VERSION "created by canmatrix"

NS_ :

BS_:

BU_: MD1_ECM ETC NODE_5 BSM_EBS RM_IRCS IC_Multic SGW BCM_NBM VCM NODE_31 ETS NODE_45 FCCU DICO NODE_72 FMReceiver SGW2 VCU ADCU MRGEN DTCO MBMS TPMS AI_CAID ELC ELC_R NODE_F7 BMS3 TUROLLA PCM SRR_Front_Left SRR_Rear_Right SRR_Front_Right SRR_Front SRR_Rear_Left ELFA3_S THERMOKING_M TMU_HP_Rr NODE_B1 NODE_B2 NODE_B3 NODE_B4 NODE_B5 NODE_B6 NODE_B7 NODE_B8 BMS2 NODE_B9 NODE_BA NODE_FC NODE_BB NODE_BC NODE_BE NODE_BD NODE_BF ACU NODE_C0 BMS1 NODE_C1 FCU NODE_C3 NODE_C4 NODE_EC NODE_C5 NODE_C6 NODE_C7 NODE_C8 VCU2 NODE_CA NODE_CB NODE_CD NODE_CE NODE_CF NODE_ED ST_ScanTool MASTER68_STD1 NODE_D1 NODE_F2 NODE_FD NODE_D2 MCSL NODE_EB NODE_D3 NODE_D4 NODE_D5 NODE_D6 VCCU NODE_D8 NODE_D9 NODE_F9 DiagTool NODE_DA NODE_DB NODE_DC NODE_DD NODE_DE NODE_DF NODE_E0 NODE_E1 NODE_E2 NODE_E9 NODE_E3 SAS NODE_FB NODE_F8 NODE_E6 ELFA3 NODE_F THERMOKING_D FMS MULTIC_S MULTIC_2 BMS4 BMS5 BMS6 BMS7 BMS8 BMS9 BMS10 BMS11 NODE_71

BO_ 2566870597 Telemat_3: 8 NODE_45
 SG_ DCDC_12V_ConvFault : 58|1@1+ (1,0) [0|1] ""  PCM
 SG_ OverheatingComprElec : 57|1@1+ (1,0) [0|1] ""  PCM
 SG_ AirDryerSts : 56|1@1+ (1,0) [0|1] ""  PCM
 SG_ LastDoor4CmdCode : 48|8@1+ (1,0) [0|250] ""  PCM
 SG_ LastDoor3CmdCode : 40|8@1+ (1,0) [0|250] ""  PCM
 SG_ LastDoor2CmdCode : 32|8@1+ (1,0) [0|250] ""  PCM
 SG_ LastDoor1CmdCode : 24|8@1+ (1,0) [0|250] ""  PCM
 SG_ Door4ActvInEmerMode : 23|1@1+ (1,0) [0|1] ""  PCM
 SG_ Door3ActvInEmerMode : 22|1@1+ (1,0) [0|1] ""  PCM
 SG_ Door2ActvInEmerMode : 21|1@1+ (1,0) [0|1] ""  PCM
 SG_ Door1ActvInEmerMode : 20|1@1+ (1,0) [0|1] ""  PCM
 SG_ Door4EmerInh : 19|1@1+ (1,0) [0|1] ""  PCM
 SG_ Door3EmerInh : 18|1@1+ (1,0) [0|1] ""  PCM
 SG_ Door2EmerInh : 17|1@1+ (1,0) [0|1] ""  PCM
 SG_ Door1EmerInh : 16|1@1+ (1,0) [0|1] ""  PCM
 SG_ EmerBtnSts : 13|1@1+ (1,0) [0|1] ""  PCM
 SG_ FipoSts : 11|2@1+ (1,0) [0|3] ""  PCM
 SG_ FaeSts : 9|2@1+ (1,0) [0|3] ""  PCM
 SG_ ParkBrkSwFullyApplied : 8|1@1+ (1,0) [0|1] ""  PCM
 SG_ HeatSysHighTempFault : 7|1@1+ (1,0) [0|1] ""  PCM
 SG_ HeatFuelLowLev : 6|1@1+ (1,0) [0|1] ""  PCM
 SG_ HeatLiquidLowLev : 5|1@1+ (1,0) [0|1] ""  PCM
 SG_ VehMode : 0|3@1+ (1,0) [0|7] ""  PCM

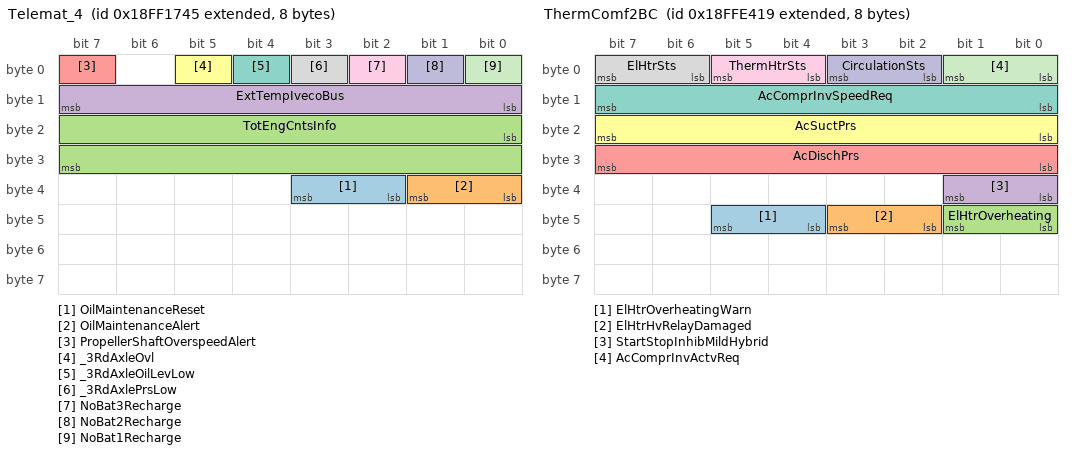
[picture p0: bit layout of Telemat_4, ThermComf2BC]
BO_ 2566854469 Telemat_4: 8 NODE_45
 SG_ OilMaintenanceReset : 34|2@1+ (1,0) [0|3] ""  PCM
 SG_ OilMaintenanceAlert : 32|2@1+ (1,0) [0|3] ""  PCM
 SG_ TotEngCntsInfo : 16|16@1+ (100,0) [0|6553500] "Cycles"  PCM
 SG_ ExtTempIvecoBus : 8|8@1+ (1,-40) [-40|210] "°C"  PCM
 SG_ PropellerShaftOverspeedAlert : 7|1@1+ (1,0) [0|1] ""  PCM
 SG_ _3RdAxleOvl : 5|1@1+ (1,0) [0|1] ""  PCM
 SG_ _3RdAxleOilLevLow : 4|1@1+ (1,0) [0|1] ""  PCM
 SG_ _3RdAxlePrsLow : 3|1@1+ (1,0) [0|1] ""  PCM
 SG_ NoBat3Recharge : 2|1@1+ (1,0) [0|1] ""  PCM
 SG_ NoBat2Recharge : 1|1@1+ (1,0) [0|1] ""  PCM
 SG_ NoBat1Recharge : 0|1@1+ (1,0) [0|1] ""  PCM

BO_ 2566906905 ThermComf2BC: 8 THERMOKING_M
 SG_ ElHtrOverheatingWarn : 44|2@1+ (1,0) [0|3] ""  PCM
 SG_ ElHtrHvRelayDamaged : 42|2@1+ (1,0) [0|3] ""  PCM
 SG_ ElHtrOverheating : 40|2@1+ (1,0) [0|3] ""  PCM
 SG_ StartStopInhibMildHybrid : 32|2@1+ (1,0) [0|3] ""  PCM
 SG_ AcDischPrs : 24|8@1+ (16,0) [0|4000] "kPa"  PCM
 SG_ AcSuctPrs : 16|8@1+ (16,0) [0|4000] "kPa"  PCM
 SG_ AcComprInvSpeedReq : 8|8@1+ (1,0) [0|250] "Hz"  PCM
 SG_ ElHtrSts : 6|2@1+ (1,0) [0|3] ""  PCM
 SG_ ThermHtrSts : 4|2@1+ (1,0) [0|3] ""  PCM
 SG_ CirculationSts : 2|2@1+ (1,0) [0|3] ""  PCM
 SG_ AcComprInvActvReq : 0|2@1+ (1,0) [0|3] ""  PCM

BO_ 2566846467 TRF1: 8 ETC
 SG_ TransmOilTemp1 : 32|16@1+ (0.03125,-273) [-273|1734.96875] "°C"  PCM

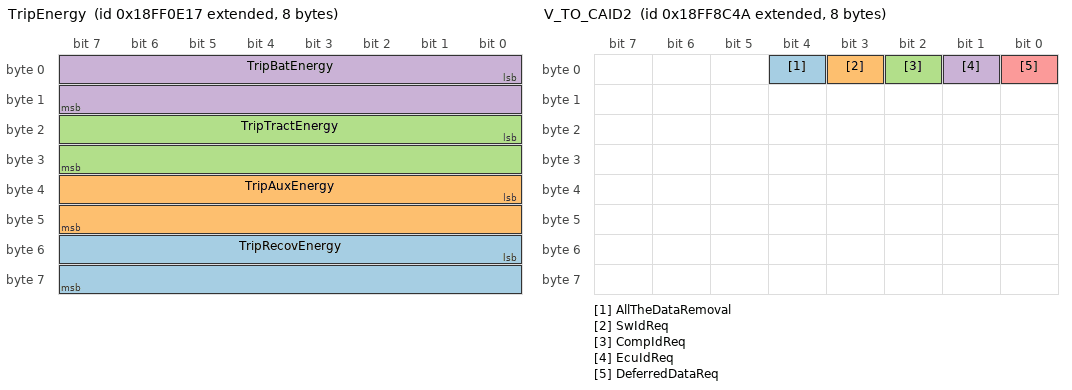
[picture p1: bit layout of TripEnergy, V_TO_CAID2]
BO_ 2566852119 TripEnergy: 8 IC_Multic
 SG_ TripRecovEnergy : 48|16@1+ (1,0) [0|65535] "kWh"  PCM
 SG_ TripAuxEnergy : 32|16@1+ (1,0) [0|65535] "kWh"  PCM
 SG_ TripTractEnergy : 16|16@1+ (1,0) [0|65535] "kWh"  PCM
 SG_ TripBatEnergy : 0|16@1+ (1,0) [0|65535] "kWh"  PCM

BO_ 2566856261 TripEnergy2: 8 NODE_45
 SG_ TripNet24VEnergy : 16|16@1+ (1,0) [0|64255] "kWh"  PCM
 SG_ TripAcEnergy : 0|16@1+ (1,0) [0|64255] "kWh"  PCM

BO_ 2566749463 TTS: 8 IC_Multic
 SG_ LdwSwdOff m3 : 60|3@1+ (1,0) [0|7] ""  PCM
 SG_ EngCompTemp m2 : 60|3@1+ (1,0) [0|7] ""  PCM
 SG_ SteerFluidLev m1 : 60|3@1+ (1,0) [0|7] ""  PCM
 SG_ FrontFogLight m0 : 60|3@1+ (1,0) [0|7] ""  PCM
 SG_ EscSwdOff m3 : 56|3@1+ (1,0) [0|7] ""  PCM
 SG_ Kneel m2 : 56|3@1+ (1,0) [0|7] ""  PCM
 SG_ EngCoolLev m1 : 56|3@1+ (1,0) [0|7] ""  PCM
 SG_ PosLightSideLight m0 : 56|3@1+ (1,0) [0|7] ""  PCM
 SG_ TcoInd m3 : 52|3@1+ (1,0) [0|7] ""  PCM
 SG_ Low m2 : 52|3@1+ (1,0) [0|7] ""  PCM
 SG_ EngOilLev_FD7D17 m1 : 52|3@1+ (1,0) [0|7] ""  PCM
 SG_ EngOil m0 : 52|3@1+ (1,0) [0|7] ""  PCM
 SG_ EbsTrail12 m3 : 48|3@1+ (1,0) [0|7] ""  PCM
 SG_ Raising m2 : 48|3@1+ (1,0) [0|7] ""  PCM
 SG_ EngOilTemp m1 : 48|3@1+ (1,0) [0|7] ""  PCM
 SG_ BatChgCond m0 : 48|3@1+ (1,0) [0|7] ""  PCM
 SG_ Airbag m3 : 44|3@1+ (1,0) [0|7] ""  PCM
 SG_ AdblueLev m2 : 44|3@1+ (1,0) [0|7] ""  PCM
 SG_ Malf_GenFail m1 : 44|3@1+ (1,0) [0|7] ""  PCM
 SG_ EngCoolTemp_FD7D17 m0 : 44|3@1+ (1,0) [0|7] ""  PCM
 SG_ AbsTrail12 m3 : 40|3@1+ (1,0) [0|7] ""  PCM
 SG_ BusStopBrk m2 : 40|3@1+ (1,0) [0|7] ""  PCM
 SG_ TireFail_Malf m1 : 40|3@1+ (1,0) [0|7] ""  PCM
 SG_ FuelLev m0 : 40|3@1+ (1,0) [0|7] ""  PCM
 SG_ BatPakCool m4 : 36|3@1+ (1,0) [0|7] ""  PCM
 SG_ TrailConn m3 : 36|3@1+ (1,0) [0|7] ""  PCM
 SG_ PramReq m2 : 36|3@1+ (1,0) [0|7] ""  PCM
 SG_ Windsh_WindshWasherFluid m1 : 36|3@1+ (1,0) [0|7] ""  PCM
 SG_ HatchOpen m0 : 36|3@1+ (1,0) [0|7] ""  PCM
 SG_ LimPerfElMot m4 : 32|3@1+ (1,0) [0|7] ""  PCM
 SG_ Acc m3 : 32|3@1+ (1,0) [0|7] ""  PCM
 SG_ StopReq m2 : 32|3@1+ (1,0) [0|7] ""  PCM
 SG_ WornBrkLin m1 : 32|3@1+ (1,0) [0|7] ""  PCM
 SG_ BrkFail_BrkSysMalf m0 : 32|3@1+ (1,0) [0|7] ""  PCM
 SG_ BatPakTemp m4 : 28|3@1+ (1,0) [0|7] ""  PCM
 SG_ Aebs m3 : 28|3@1+ (1,0) [0|7] ""  PCM
 SG_ Artic m2 : 28|3@1+ (1,0) [0|7] ""  PCM
 SG_ AntiLckBrkSysFail m1 : 28|3@1+ (1,0) [0|7] ""  PCM
 SG_ ParkBrk m0 : 28|3@1+ (1,0) [0|7] ""  PCM
 SG_ highVsysCaution m4 : 24|3@1+ (1,0) [0|7] ""  PCM
 SG_ LaneDepInd m3 : 24|3@1+ (1,0) [0|7] ""  PCM
 SG_ BrkLight m2 : 24|3@1+ (1,0) [0|7] ""  PCM
 SG_ TransmFail_Malf m1 : 24|3@1+ (1,0) [0|7] ""  PCM
 SG_ ProvDisOrHandiPers m0 : 24|3@1+ (1,0) [0|7] ""  PCM
 SG_ BatPak m4 : 20|3@1+ (1,0) [0|7] ""  PCM
 SG_ Ebs m3 : 20|3@1+ (1,0) [0|7] ""  PCM
 SG_ EscInd m2 : 20|3@1+ (1,0) [0|7] ""  PCM
 SG_ TransmFluidTemp m1 : 20|3@1+ (1,0) [0|7] ""  PCM
 SG_ HazardWarn m0 : 20|3@1+ (1,0) [0|7] ""  PCM
 SG_ MuxSys m4 : 16|3@1+ (1,0) [0|7] ""  PCM
 SG_ SeatBelt m3 : 16|3@1+ (1,0) [0|7] ""  PCM
 SG_ EngEmisSysFailMil m2 : 16|3@1+ (1,0) [0|7] ""  PCM
 SG_ ServCallForMaint m1 : 16|3@1+ (1,0) [0|7] ""  PCM
 SG_ TurnSigs m0 : 16|3@1+ (1,0) [0|7] ""  PCM
 SG_ AdblueTamp m4 : 12|3@1+ (1,0) [0|7] ""  PCM
 SG_ FuelFiltDiffPrs m3 : 12|3@1+ (1,0) [0|7] ""  PCM
 SG_ Ret m2 : 12|3@1+ (1,0) [0|7] ""  PCM
 SG_ Eng_Mil m1 : 12|3@1+ (1,0) [0|7] ""  PCM
 SG_ LowBeamDipBeam m0 : 12|3@1+ (1,0) [0|7] ""  PCM
 SG_ ElMotFails m4 : 8|3@1+ (1,0) [0|7] ""  PCM
 SG_ AirFiltClog m3 : 8|3@1+ (1,0) [0|7] ""  PCM
 SG_ HtCtrl m2 : 8|3@1+ (1,0) [0|7] ""  PCM
 SG_ ParkHeat m1 : 8|3@1+ (1,0) [0|7] ""  PCM
 SG_ HighBeamMainBeam m0 : 8|3@1+ (1,0) [0|7] ""  PCM
 SG_ EngEmisFilt m4 : 4|3@1+ (1,0) [0|7] ""  PCM
 SG_ AuxAirPrs m3 : 4|3@1+ (1,0) [0|7] ""  PCM
 SG_ SteerFail m2 : 4|3@1+ (1,0) [0|7] ""  PCM
 SG_ RearFogLight m1 : 4|3@1+ (1,0) [0|7] ""  PCM
 SG_ CoolAc m0 : 4|3@1+ (1,0) [0|7] ""  PCM
 SG_ TtBlkId M : 0|4@1+ (1,0) [0|15] ""  PCM

BO_ 2566884426 V_TO_CAID2: 8 PCM
 SG_ AllTheDataRemoval : 4|1@1+ (1,0) [0|1] "" Vector__XXX
 SG_ SwIdReq : 3|1@1+ (1,0) [0|1] "" Vector__XXX
 SG_ CompIdReq : 2|1@1+ (1,0) [0|1] "" Vector__XXX
 SG_ EcuIdReq : 1|1@1+ (1,0) [0|1] "" Vector__XXX
 SG_ DeferredDataReq : 0|1@1+ (1,0) [0|1] "" Vector__XXX

BO_ 2566877568 VCU2MUX_FC: 8 VCU
 SG_ FCU2_8_FC_Consump : 48|16@1+ (0.01,0) [0|655.35] "mg"  PCM
 SG_ FillAuthorizDueToSafetyReas : 47|1@1+ (1,0) [0|1] ""  PCM
 SG_ NrTanksOpenH2_RdyToProvide2FC : 44|3@1+ (1,0) [0|7] ""  PCM
 SG_ FC_Mode_ReqBySupervisor : 40|4@1+ (1,0) [0|15] ""  PCM
 SG_ HV_DC_Link_Sts : 39|1@1+ (1,0) [0|1] ""  PCM
 SG_ LimpHomeMode : 36|1@1+ (1,0) [0|1] ""  PCM
 SG_ H2_Circuit_Sts : 32|4@1+ (1,0) [0|15] ""  PCM
 SG_ FC_Sts_SupervisorSide : 28|4@1+ (1,0) [0|15] ""  PCM
 SG_ H2_Sensor4LeakageSts : 27|1@1+ (1,0) [0|1] ""  PCM
 SG_ H2_Sensor3LeakageSts : 26|1@1+ (1,0) [0|1] ""  PCM
 SG_ H2_Sensor2LeakageSts : 25|1@1+ (1,0) [0|1] ""  PCM
 SG_ H2_Sensor1LeakageSts : 24|1@1+ (1,0) [0|1] ""  PCM
 SG_ H2ConctValExc4Pc_RslR134 : 23|1@1+ (1,0) [0|1] ""  PCM
 SG_ H2ConctValExc3Pc_AwlR134 : 22|1@1+ (1,0) [0|1] ""  PCM
 SG_ FC_Act_DeacStsDashbDisplay : 20|2@1+ (1,0) [0|3] ""  PCM
 SG_ VCU_TkClosEmrgShtDwnRq_FC1 : 19|1@1+ (1,0) [0|1] ""  PCM
 SG_ VCU_HV_FtEmrgShtDwnRq_FC1 : 18|1@1+ (1,0) [0|1] ""  PCM
 SG_ FCU2_7_FC_StopState : 16|2@1+ (1,0) [0|3] ""  PCM
 SG_ FCU2_7_FC_StopImposs : 14|2@1+ (1,0) [0|3] ""  PCM
 SG_ FCU2_5_FC_Fault : 13|1@1+ (1,0) [0|1] ""  PCM
 SG_ FCU2_5_FC_Shutdown : 11|2@1+ (1,0) [0|3] ""  PCM
 SG_ FCU2_5_FC_LoadPermmit : 10|1@1+ (1,0) [0|1] ""  PCM
 SG_ FCU2_5_FC_Startup : 8|2@1+ (1,0) [0|3] ""  PCM
 SG_ VCU_FC_CoolantLevLow : 7|1@1+ (1,0) [0|1] ""  PCM
 SG_ FuelCellSwON_OFF : 6|1@1+ (1,0) [0|1] ""  PCM
 SG_ FCU2_H2TankValveEmrgClos : 5|1@1+ (1,0) [0|1] ""  PCM
 SG_ FCU2_HV_InterlockReactRq : 4|1@1+ (1,0) [0|1] ""  PCM
 SG_ FCU2_5_H2FaultLamp : 3|1@1+ (1,0) [0|1] ""  PCM
 SG_ FCU2_8_H2LeakLamp : 1|2@1+ (1,0) [0|3] ""  PCM

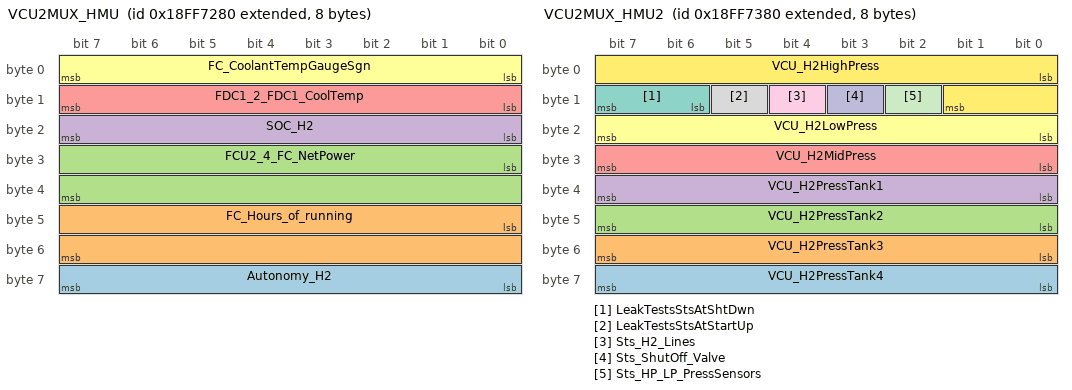
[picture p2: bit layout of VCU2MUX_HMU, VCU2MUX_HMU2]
BO_ 2566877824 VCU2MUX_HMU: 8 VCU
 SG_ Autonomy_H2 : 56|8@1+ (2,0) [0|510] "km"  PCM
 SG_ FC_Hours_of_running : 40|16@1+ (1,0) [0|65536] "h"  PCM
 SG_ FCU2_4_FC_NetPower : 24|16@1+ (0.1,0) [0|255] "kW"  PCM
 SG_ SOC_H2 : 16|8@1+ (0.4,0) [0|100] "%"  PCM
 SG_ FDC1_2_FDC1_CoolTemp : 8|8@1+ (1,-40) [-40|200] "°C"  PCM
 SG_ FC_CoolantTempGaugeSgn : 0|8@1+ (0.5,-30) [-30|97.5] "°C"  PCM

BO_ 2566878080 VCU2MUX_HMU2: 8 VCU
 SG_ VCU_H2PressTank4 : 56|8@1+ (1.5,0) [0|379.5] "bar"  PCM
 SG_ VCU_H2PressTank3 : 48|8@1+ (1.5,0) [0|379.5] "bar"  PCM
 SG_ VCU_H2PressTank2 : 40|8@1+ (1.5,0) [0|379.5] "bar"  PCM
 SG_ VCU_H2PressTank1 : 32|8@1+ (1.5,0) [0|379.5] "bar"  PCM
 SG_ VCU_H2MidPress : 24|8@1+ (0.2,0) [0|51] "bar"  PCM
 SG_ VCU_H2LowPress : 16|8@1+ (0.2,0) [0|51] "bar"  PCM
 SG_ LeakTestsStsAtShtDwn : 14|2@1+ (1,0) [0|3] ""  PCM
 SG_ LeakTestsStsAtStartUp : 13|1@1+ (1,0) [0|1] ""  PCM
 SG_ Sts_H2_Lines : 12|1@1+ (1,0) [0|1] ""  PCM
 SG_ Sts_ShutOff_Valve : 11|1@1+ (1,0) [0|1] ""  PCM
 SG_ Sts_HP_LP_PressSensors : 10|1@1+ (1,0) [0|1] ""  PCM
 SG_ VCU_H2HighPress : 0|10@1+ (0.5,0) [0|511.5] "bar"  PCM

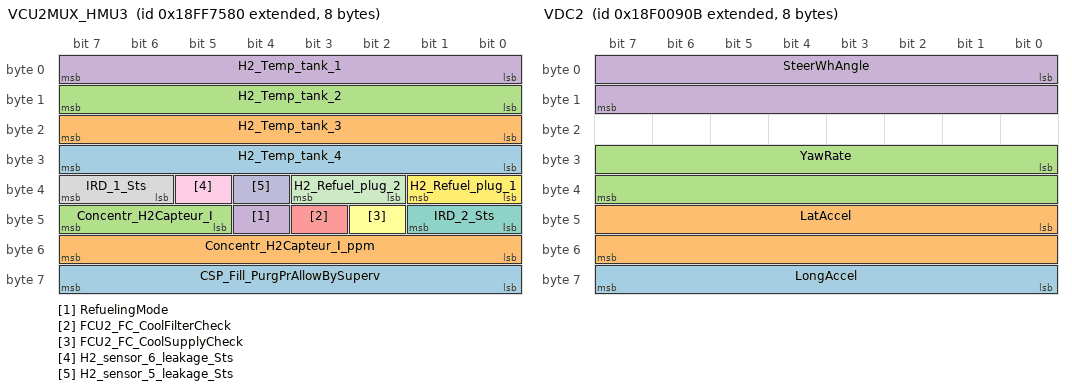
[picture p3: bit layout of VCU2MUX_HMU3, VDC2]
BO_ 2566878592 VCU2MUX_HMU3: 8 VCU
 SG_ CSP_Fill_PurgPrAllowBySuperv : 56|8@1+ (1,0) [0|250] ""  PCM
 SG_ Concentr_H2Capteur_I_ppm : 48|8@1+ (1,0) [0|250] ""  PCM
 SG_ Concentr_H2Capteur_I : 45|3@1+ (1,0) [0|7] ""  PCM
 SG_ RefuelingMode : 44|1@1+ (1,0) [0|1] ""  PCM
 SG_ FCU2_FC_CoolFilterCheck : 43|1@1+ (1,0) [0|1] ""  PCM
 SG_ FCU2_FC_CoolSupplyCheck : 42|1@1+ (1,0) [0|1] ""  PCM
 SG_ IRD_2_Sts : 40|2@1+ (1,0) [0|3] ""  PCM
 SG_ IRD_1_Sts : 38|2@1+ (1,0) [0|3] ""  PCM
 SG_ H2_sensor_6_leakage_Sts : 37|1@1+ (1,0) [0|1] ""  PCM
 SG_ H2_sensor_5_leakage_Sts : 36|1@1+ (1,0) [0|1] ""  PCM
 SG_ H2_Refuel_plug_2 : 34|2@1+ (1,0) [0|3] ""  PCM
 SG_ H2_Refuel_plug_1 : 32|2@1+ (1,0) [0|3] ""  PCM
 SG_ H2_Temp_tank_4 : 24|8@1+ (1,-40) [-40|200] "°C"  PCM
 SG_ H2_Temp_tank_3 : 16|8@1+ (1,-40) [-40|200] "°C"  PCM
 SG_ H2_Temp_tank_2 : 8|8@1+ (1,-40) [-40|200] "°C"  PCM
 SG_ H2_Temp_tank_1 : 0|8@1+ (1,-40) [-40|200] "°C"  PCM

BO_ 2566803211 VDC1: 8 BSM_EBS
 SG_ VdcFullyOp : 2|2@1+ (1,0) [0|3] ""  PCM
 SG_ VdcInfoSig : 0|2@1+ (1,0) [0|3] ""  PCM

BO_ 2565867787 VDC2: 8 BSM_EBS
 SG_ LongAccel : 56|8@1+ (0.1,-12.5) [-12.5|12.5] "m/s²"  PCM
 SG_ LatAccel : 40|16@1+ (0.00048828125,-15.687) [-15.687|15.687] "m/s²"  PCM
 SG_ YawRate : 24|16@1+ (0.0001220703125,-3.92) [-3.92|3.92] "rad/s"  PCM
 SG_ SteerWhAngle : 0|16@1+ (0.0009765625,-31.374) [-31.374|31.374] "rad"  PCM

BO_ 2566832622 VDHR: 8 DTCO
 SG_ TripDistHr : 32|32@1+ (5,0) [0|21055406075] "m"  PCM
 SG_ TotVehDistHr : 0|32@1+ (5,0) [0|21055406075] "m"  PCM

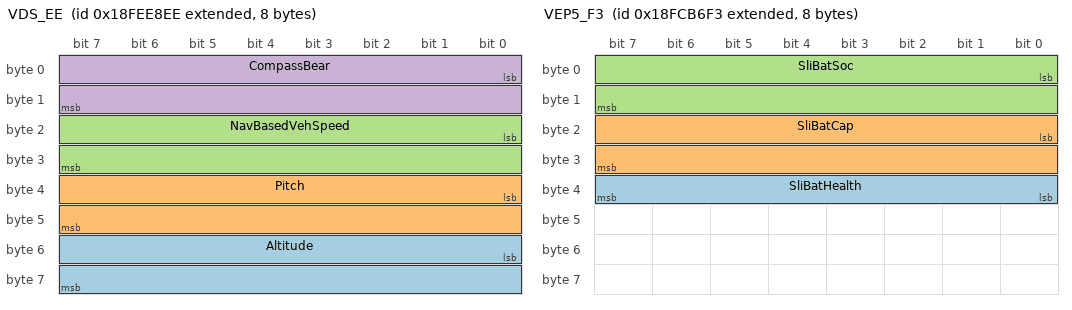
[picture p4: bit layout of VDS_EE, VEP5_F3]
BO_ 2566842606 VDS_EE: 8 DTCO
 SG_ Altitude : 48|16@1+ (0.125,-2500) [-2500|5531.875] "m"  PCM
 SG_ Pitch : 32|16@1+ (0.0078125,-200) [-200|301.99] "deg"  PCM
 SG_ NavBasedVehSpeed : 16|16@1+ (0.00390625,0) [0|250.996] "km/h"  PCM
 SG_ CompassBear : 0|16@1+ (0.0078125,0) [0|501.99] "deg"  PCM

BO_ 2566846208 VEP1_00: 8 MD1_ECM
 SG_ BatPot_PwrIn1 : 32|16@1+ (0.05,0) [0|3212.75] "V"  PCM

BO_ 2566846451 VEP1_F3: 8 MBMS
 SG_ BatPot_PwrIn1_FEF7F3 : 32|16@1+ (0.05,0) [0|3212.75] "V"  PCM

BO_ 2566804211 VEP3_F3: 8 MBMS
 SG_ SliBat1NetCurHr : 16|16@1+ (0.05,-1600) [-1600|1612.75] "A"  PCM

BO_ 2566698739 VEP5_F3: 8 MBMS
 SG_ SliBatHealth : 32|8@1+ (0.5,0) [0|125] "%"  PCM
 SG_ SliBatCap : 16|16@1+ (1,0) [0|64255] "Ah"  PCM
 SG_ SliBatSoc : 0|16@1+ (0.0025,0) [0|160.6375] "%"  PCM

BO_ 2566843630 VI_EE: 18 DTCO
 SG_ Vin : 0|8@1+ (1,0) [0|255] "ASCII"  PCM

BO_ 2566845212 VP1_1C: 8 PCM
 SG_ Long : 32|32@1+ (1E-007,-210) [-210|211.1081215] "deg" Vector__XXX
 SG_ Lat : 0|32@1+ (1E-007,-210) [-210|211.1081215] "deg" Vector__XXX

BO_ 2566845422 VP1_EE: 8 DTCO
 SG_ Long_FEF3EE : 32|32@1+ (1E-007,-210) [-210|211.1081215] "deg"  PCM
 SG_ Lat_FEF3EE : 0|32@1+ (1E-007,-210) [-210|211.1081215] "deg"  PCM

BO_ 2566842927 VW_2F_Test: 8 ELC
 SG_ Axle_Weight_5 m4 : 8|16@1+ (0.5,0) [0|32127.5] "kg"  PCM
 SG_ Axle_Weight_4 m3 : 8|16@1+ (0.5,0) [0|32127.5] "kg"  PCM
 SG_ Axle_Weight_3 m2 : 8|16@1+ (0.5,0) [0|32127.5] "kg"  PCM
 SG_ Axle_Weight_2 m1 : 8|16@1+ (0.5,0) [0|32127.5] "kg"  PCM
 SG_ Axle_Weight_1 m0 : 8|16@1+ (0.5,0) [0|32127.5] "kg"  PCM
 SG_ Axle_Location M : 4|4@1+ (1,0) [0|15] ""  PCM

BO_ 2566842944 VW_40_Test: 8 ELC_R
 SG_ Axle_Weight_5_FEEA40 m4 : 8|16@1+ (0.5,0) [0|32127.5] "kg"  PCM
 SG_ Axle_Weight_4_FEEA40 m3 : 8|16@1+ (0.5,0) [0|32127.5] "kg"  PCM
 SG_ Axle_Weight_3_FEEA40 m2 : 8|16@1+ (0.5,0) [0|32127.5] "kg"  PCM
 SG_ Axle_Weight_2_FEEA40 m1 : 8|16@1+ (0.5,0) [0|32127.5] "kg"  PCM
 SG_ Axle_Weight_1_FEEA40 m0 : 8|16@1+ (0.5,0) [0|32127.5] "kg"  PCM
 SG_ Axle_Location_FEEA40 M : 4|4@1+ (1,0) [0|15] ""  PCM

BO_ 2566848256 WFI: 8 MD1_ECM
 SG_ WaterInFuelInd1 : 0|2@1+ (1,0) [0|3] ""  PCM

BO_ 2349075360 XBR_A0_0B: 8 MRGEN
 SG_ XbrMsgCnt : 56|4@1+ (1,0) [0|15] "count"  PCM,BSM_EBS

BO_ 2566845436 VP_FC: 8 NODE_FC
 SG_ Long_FEF3FC : 32|32@1+ (1E-007,-210) [-210|211.1081215] "deg"  PCM
 SG_ Lat_FEF3FC : 0|32@1+ (1E-007,-210) [-210|211.1081215] "deg"  PCM

BO_ 2565472330 RQST_4A_00: 3 PCM
 SG_ PgnRqst_4A_00 : 0|24@1+ (1,0) [0|16777215] ""  MD1_ECM

BO_ 2565482314 RQST_4A_27: 3 PCM
 SG_ PgnRqst_4A_27 : 0|24@1+ (1,0) [0|16777215] ""  VCM

BO_ 2565478218 RQST_4A_17: 3 PCM
 SG_ PgnRqst_4A_17 : 0|24@1+ (1,0) [0|16777215] ""  IC_Multic

BO_ 2565473098 RQST_4A_03: 3 PCM
 SG_ PgnRqst_4A_03 : 0|24@1+ (1,0) [0|16777215] ""  ETC

BO_ 2565475146 RQST_4A_0B: 3 PCM
 SG_ PgnRqst_4A_0B : 0|24@1+ (1,0) [0|16777215] ""  BSM_EBS

BO_ 2565479754 RQST_4A_1D: 3 PCM
 SG_ PgnRqst_4A_1D : 0|24@1+ (1,0) [0|16777215] ""  SGW

BO_ 2565486666 RQST_4A_38: 3 PCM
 SG_ PgnRqst_4A_38 : 0|24@1+ (1,0) [0|16777215] ""  ETS

BO_ 2565504586 RQST_4A_7E: 3 PCM
 SG_ PgnRqst_4A_7E : 0|24@1+ (1,0) [0|16777215] ""  SGW2

BO_ 2565512778 RQST_4A_9E: 3 PCM
 SG_ PgnRqst_4A_9E : 0|24@1+ (1,0) [0|16777215] ""  ADCU

BO_ 2565513290 RQST_4A_A0: 3 PCM
 SG_ PgnRqst_4A_A0 : 0|24@1+ (1,0) [0|16777215] ""  MRGEN

BO_ 2565480778 RQST_4A_21: 3 PCM
 SG_ PgnRqst_4A_21 : 0|24@1+ (1,0) [0|16777215] ""  BCM_NBM

BO_ 2565496394 RQST_4A_5E: 3 PCM
 SG_ PgnRqst_4A_5E : 0|24@1+ (1,0) [0|16777215] ""  AI_CAID

BO_ 2565495370 RQST_4A_5A: 3 PCM
 SG_ PgnRqst_4A_5A : 0|24@1+ (1,0) [0|16777215] ""  DICO

BO_ 2565484362 RQST_4A_2F: 3 PCM
 SG_ PgnRqst_4A_2F : 0|24@1+ (1,0) [0|16777215] ""  ELC

BO_ 2565488714 RQST_4A_40: 3 PCM
 SG_ PgnRqst_4A_40 : 0|24@1+ (1,0) [0|16777215] ""  ELC_R

BO_ 2565535562 RQST_4A_F7: 3 PCM
 SG_ PgnRqst_4A_F7 : 0|24@1+ (1,0) [0|16777215] ""  NODE_F7

BO_ 2565535306 RQST_4A_F6: 3 PCM
 SG_ PgnRqst_4A_F6 : 0|24@1+ (1,0) [0|16777215] ""  BMS3

BO_ 2565534538 RQST_4A_F3: 3 PCM
 SG_ PgnRqst_4A_F3 : 0|24@1+ (1,0) [0|16777215] ""  MBMS

BO_ 2565491018 RQST_4A_49: 3 PCM
 SG_ PgnRqst_4A_49 : 0|24@1+ (1,0) [0|16777215] ""  FCCU

BO_ 2565476426 RQST_4A_10: 3 PCM
 SG_ PgnRqst_4A_10 : 0|24@1+ (1,0) [0|16777215] ""  RM_IRCS

BO_ 2565484106 RQST_4A_2E: 3 PCM
 SG_ PgnRqst_4A_2E : 0|24@1+ (1,0) [0|16777215] ""  TUROLLA

BO_ 2565509194 RQST_4A_90: 3 PCM
 SG_ PgnRqst_4A_90 : 0|24@1+ (1,0) [0|16777215] ""  SRR_Front_Left

BO_ 2565509450 RQST_4A_91: 3 PCM
 SG_ PgnRqst_4A_91 : 0|24@1+ (1,0) [0|16777215] ""  SRR_Rear_Right

BO_ 2565509706 RQST_4A_92: 3 PCM
 SG_ PgnRqst_4A_92 : 0|24@1+ (1,0) [0|16777215] ""  SRR_Front_Right

BO_ 2565512266 RQST_4A_9C: 3 PCM
 SG_ PgnRqst_4A_9C : 0|24@1+ (1,0) [0|16777215] ""  SRR_Front

BO_ 2565531722 RQST_4A_E8: 3 PCM
 SG_ PgnRqst_4A_E8 : 0|24@1+ (1,0) [0|16777215] ""  SRR_Rear_Left

BO_ 2565533770 RQST_4A_F0: 3 PCM
 SG_ PgnRqst_4A_F0 : 0|24@1+ (1,0) [0|16777215] ""  ELFA3_S

BO_ 2565478730 RQST_4A_19: 3 PCM
 SG_ PgnRqst_4A_19 : 0|24@1+ (1,0) [0|16777215] ""  THERMOKING_M

BO_ 2565487178 RQST_4A_3A: 3 PCM
 SG_ PgnRqst_4A_3A : 0|24@1+ (1,0) [0|16777215] ""  TMU_HP_Rr

BO_ 2565505098 RQST_4A_80: 3 PCM
 SG_ PgnRqst_4A_80 : 0|24@1+ (1,0) [0|16777215] ""  VCU

BO_ 2565489994 RQST_4A_45: 3 PCM
 SG_ PgnRqst_4A_45 : 0|24@1+ (1,0) [0|16777215] ""  NODE_45

BO_ 2565501514 RQST_4A_72: 3 PCM
 SG_ PgnRqst_4A_72 : 0|24@1+ (1,0) [0|16777215] ""  NODE_72

BO_ 2565476170 RQST_4A_0F: 3 PCM
 SG_ PgnRqst_4A_0F : 0|24@1+ (1,0) [0|16777215] ""  NODE_F

BO_ 2565533514 RQST_4A_EF: 3 PCM
 SG_ PgnRqst_4A_EF : 0|24@1+ (1,0) [0|16777215] ""  ELFA3

BO_ 2565531466 RQST_4A_E7: 3 PCM
 SG_ PgnRqst_4A_E7 : 0|24@1+ (1,0) [0|16777215] ""  ACU

BO_ 2565501258 RQST_4A_71: 3 PCM
 SG_ PgnRqst_4A_71 : 0|24@1+ (1,0) [0|16777215] ""  NODE_71

BO_ 2565537610 RQST_4A_FF: 3 PCM
 SG_ PgnRqst_4A_FF : 0|24@1+ (1,0) [0|16777215] "" Vector__XXX

BO_ 2566913797 PH_05: 3 NODE_5
 SG_ PlaceHolder_05 : 0|8@1+ (1,0) [0|250] ""  PCM

BO_ 2566913841 PH_31: 3 NODE_31
 SG_ PlaceHolder_31 : 0|8@1+ (1,0) [0|250] ""  PCM

BO_ 2566913909 PH_75: 3 FMReceiver
 SG_ PlaceHolder_75 : 0|8@1+ (1,0) [0|250] ""  PCM

BO_ 2566913818 PH_1A: 3 THERMOKING_D
 SG_ PlaceHolder_1A : 0|8@1+ (1,0) [0|250] ""  PCM

BO_ 2566913829 PH_25: 3 FMS
 SG_ PlaceHolder_25 : 0|8@1+ (1,0) [0|250] ""  PCM

BO_ 2566913888 PH_60: 3 MULTIC_S
 SG_ PlaceHolder_60 : 0|8@1+ (1,0) [0|250] ""  PCM

BO_ 2566913890 PH_62: 3 MULTIC_2
 SG_ PlaceHolder_62 : 0|8@1+ (1,0) [0|250] ""  PCM

BO_ 2566913926 PH_86: 3 BMS4
 SG_ PlaceHolder_86 : 0|8@1+ (1,0) [0|250] ""  PCM

BO_ 2566913927 PH_87: 3 BMS5
 SG_ PlaceHolder_87 : 0|8@1+ (1,0) [0|250] ""  PCM

BO_ 2566913928 PH_88: 3 BMS6
 SG_ PlaceHolder_88 : 0|8@1+ (1,0) [0|250] ""  PCM

BO_ 2566913929 PH_89: 3 BMS7
 SG_ PlaceHolder_89 : 0|8@1+ (1,0) [0|250] ""  PCM

BO_ 2566913930 PH_8A: 3 BMS8
 SG_ PlaceHolder_8A : 0|8@1+ (1,0) [0|250] ""  PCM

BO_ 2566913931 PH_8B: 3 BMS9
 SG_ PlaceHolder_8B : 0|8@1+ (1,0) [0|250] ""  PCM

BO_ 2566913932 PH_8C: 3 BMS10
 SG_ PlaceHolder_8C : 0|8@1+ (1,0) [0|250] ""  PCM

BO_ 2566913933 PH_8D: 3 BMS11
 SG_ PlaceHolder_8D : 0|8@1+ (1,0) [0|250] ""  PCM

CM_ BO_ 2566906905 "- *Not yet confirmed Heat Pump for CW FE. Today is used ECU Clima (like in Thermal engines).
-  [Msg Predisposal]";
CM_ SG_ 2566906905 ThermHtrSts "- Not yet used by the MUX, just for information.";
CM_ BO_ 2566852119 "- Full Elec only. Message FMS14, same ID, moved here.";
CM_ SG_ 2566852119 TripRecovEnergy "- SPN/ID requested by responsible system ECU";
CM_ SG_ 2566852119 TripAuxEnergy "- SPN/ID requested by responsible system ECU";
CM_ SG_ 2566852119 TripTractEnergy "- SPN/ID requested by responsible system ECU";
CM_ SG_ 2566852119 TripBatEnergy "- SPN/ID requested by responsible system ECU";
CM_ BO_ 2566856261 "- Full Elec only / Predisposal";
CM_ BO_ 2566884426 "- The telematics ECU will send 5 requests each 1 second if the CAID doesn’t send the data. After that the telematics ECU will generate an error if the CAID didn’t send the data. At least 2 events must be present in the deferred data in order to consider that it is valid.";
CM_ SG_ 2566877824 FDC1_2_FDC1_CoolTemp "- FDC1_2_FDC1 Coolant Temperature -> FCU 2-11 in GEN 2.5";
CM_ SG_ 2566877824 FC_CoolantTempGaugeSgn "- Not used for GEN2.5 (was used in GEN2.0)";
CM_ SG_ 2566878592 FCU2_FC_CoolFilterCheck "- Not in GEN2.0. FCU2_FuelcellCoolantFilterCheck (FC stack coolant & Ion filter exchange notification)";
CM_ SG_ 2566878592 FCU2_FC_CoolSupplyCheck "- Not in GEN2.0. FCU2_FuelcellCoolantSupplyCheck (FC stack coolant lower level check warning)";
CM_ BO_ 2566803211 "- Optionnal, only if ESP installed.";
CM_ SG_ 2566803211 VdcInfoSig "- VDC lamp status";
CM_ BO_ 2565867787 "- Optionnal, only if ESP installed Transmitted only if EoL enable_ebc2==1";
CM_ BO_ 2566832622 "- If without Tacho then Multic S is Tx. else MulticS is Rx.
- VS2.B.SGW2..23..VDB: Used in freeze frames parameters";
CM_ SG_ 2566832622 TotVehDistHr "- SAE J1939/73 Freeze Frame parameter";
CM_ SG_ 2566842606 Pitch "- DTCO: Not available ‘FFFF’";
CM_ SG_ 2566842606 CompassBear "- DTCO: Not available ‘FFFF’";
CM_ BO_ 2566846208 "- Note: on MF4 (CNG) applications this message is not present";
CM_ SG_ 2566846208 BatPot_PwrIn1 "- Diesel vehicle only!!!??
-  Min value between both DC DC inverters delivered voltages.";
CM_ SG_ 2566846451 BatPot_PwrIn1_FEF7F3 "- Available with NBM";
CM_ BO_ 2566843630 "-  2 Message Variant(s): Transm.Rates 10000, OnRequest
-  Cyclic Transmission Rate as result of PGN requests
-  Multipacket message handled by SAE Transport Protocol (J1939/21, par 5.10, Multipacket Broadcast with TP.CM/BAM, TP.DT)
-  Variable Message Length, maximum value used for dbc generation
-  Multipacket message handled by SAE Transport Protocol (J1939/21, par 5.10, Multipacket Broadcast with TP.CM/BAM, TP.DT)
-  Variable Message Length, maximum value used for dbc generation.
- ADC.ZF.ADCU..2";
CM_ SG_ 2566843630 Vin "- 17 bytes followed by an * delimiter
-  Variable signal length, 8 bits used for dbc generation only";
CM_ BO_ 2566845422 "- BPM.M.MBMS....VDB: Requested after LOG P62";
CM_ BO_ 2566842927 "- Only testing";
CM_ BO_ 2566842944 "- Only testing";
CM_ BO_ 2566848256 "- Diesel vehicle only";
CM_ SG_ 2566848256 WaterInFuelInd1 "- 00 No / 01 Yes / 10 Error / 11 Not available";
CM_ BO_ 2349075360 "- Faster Transmission Rate when active and at least once thereafter.
- CUC.C.PCM..3..TELEM: Optional";
CM_ BO_ 2566845436 "- TCO.C.DTCO..12..V: SA=Any
- TCO.C.DTCO..12..V: Used for Vehicle Speed validation";
BA_DEF_ BO_  "CI_MsgDefinition" STRING ;
BA_DEF_ BO_  "CI_MsgId" INT 0 2147483647;
BA_DEF_ BO_  "CI_MsgName" STRING ;
BA_DEF_ BO_  "GenMsgCycleTime" INT 0 3600000;
BA_DEF_ BO_  "GenMsgCycleTimeFast" INT 0 3600000;
BA_DEF_ BO_  "GenMsgDelayTime" INT 0 3600000;
BA_DEF_ BO_  "GenMsgILSupport" ENUM  "No","Yes";
BA_DEF_ BO_  "GenMsgNrOfRepetition" INT 0 1000000;
BA_DEF_ BO_  "GenMsgRequestable" INT 0 1;
BA_DEF_ BO_  "GenMsgSendType" ENUM  "cyclic","NotUsed","NotUsed","NotUsed","NotUsed","NotUsed","NotUsed","IfActive","noMsgSendType";
BA_DEF_ BO_  "GenMsgStartDelayTime" INT 0 100000;
BA_DEF_ BO_  "TpJ1939VarDlc" ENUM  "No","Yes";
BA_DEF_ BO_  "VFrameFormat" ENUM  "StandardCAN","ExtendedCAN","reserved","J1939PG";
BA_DEF_ SG_  "CI_ParId" STRING ;
BA_DEF_ SG_  "CI_SigId" INT 0 2147483647;
BA_DEF_ SG_  "CI_SigName" STRING ;
BA_DEF_ SG_  "GenSigEVName" STRING ;
BA_DEF_ SG_  "GenSigILSupport" ENUM  "No","Yes";
BA_DEF_ SG_  "GenSigInactiveValue" INT 0 2147483647;
BA_DEF_ SG_  "GenSigSendType" ENUM  "Cyclic","OnWrite","OnWriteWithRepetition","OnChange","OnChangeWithRepetition","IfActive","IfActiveWithRepetition","NoSigSendType";
BA_DEF_ SG_  "GenSigStartValue" INT 0 2147483647;
BA_DEF_ SG_  "GenSigTimeoutTime_ACM_CANAIR" INT 0 3600000;
BA_DEF_ SG_  "GenSigTimeoutTime_ACU" INT 0 3600000;
BA_DEF_ SG_  "GenSigTimeoutTime_ADCU" INT 0 3600000;
BA_DEF_ SG_  "GenSigTimeoutTime_AI_CAID" INT 0 3600000;
BA_DEF_ SG_  "GenSigTimeoutTime_ASM_ELC5_Fr" INT 0 3600000;
BA_DEF_ SG_  "GenSigTimeoutTime_AVAS" INT 0 3600000;
BA_DEF_ SG_  "GenSigTimeoutTime_Av2HP" INT 0 3600000;
BA_DEF_ SG_  "GenSigTimeoutTime_BCM_NBM" INT 0 3600000;
BA_DEF_ SG_  "GenSigTimeoutTime_BSM_EBS" INT 0 3600000;
BA_DEF_ SG_  "GenSigTimeoutTime_DICO" INT 0 3600000;
BA_DEF_ SG_  "GenSigTimeoutTime_DMS" INT 0 3600000;
BA_DEF_ SG_  "GenSigTimeoutTime_EBS_EBR" INT 0 3600000;
BA_DEF_ SG_  "GenSigTimeoutTime_ECM_MD1_D" INT 0 3600000;
BA_DEF_ SG_  "GenSigTimeoutTime_ECM_MD1_G" INT 0 3600000;
BA_DEF_ SG_  "GenSigTimeoutTime_ETC_DiwaNXT" INT 0 3600000;
BA_DEF_ SG_  "GenSigTimeoutTime_ETC_DiwaNXT_MH" INT 0 3600000;
BA_DEF_ SG_  "GenSigTimeoutTime_ETC_Ecolife2" INT 0 3600000;
BA_DEF_ SG_  "GenSigTimeoutTime_FCCU" INT 0 3600000;
BA_DEF_ SG_  "GenSigTimeoutTime_FMS_FMS4" INT 0 3600000;
BA_DEF_ SG_  "GenSigTimeoutTime_FMS_FMS5" INT 0 3600000;
BA_DEF_ SG_  "GenSigTimeoutTime_HVPDU_HV_BOX" INT 0 3600000;
BA_DEF_ SG_  "GenSigTimeoutTime_IC_MulticII" INT 0 3600000;
BA_DEF_ SG_  "GenSigTimeoutTime_IC_MulticS" INT 0 3600000;
BA_DEF_ SG_  "GenSigTimeoutTime_INVEM1_ELFA3" INT 0 3600000;
BA_DEF_ SG_  "GenSigTimeoutTime_MBMS" INT 0 3600000;
BA_DEF_ SG_  "GenSigTimeoutTime_MCSL" INT 0 3600000;
BA_DEF_ SG_  "GenSigTimeoutTime_MPPxPTFE2" INT 0 3600000;
BA_DEF_ SG_  "GenSigTimeoutTime_PCM" INT 0 3600000;
BA_DEF_ SG_  "GenSigTimeoutTime_RDAB_SmtRadio" INT 0 3600000;
BA_DEF_ SG_  "GenSigTimeoutTime_RM_INTD" INT 0 3600000;
BA_DEF_ SG_  "GenSigTimeoutTime_RM_IRCS" INT 0 3600000;
BA_DEF_ SG_  "GenSigTimeoutTime_SAS" INT 0 3600000;
BA_DEF_ SG_  "GenSigTimeoutTime_SGW" INT 0 3600000;
BA_DEF_ SG_  "GenSigTimeoutTime_SGW2" INT 0 3600000;
BA_DEF_ SG_  "GenSigTimeoutTime_TASM_ETS" INT 0 3600000;
BA_DEF_ SG_  "GenSigTimeoutTime_TMU_HP_Fr" INT 0 3600000;
BA_DEF_ SG_  "GenSigTimeoutTime_TMU_HP_Rr" INT 0 3600000;
BA_DEF_ SG_  "GenSigTimeoutTime_TPMS" INT 0 3600000;
BA_DEF_ SG_  "GenSigTimeoutTime_Tacho_DTCO" INT 0 3600000;
BA_DEF_ SG_  "GenSigTimeoutTime_Tacho_MTCO" INT 0 3600000;
BA_DEF_ SG_  "GenSigTimeoutTime_Tacho_TSU" INT 0 3600000;
BA_DEF_ SG_  "GenSigTimeoutTime_VCM" INT 0 3600000;
BA_DEF_ SG_  "GenSigTimeoutTime_VCU" INT 0 3600000;
BA_DEF_ SG_  "GenSigTimeoutTime_VMU" INT 0 3600000;
BA_DEF_ SG_  "SPN" INT 0 524287;
BA_DEF_ SG_  "SigType" ENUM  "Default","Range","RangeSigned","ASCII","Discrete","Control","ReferencePGN","DTC","StringDelimiter","StringLength","StringLengthControl";
BA_DEF_DEF_  "CI_MsgDefinition" "";
BA_DEF_DEF_  "CI_MsgId" 0;
BA_DEF_DEF_  "CI_MsgName" "";
BA_DEF_DEF_  "GenMsgCycleTime" 0;
BA_DEF_DEF_  "GenMsgCycleTimeFast" 0;
BA_DEF_DEF_  "GenMsgDelayTime" 1;
BA_DEF_DEF_  "GenMsgILSupport" "Yes";
BA_DEF_DEF_  "GenMsgNrOfRepetition" 0;
BA_DEF_DEF_  "GenMsgRequestable" 0;
BA_DEF_DEF_  "GenMsgSendType" "noMsgSendType";
BA_DEF_DEF_  "GenMsgStartDelayTime" 0;
BA_DEF_DEF_  "TpJ1939VarDlc" "No";
BA_DEF_DEF_  "VFrameFormat" "J1939PG";
BA_DEF_DEF_  "CI_ParId" "";
BA_DEF_DEF_  "CI_SigId" 0;
BA_DEF_DEF_  "CI_SigName" "";
BA_DEF_DEF_  "GenSigEVName" "Env@Nodename_@Signame";
BA_DEF_DEF_  "GenSigILSupport" "Yes";
BA_DEF_DEF_  "GenSigInactiveValue" 0;
BA_DEF_DEF_  "GenSigSendType" "NoSigSendType";
BA_DEF_DEF_  "GenSigStartValue" 0;
BA_DEF_DEF_  "GenSigTimeoutTime_ACM_CANAIR" 0;
BA_DEF_DEF_  "GenSigTimeoutTime_ACU" 0;
BA_DEF_DEF_  "GenSigTimeoutTime_ADCU" 0;
BA_DEF_DEF_  "GenSigTimeoutTime_AI_CAID" 0;
BA_DEF_DEF_  "GenSigTimeoutTime_ASM_ELC5_Fr" 0;
BA_DEF_DEF_  "GenSigTimeoutTime_AVAS" 0;
BA_DEF_DEF_  "GenSigTimeoutTime_Av2HP" 0;
BA_DEF_DEF_  "GenSigTimeoutTime_BCM_NBM" 0;
BA_DEF_DEF_  "GenSigTimeoutTime_BSM_EBS" 0;
BA_DEF_DEF_  "GenSigTimeoutTime_DICO" 0;
BA_DEF_DEF_  "GenSigTimeoutTime_DMS" 0;
BA_DEF_DEF_  "GenSigTimeoutTime_EBS_EBR" 0;
BA_DEF_DEF_  "GenSigTimeoutTime_ECM_MD1_D" 0;
BA_DEF_DEF_  "GenSigTimeoutTime_ECM_MD1_G" 0;
BA_DEF_DEF_  "GenSigTimeoutTime_ETC_DiwaNXT" 0;
BA_DEF_DEF_  "GenSigTimeoutTime_ETC_DiwaNXT_MH" 0;
BA_DEF_DEF_  "GenSigTimeoutTime_ETC_Ecolife2" 0;
BA_DEF_DEF_  "GenSigTimeoutTime_FCCU" 0;
BA_DEF_DEF_  "GenSigTimeoutTime_FMS_FMS4" 0;
BA_DEF_DEF_  "GenSigTimeoutTime_FMS_FMS5" 0;
BA_DEF_DEF_  "GenSigTimeoutTime_HVPDU_HV_BOX" 0;
BA_DEF_DEF_  "GenSigTimeoutTime_IC_MulticII" 0;
BA_DEF_DEF_  "GenSigTimeoutTime_IC_MulticS" 0;
BA_DEF_DEF_  "GenSigTimeoutTime_INVEM1_ELFA3" 0;
BA_DEF_DEF_  "GenSigTimeoutTime_MBMS" 0;
BA_DEF_DEF_  "GenSigTimeoutTime_MCSL" 0;
BA_DEF_DEF_  "GenSigTimeoutTime_MPPxPTFE2" 0;
BA_DEF_DEF_  "GenSigTimeoutTime_PCM" 0;
BA_DEF_DEF_  "GenSigTimeoutTime_RDAB_SmtRadio" 0;
BA_DEF_DEF_  "GenSigTimeoutTime_RM_INTD" 0;
BA_DEF_DEF_  "GenSigTimeoutTime_RM_IRCS" 0;
BA_DEF_DEF_  "GenSigTimeoutTime_SAS" 0;
BA_DEF_DEF_  "GenSigTimeoutTime_SGW" 0;
BA_DEF_DEF_  "GenSigTimeoutTime_SGW2" 0;
BA_DEF_DEF_  "GenSigTimeoutTime_TASM_ETS" 0;
BA_DEF_DEF_  "GenSigTimeoutTime_TMU_HP_Fr" 0;
BA_DEF_DEF_  "GenSigTimeoutTime_TMU_HP_Rr" 0;
BA_DEF_DEF_  "GenSigTimeoutTime_TPMS" 0;
BA_DEF_DEF_  "GenSigTimeoutTime_Tacho_DTCO" 0;
BA_DEF_DEF_  "GenSigTimeoutTime_Tacho_MTCO" 0;
BA_DEF_DEF_  "GenSigTimeoutTime_Tacho_TSU" 0;
BA_DEF_DEF_  "GenSigTimeoutTime_VCM" 0;
BA_DEF_DEF_  "GenSigTimeoutTime_VCU" 0;
BA_DEF_DEF_  "GenSigTimeoutTime_VMU" 0;
BA_DEF_DEF_  "SPN" 0;
BA_DEF_DEF_  "SigType" "Default";
BA_ "GenMsgStartDelayTime" BO_ 2566870597 176;
BA_ "GenMsgSendType" BO_ 2566870597 0;
BA_ "GenMsgDelayTime" BO_ 2566870597 500;
BA_ "GenMsgCycleTimeFast" BO_ 2566870597 1000;
BA_ "GenMsgCycleTime" BO_ 2566870597 1000;
BA_ "CI_MsgName" BO_ 2566870597 "Telemat_3 - Telemat message 3";
BA_ "CI_MsgId" BO_ 2566870597 1860;
BA_ "CI_MsgDefinition" BO_ 2566870597 "Iveco Bus Proprietary";
BA_ "GenMsgStartDelayTime" BO_ 2566854469 154;
BA_ "GenMsgSendType" BO_ 2566854469 0;
BA_ "GenMsgDelayTime" BO_ 2566854469 500;
BA_ "GenMsgCycleTimeFast" BO_ 2566854469 1000;
BA_ "GenMsgCycleTime" BO_ 2566854469 1000;
BA_ "CI_MsgName" BO_ 2566854469 "Telemat_4 - Telemat message 4";
BA_ "CI_MsgId" BO_ 2566854469 1885;
BA_ "CI_MsgDefinition" BO_ 2566854469 "Iveco Bus Proprietary";
BA_ "GenMsgSendType" BO_ 2566906905 0;
BA_ "GenMsgDelayTime" BO_ 2566906905 500;
BA_ "GenMsgCycleTimeFast" BO_ 2566906905 1000;
BA_ "GenMsgCycleTime" BO_ 2566906905 1000;
BA_ "CI_MsgName" BO_ 2566906905 "ThermComf2BC - Thermal Comfort To Body Controller";
BA_ "CI_MsgId" BO_ 2566906905 10923;
BA_ "CI_MsgDefinition" BO_ 2566906905 "Iveco Proprietary";
BA_ "GenMsgStartDelayTime" BO_ 2566846467 34;
BA_ "GenMsgSendType" BO_ 2566846467 0;
BA_ "GenMsgDelayTime" BO_ 2566846467 500;
BA_ "GenMsgCycleTimeFast" BO_ 2566846467 1000;
BA_ "GenMsgCycleTime" BO_ 2566846467 1000;
BA_ "CI_MsgName" BO_ 2566846467 "TRF1 - Transmission Fluids 1";
BA_ "CI_MsgId" BO_ 2566846467 630;
BA_ "CI_MsgDefinition" BO_ 2566846467 "J1939DA";
BA_ "GenMsgStartDelayTime" BO_ 2566852119 101;
BA_ "GenMsgSendType" BO_ 2566852119 0;
BA_ "GenMsgDelayTime" BO_ 2566852119 500;
BA_ "GenMsgCycleTimeFast" BO_ 2566852119 1000;
BA_ "GenMsgCycleTime" BO_ 2566852119 1000;
BA_ "CI_MsgName" BO_ 2566852119 "TripEnergy - Trip Energy";
BA_ "CI_MsgId" BO_ 2566852119 1901;
BA_ "CI_MsgDefinition" BO_ 2566852119 "Iveco Proprietary";
BA_ "GenMsgStartDelayTime" BO_ 2566856261 107;
BA_ "GenMsgSendType" BO_ 2566856261 0;
BA_ "GenMsgDelayTime" BO_ 2566856261 500;
BA_ "GenMsgCycleTimeFast" BO_ 2566856261 1000;
BA_ "GenMsgCycleTime" BO_ 2566856261 1000;
BA_ "CI_MsgName" BO_ 2566856261 "TripEnergy2 - Trip Energy2 (Old Telematic_10)";
BA_ "CI_MsgId" BO_ 2566856261 1923;
BA_ "CI_MsgDefinition" BO_ 2566856261 "Iveco Bus Proprietary";
BA_ "GenMsgStartDelayTime" BO_ 2566749463 66;
BA_ "GenMsgSendType" BO_ 2566749463 0;
BA_ "GenMsgDelayTime" BO_ 2566749463 100;
BA_ "GenMsgCycleTimeFast" BO_ 2566749463 1000;
BA_ "GenMsgCycleTime" BO_ 2566749463 1000;
BA_ "CI_MsgName" BO_ 2566749463 "TTS - Telltale Status FMS1";
BA_ "CI_MsgId" BO_ 2566749463 3201;
BA_ "CI_MsgDefinition" BO_ 2566749463 "FMS";
BA_ "GenMsgStartDelayTime" BO_ 2566884426 162;
BA_ "GenMsgSendType" BO_ 2566884426 0;
BA_ "GenMsgDelayTime" BO_ 2566884426 500;
BA_ "GenMsgCycleTimeFast" BO_ 2566884426 1000;
BA_ "GenMsgCycleTime" BO_ 2566884426 1000;
BA_ "CI_MsgName" BO_ 2566884426 "V_TO_CAID2 - Proprietary B - Vehicle to CAID2 message ";
BA_ "CI_MsgId" BO_ 2566884426 1328;
BA_ "CI_MsgDefinition" BO_ 2566884426 "Iveco Proprietary";
BA_ "GenMsgStartDelayTime" BO_ 2566877568 22;
BA_ "GenMsgSendType" BO_ 2566877568 0;
BA_ "GenMsgDelayTime" BO_ 2566877568 50;
BA_ "GenMsgCycleTimeFast" BO_ 2566877568 100;
BA_ "GenMsgCycleTime" BO_ 2566877568 100;
BA_ "CI_MsgName" BO_ 2566877568 "VCU2MUX_FC - VCU2MUX_FuelCell";
BA_ "CI_MsgId" BO_ 2566877568 18903;
BA_ "CI_MsgDefinition" BO_ 2566877568 "Iveco Bus Proprietary";
BA_ "GenMsgStartDelayTime" BO_ 2566877824 48;
BA_ "GenMsgSendType" BO_ 2566877824 0;
BA_ "GenMsgDelayTime" BO_ 2566877824 500;
BA_ "GenMsgCycleTimeFast" BO_ 2566877824 1000;
BA_ "GenMsgCycleTime" BO_ 2566877824 1000;
BA_ "CI_MsgName" BO_ 2566877824 "VCU2MUX_HMU - VCU2MUX_HMU";
BA_ "CI_MsgId" BO_ 2566877824 18936;
BA_ "CI_MsgDefinition" BO_ 2566877824 "Iveco Bus Proprietary";
BA_ "GenMsgStartDelayTime" BO_ 2566878080 49;
BA_ "GenMsgSendType" BO_ 2566878080 0;
BA_ "GenMsgDelayTime" BO_ 2566878080 500;
BA_ "GenMsgCycleTimeFast" BO_ 2566878080 1000;
BA_ "GenMsgCycleTime" BO_ 2566878080 1000;
BA_ "CI_MsgName" BO_ 2566878080 "VCU2MUX_HMU#2 - VCU2MUX_HMU#2";
BA_ "CI_MsgId" BO_ 2566878080 18943;
BA_ "CI_MsgDefinition" BO_ 2566878080 "Iveco Bus Proprietary";
BA_ "GenMsgStartDelayTime" BO_ 2566878592 51;
BA_ "GenMsgSendType" BO_ 2566878592 0;
BA_ "GenMsgDelayTime" BO_ 2566878592 500;
BA_ "GenMsgCycleTimeFast" BO_ 2566878592 1000;
BA_ "GenMsgCycleTime" BO_ 2566878592 1000;
BA_ "CI_MsgName" BO_ 2566878592 "VCU2MUX_HMU#3 - VCU2MUX_HMU#3";
BA_ "CI_MsgId" BO_ 2566878592 18963;
BA_ "CI_MsgDefinition" BO_ 2566878592 "Iveco Bus Proprietary";
BA_ "GenMsgStartDelayTime" BO_ 2566803211 37;
BA_ "GenMsgSendType" BO_ 2566803211 0;
BA_ "GenMsgDelayTime" BO_ 2566803211 50;
BA_ "GenMsgCycleTimeFast" BO_ 2566803211 100;
BA_ "GenMsgCycleTime" BO_ 2566803211 100;
BA_ "CI_MsgName" BO_ 2566803211 "VDC1 - Vehicle Dynamic Stability Control 1";
BA_ "CI_MsgId" BO_ 2566803211 345;
BA_ "CI_MsgDefinition" BO_ 2566803211 "J1939DA";
BA_ "GenMsgStartDelayTime" BO_ 2565867787 10;
BA_ "GenMsgSendType" BO_ 2565867787 0;
BA_ "GenMsgDelayTime" BO_ 2565867787 10;
BA_ "GenMsgCycleTimeFast" BO_ 2565867787 20;
BA_ "GenMsgCycleTime" BO_ 2565867787 20;
BA_ "CI_MsgName" BO_ 2565867787 "VDC2 - Vehicle Dynamic Stability Control 2";
BA_ "CI_MsgId" BO_ 2565867787 354;
BA_ "CI_MsgDefinition" BO_ 2565867787 "J1939DA";
BA_ "GenMsgStartDelayTime" BO_ 2566832622 14;
BA_ "GenMsgSendType" BO_ 2566832622 0;
BA_ "GenMsgDelayTime" BO_ 2566832622 500;
BA_ "GenMsgCycleTimeFast" BO_ 2566832622 1000;
BA_ "GenMsgCycleTime" BO_ 2566832622 1000;
BA_ "CI_MsgName" BO_ 2566832622 "VDHR - High Resolution Vehicle Distance";
BA_ "CI_MsgId" BO_ 2566832622 673;
BA_ "CI_MsgDefinition" BO_ 2566832622 "J1939DA";
BA_ "GenMsgStartDelayTime" BO_ 2566842606 34;
BA_ "GenMsgSendType" BO_ 2566842606 0;
BA_ "GenMsgDelayTime" BO_ 2566842606 500;
BA_ "GenMsgCycleTimeFast" BO_ 2566842606 1000;
BA_ "GenMsgCycleTime" BO_ 2566842606 1000;
BA_ "CI_MsgName" BO_ 2566842606 "VDS_EE - Vehicle Direction/Speed";
BA_ "CI_MsgId" BO_ 2566842606 3455;
BA_ "CI_MsgDefinition" BO_ 2566842606 "J1939DA";
BA_ "GenMsgStartDelayTime" BO_ 2566846208 46;
BA_ "GenMsgSendType" BO_ 2566846208 0;
BA_ "GenMsgDelayTime" BO_ 2566846208 500;
BA_ "GenMsgCycleTimeFast" BO_ 2566846208 1000;
BA_ "GenMsgCycleTime" BO_ 2566846208 1000;
BA_ "CI_MsgName" BO_ 2566846208 "VEP1_00 - Vehicle Electrical Power 1";
BA_ "CI_MsgId" BO_ 2566846208 2205;
BA_ "CI_MsgDefinition" BO_ 2566846208 "J1939DA";
BA_ "GenMsgStartDelayTime" BO_ 2566846451 70;
BA_ "GenMsgSendType" BO_ 2566846451 0;
BA_ "GenMsgDelayTime" BO_ 2566846451 100;
BA_ "GenMsgCycleTimeFast" BO_ 2566846451 100;
BA_ "GenMsgCycleTime" BO_ 2566846451 100;
BA_ "CI_MsgName" BO_ 2566846451 "VEP1_F3 - Vehicle Electrical Power 1";
BA_ "CI_MsgId" BO_ 2566846451 2211;
BA_ "CI_MsgDefinition" BO_ 2566846451 "J1939DA";
BA_ "GenMsgStartDelayTime" BO_ 2566804211 52;
BA_ "GenMsgSendType" BO_ 2566804211 0;
BA_ "GenMsgDelayTime" BO_ 2566804211 100;
BA_ "GenMsgCycleTimeFast" BO_ 2566804211 100;
BA_ "GenMsgCycleTime" BO_ 2566804211 100;
BA_ "CI_MsgName" BO_ 2566804211 "VEP3_F3 - Vehicle Electrical Power 3";
BA_ "CI_MsgId" BO_ 2566804211 2217;
BA_ "CI_MsgDefinition" BO_ 2566804211 "J1939DA";
BA_ "GenMsgStartDelayTime" BO_ 2566698739 96;
BA_ "GenMsgSendType" BO_ 2566698739 0;
BA_ "GenMsgDelayTime" BO_ 2566698739 500;
BA_ "GenMsgCycleTimeFast" BO_ 2566698739 1000;
BA_ "GenMsgCycleTime" BO_ 2566698739 1000;
BA_ "CI_MsgName" BO_ 2566698739 "VEP5_F3 - Vehicle Electrical Power 5";
BA_ "CI_MsgId" BO_ 2566698739 2586;
BA_ "CI_MsgDefinition" BO_ 2566698739 "J1939DA";
BA_ "GenMsgStartDelayTime" BO_ 2566843630 46;
BA_ "GenMsgSendType" BO_ 2566843630 0;
BA_ "GenMsgDelayTime" BO_ 2566843630 5000;
BA_ "GenMsgCycleTimeFast" BO_ 2566843630 10000;
BA_ "GenMsgCycleTime" BO_ 2566843630 10000;
BA_ "CI_MsgName" BO_ 2566843630 "VI_EE - Vehicle Identification";
BA_ "CI_MsgId" BO_ 2566843630 743;
BA_ "CI_MsgDefinition" BO_ 2566843630 "J1939DA";
BA_ "GenMsgStartDelayTime" BO_ 2566845212 158;
BA_ "GenMsgSendType" BO_ 2566845212 0;
BA_ "GenMsgDelayTime" BO_ 2566845212 500;
BA_ "GenMsgCycleTimeFast" BO_ 2566845212 1000;
BA_ "GenMsgCycleTime" BO_ 2566845212 1000;
BA_ "CI_MsgName" BO_ 2566845212 "VP1_1C - Vehicle Position 1";
BA_ "CI_MsgId" BO_ 2566845212 3460;
BA_ "CI_MsgDefinition" BO_ 2566845212 "J1939DA";
BA_ "GenMsgStartDelayTime" BO_ 2566845422 38;
BA_ "GenMsgSendType" BO_ 2566845422 0;
BA_ "GenMsgDelayTime" BO_ 2566845422 500;
BA_ "GenMsgCycleTimeFast" BO_ 2566845422 1000;
BA_ "GenMsgCycleTime" BO_ 2566845422 1000;
BA_ "CI_MsgName" BO_ 2566845422 "VP1_EE - Vehicle Position 1";
BA_ "CI_MsgId" BO_ 2566845422 3463;
BA_ "CI_MsgDefinition" BO_ 2566845422 "J1939DA";
BA_ "GenMsgStartDelayTime" BO_ 2566842927 6;
BA_ "GenMsgSendType" BO_ 2566842927 0;
BA_ "GenMsgDelayTime" BO_ 2566842927 50;
BA_ "GenMsgCycleTimeFast" BO_ 2566842927 100;
BA_ "GenMsgCycleTime" BO_ 2566842927 100;
BA_ "CI_MsgName" BO_ 2566842927 "VW_2F - Vehicle Weight";
BA_ "CI_MsgId" BO_ 2566842927 17507;
BA_ "CI_MsgDefinition" BO_ 2566842927 "J1939DA";
BA_ "GenMsgStartDelayTime" BO_ 2566842944 6;
BA_ "GenMsgSendType" BO_ 2566842944 0;
BA_ "GenMsgDelayTime" BO_ 2566842944 50;
BA_ "GenMsgCycleTimeFast" BO_ 2566842944 100;
BA_ "GenMsgCycleTime" BO_ 2566842944 100;
BA_ "CI_MsgName" BO_ 2566842944 "VW_40 - Vehicle Weight";
BA_ "CI_MsgId" BO_ 2566842944 17514;
BA_ "CI_MsgDefinition" BO_ 2566842944 "J1939DA";
BA_ "GenMsgStartDelayTime" BO_ 2566848256 67;
BA_ "GenMsgSendType" BO_ 2566848256 0;
BA_ "GenMsgDelayTime" BO_ 2566848256 100;
BA_ "GenMsgCycleTimeFast" BO_ 2566848256 1000;
BA_ "GenMsgCycleTime" BO_ 2566848256 1000;
BA_ "CI_MsgName" BO_ 2566848256 "WFI - Water in Fuel Indicator";
BA_ "CI_MsgId" BO_ 2566848256 1616;
BA_ "CI_MsgDefinition" BO_ 2566848256 "J1939DA";
BA_ "GenMsgSendType" BO_ 2349075360 0;
BA_ "GenMsgNrOfRepetition" BO_ 2349075360 4;
BA_ "GenMsgDelayTime" BO_ 2349075360 10;
BA_ "GenMsgCycleTimeFast" BO_ 2349075360 20;
BA_ "GenMsgCycleTime" BO_ 2349075360 200;
BA_ "CI_MsgName" BO_ 2349075360 "XBR_A0_0B - External Brake Request";
BA_ "CI_MsgId" BO_ 2349075360 336;
BA_ "CI_MsgDefinition" BO_ 2349075360 "J1939 p2p";
BA_ "GenMsgSendType" BO_ 2566845436 0;
BA_ "GenMsgDelayTime" BO_ 2566845436 2500;
BA_ "GenMsgCycleTimeFast" BO_ 2566845436 5000;
BA_ "GenMsgCycleTime" BO_ 2566845436 5000;
BA_ "CI_MsgId" BO_ 2566845436 50001;
BA_ "CI_MsgName" BO_ 2565472330 "RQST_4A_00 - Request";
BA_ "CI_MsgId" BO_ 2565472330 100000;
BA_ "CI_MsgDefinition" BO_ 2565472330 "J1939-21";
BA_ "CI_MsgName" BO_ 2565482314 "RQST_4A_27 - Request";
BA_ "CI_MsgId" BO_ 2565482314 100002;
BA_ "CI_MsgDefinition" BO_ 2565482314 "J1939-21";
BA_ "CI_MsgName" BO_ 2565478218 "RQST_4A_17 - Request";
BA_ "CI_MsgId" BO_ 2565478218 100004;
BA_ "CI_MsgDefinition" BO_ 2565478218 "J1939-21";
BA_ "CI_MsgName" BO_ 2565473098 "RQST_4A_03 - Request";
BA_ "CI_MsgId" BO_ 2565473098 100006;
BA_ "CI_MsgDefinition" BO_ 2565473098 "J1939-21";
BA_ "CI_MsgName" BO_ 2565475146 "RQST_4A_0B - Request";
BA_ "CI_MsgId" BO_ 2565475146 100008;
BA_ "CI_MsgDefinition" BO_ 2565475146 "J1939-21";
BA_ "CI_MsgName" BO_ 2565479754 "RQST_4A_1D - Request";
BA_ "CI_MsgId" BO_ 2565479754 100010;
BA_ "CI_MsgDefinition" BO_ 2565479754 "J1939-21";
BA_ "CI_MsgName" BO_ 2565486666 "RQST_4A_38 - Request";
BA_ "CI_MsgId" BO_ 2565486666 100012;
BA_ "CI_MsgDefinition" BO_ 2565486666 "J1939-21";
BA_ "CI_MsgName" BO_ 2565504586 "RQST_4A_7E - Request";
BA_ "CI_MsgId" BO_ 2565504586 100014;
BA_ "CI_MsgDefinition" BO_ 2565504586 "J1939-21";
BA_ "CI_MsgName" BO_ 2565512778 "RQST_4A_9E - Request";
BA_ "CI_MsgId" BO_ 2565512778 100016;
BA_ "CI_MsgDefinition" BO_ 2565512778 "J1939-21";
BA_ "CI_MsgName" BO_ 2565513290 "RQST_4A_A0 - Request";
BA_ "CI_MsgId" BO_ 2565513290 100018;
BA_ "CI_MsgDefinition" BO_ 2565513290 "J1939-21";
BA_ "CI_MsgName" BO_ 2565480778 "RQST_4A_21 - Request";
BA_ "CI_MsgId" BO_ 2565480778 100020;
BA_ "CI_MsgDefinition" BO_ 2565480778 "J1939-21";
BA_ "CI_MsgName" BO_ 2565496394 "RQST_4A_5E - Request";
BA_ "CI_MsgId" BO_ 2565496394 100022;
BA_ "CI_MsgDefinition" BO_ 2565496394 "J1939-21";
BA_ "CI_MsgName" BO_ 2565495370 "RQST_4A_5A - Request";
BA_ "CI_MsgId" BO_ 2565495370 100024;
BA_ "CI_MsgDefinition" BO_ 2565495370 "J1939-21";
BA_ "CI_MsgName" BO_ 2565484362 "RQST_4A_2F - Request";
BA_ "CI_MsgId" BO_ 2565484362 100026;
BA_ "CI_MsgDefinition" BO_ 2565484362 "J1939-21";
BA_ "CI_MsgName" BO_ 2565488714 "RQST_4A_40 - Request";
BA_ "CI_MsgId" BO_ 2565488714 100028;
BA_ "CI_MsgDefinition" BO_ 2565488714 "J1939-21";
BA_ "CI_MsgName" BO_ 2565535562 "RQST_4A_F7 - Request";
BA_ "CI_MsgId" BO_ 2565535562 100030;
BA_ "CI_MsgDefinition" BO_ 2565535562 "J1939-21";
BA_ "CI_MsgName" BO_ 2565535306 "RQST_4A_F6 - Request";
BA_ "CI_MsgId" BO_ 2565535306 100032;
BA_ "CI_MsgDefinition" BO_ 2565535306 "J1939-21";
BA_ "CI_MsgName" BO_ 2565534538 "RQST_4A_F3 - Request";
BA_ "CI_MsgId" BO_ 2565534538 100034;
BA_ "CI_MsgDefinition" BO_ 2565534538 "J1939-21";
BA_ "CI_MsgName" BO_ 2565491018 "RQST_4A_49 - Request";
BA_ "CI_MsgId" BO_ 2565491018 100036;
BA_ "CI_MsgDefinition" BO_ 2565491018 "J1939-21";
BA_ "CI_MsgName" BO_ 2565476426 "RQST_4A_10 - Request";
BA_ "CI_MsgId" BO_ 2565476426 100038;
BA_ "CI_MsgDefinition" BO_ 2565476426 "J1939-21";
BA_ "CI_MsgName" BO_ 2565484106 "RQST_4A_2E - Request";
BA_ "CI_MsgId" BO_ 2565484106 100040;
BA_ "CI_MsgDefinition" BO_ 2565484106 "J1939-21";
BA_ "CI_MsgName" BO_ 2565509194 "RQST_4A_90 - Request";
BA_ "CI_MsgId" BO_ 2565509194 100042;
BA_ "CI_MsgDefinition" BO_ 2565509194 "J1939-21";
BA_ "CI_MsgName" BO_ 2565509450 "RQST_4A_91 - Request";
BA_ "CI_MsgId" BO_ 2565509450 100044;
BA_ "CI_MsgDefinition" BO_ 2565509450 "J1939-21";
BA_ "CI_MsgName" BO_ 2565509706 "RQST_4A_92 - Request";
BA_ "CI_MsgId" BO_ 2565509706 100046;
BA_ "CI_MsgDefinition" BO_ 2565509706 "J1939-21";
BA_ "CI_MsgName" BO_ 2565512266 "RQST_4A_9C - Request";
BA_ "CI_MsgId" BO_ 2565512266 100048;
BA_ "CI_MsgDefinition" BO_ 2565512266 "J1939-21";
BA_ "CI_MsgName" BO_ 2565531722 "RQST_4A_E8 - Request";
BA_ "CI_MsgId" BO_ 2565531722 100050;
BA_ "CI_MsgDefinition" BO_ 2565531722 "J1939-21";
BA_ "CI_MsgName" BO_ 2565533770 "RQST_4A_F0 - Request";
BA_ "CI_MsgId" BO_ 2565533770 100052;
BA_ "CI_MsgDefinition" BO_ 2565533770 "J1939-21";
BA_ "CI_MsgName" BO_ 2565478730 "RQST_4A_19 - Request";
BA_ "CI_MsgId" BO_ 2565478730 100054;
BA_ "CI_MsgDefinition" BO_ 2565478730 "J1939-21";
BA_ "CI_MsgName" BO_ 2565487178 "RQST_4A_3A - Request";
BA_ "CI_MsgId" BO_ 2565487178 100056;
BA_ "CI_MsgDefinition" BO_ 2565487178 "J1939-21";
BA_ "CI_MsgName" BO_ 2565505098 "RQST_4A_80 - Request";
BA_ "CI_MsgId" BO_ 2565505098 100058;
BA_ "CI_MsgDefinition" BO_ 2565505098 "J1939-21";
BA_ "CI_MsgName" BO_ 2565489994 "RQST_4A_45 - Request";
BA_ "CI_MsgId" BO_ 2565489994 100060;
BA_ "CI_MsgDefinition" BO_ 2565489994 "J1939-21";
BA_ "CI_MsgName" BO_ 2565501514 "RQST_4A_72 - Request";
BA_ "CI_MsgId" BO_ 2565501514 100062;
BA_ "CI_MsgDefinition" BO_ 2565501514 "J1939-21";
BA_ "CI_MsgName" BO_ 2565476170 "RQST_4A_0F - Request";
BA_ "CI_MsgId" BO_ 2565476170 100064;
BA_ "CI_MsgDefinition" BO_ 2565476170 "J1939-21";
BA_ "CI_MsgName" BO_ 2565533514 "RQST_4A_EF - Request";
BA_ "CI_MsgId" BO_ 2565533514 100066;
BA_ "CI_MsgDefinition" BO_ 2565533514 "J1939-21";
BA_ "CI_MsgName" BO_ 2565531466 "RQST_4A_E7 - Request";
BA_ "CI_MsgId" BO_ 2565531466 100068;
BA_ "CI_MsgDefinition" BO_ 2565531466 "J1939-21";
BA_ "CI_MsgName" BO_ 2565501258 "RQST_4A_71 - Request";
BA_ "CI_MsgId" BO_ 2565501258 100070;
BA_ "CI_MsgDefinition" BO_ 2565501258 "J1939-21";
BA_ "CI_MsgName" BO_ 2565537610 "RQST_4A_FF - Request";
BA_ "CI_MsgId" BO_ 2565537610 100072;
BA_ "CI_MsgDefinition" BO_ 2565537610 "J1939-21";
BA_ "CI_MsgName" BO_ 2566913797 "PH_05_FF";
BA_ "CI_MsgId" BO_ 2566913797 100074;
BA_ "CI_MsgDefinition" BO_ 2566913797 "J1939-21";
BA_ "CI_MsgName" BO_ 2566913841 "PH_31_FF";
BA_ "CI_MsgId" BO_ 2566913841 100076;
BA_ "CI_MsgDefinition" BO_ 2566913841 "J1939-21";
BA_ "CI_MsgName" BO_ 2566913909 "PH_75_FF";
BA_ "CI_MsgId" BO_ 2566913909 100078;
BA_ "CI_MsgDefinition" BO_ 2566913909 "J1939-21";
BA_ "CI_MsgName" BO_ 2566913818 "PH_1A_FF";
BA_ "CI_MsgId" BO_ 2566913818 100080;
BA_ "CI_MsgDefinition" BO_ 2566913818 "J1939-21";
BA_ "CI_MsgName" BO_ 2566913829 "PH_25_FF";
BA_ "CI_MsgId" BO_ 2566913829 100082;
BA_ "CI_MsgDefinition" BO_ 2566913829 "J1939-21";
BA_ "CI_MsgName" BO_ 2566913888 "PH_60_FF";
BA_ "CI_MsgId" BO_ 2566913888 100084;
BA_ "CI_MsgDefinition" BO_ 2566913888 "J1939-21";
BA_ "CI_MsgName" BO_ 2566913890 "PH_62_FF";
BA_ "CI_MsgId" BO_ 2566913890 100086;
BA_ "CI_MsgDefinition" BO_ 2566913890 "J1939-21";
BA_ "CI_MsgName" BO_ 2566913926 "PH_86_FF";
BA_ "CI_MsgId" BO_ 2566913926 100088;
BA_ "CI_MsgDefinition" BO_ 2566913926 "J1939-21";
BA_ "CI_MsgName" BO_ 2566913927 "PH_87_FF";
BA_ "CI_MsgId" BO_ 2566913927 100090;
BA_ "CI_MsgDefinition" BO_ 2566913927 "J1939-21";
BA_ "CI_MsgName" BO_ 2566913928 "PH_88_FF";
BA_ "CI_MsgId" BO_ 2566913928 100092;
BA_ "CI_MsgDefinition" BO_ 2566913928 "J1939-21";
BA_ "CI_MsgName" BO_ 2566913929 "PH_89_FF";
BA_ "CI_MsgId" BO_ 2566913929 100094;
BA_ "CI_MsgDefinition" BO_ 2566913929 "J1939-21";
BA_ "CI_MsgName" BO_ 2566913930 "PH_8A_FF";
BA_ "CI_MsgId" BO_ 2566913930 100096;
BA_ "CI_MsgDefinition" BO_ 2566913930 "J1939-21";
BA_ "CI_MsgName" BO_ 2566913931 "PH_8B_FF";
BA_ "CI_MsgId" BO_ 2566913931 100098;
BA_ "CI_MsgDefinition" BO_ 2566913931 "J1939-21";
BA_ "CI_MsgName" BO_ 2566913932 "PH_8C_FF";
BA_ "CI_MsgId" BO_ 2566913932 100100;
BA_ "CI_MsgDefinition" BO_ 2566913932 "J1939-21";
BA_ "CI_MsgName" BO_ 2566913933 "PH_8D_FF";
BA_ "CI_MsgId" BO_ 2566913933 100102;
BA_ "CI_MsgDefinition" BO_ 2566913933 "J1939-21";
BA_ "GenSigTimeoutTime_SGW" SG_ 2566870597 DCDC_12V_ConvFault 5000;
BA_ "GenSigTimeoutTime_PCM" SG_ 2566870597 DCDC_12V_ConvFault 5000;
BA_ "CI_SigName" SG_ 2566870597 DCDC_12V_ConvFault "DCDC 12V Converter Fault";
BA_ "CI_SigId" SG_ 2566870597 DCDC_12V_ConvFault 23389;
BA_ "CI_ParId" SG_ 2566870597 DCDC_12V_ConvFault "IB832";
BA_ "GenSigTimeoutTime_SGW" SG_ 2566870597 OverheatingComprElec 5000;
BA_ "GenSigTimeoutTime_PCM" SG_ 2566870597 OverheatingComprElec 5000;
BA_ "CI_SigName" SG_ 2566870597 OverheatingComprElec "Overheating Compressor Elec";
BA_ "CI_SigId" SG_ 2566870597 OverheatingComprElec 1884;
BA_ "CI_ParId" SG_ 2566870597 OverheatingComprElec "IB776";
BA_ "GenSigTimeoutTime_SGW" SG_ 2566870597 AirDryerSts 5000;
BA_ "GenSigTimeoutTime_PCM" SG_ 2566870597 AirDryerSts 5000;
BA_ "CI_SigName" SG_ 2566870597 AirDryerSts "Air Dryer Status";
BA_ "CI_SigId" SG_ 2566870597 AirDryerSts 1883;
BA_ "CI_ParId" SG_ 2566870597 AirDryerSts "IB775";
BA_ "GenSigTimeoutTime_SGW" SG_ 2566870597 LastDoor4CmdCode 5000;
BA_ "GenSigTimeoutTime_PCM" SG_ 2566870597 LastDoor4CmdCode 5000;
BA_ "CI_SigName" SG_ 2566870597 LastDoor4CmdCode "Last door 4 command code";
BA_ "CI_SigId" SG_ 2566870597 LastDoor4CmdCode 1882;
BA_ "CI_ParId" SG_ 2566870597 LastDoor4CmdCode "IB774";
BA_ "GenSigTimeoutTime_SGW" SG_ 2566870597 LastDoor3CmdCode 5000;
BA_ "GenSigTimeoutTime_PCM" SG_ 2566870597 LastDoor3CmdCode 5000;
BA_ "CI_SigName" SG_ 2566870597 LastDoor3CmdCode "Last door 3 command code";
BA_ "CI_SigId" SG_ 2566870597 LastDoor3CmdCode 1881;
BA_ "CI_ParId" SG_ 2566870597 LastDoor3CmdCode "IB773";
BA_ "GenSigTimeoutTime_SGW" SG_ 2566870597 LastDoor2CmdCode 5000;
BA_ "GenSigTimeoutTime_PCM" SG_ 2566870597 LastDoor2CmdCode 5000;
BA_ "CI_SigName" SG_ 2566870597 LastDoor2CmdCode "Last door 2 command code";
BA_ "CI_SigId" SG_ 2566870597 LastDoor2CmdCode 1880;
BA_ "CI_ParId" SG_ 2566870597 LastDoor2CmdCode "IB772";
BA_ "GenSigTimeoutTime_SGW" SG_ 2566870597 LastDoor1CmdCode 5000;
BA_ "GenSigTimeoutTime_PCM" SG_ 2566870597 LastDoor1CmdCode 5000;
BA_ "CI_SigName" SG_ 2566870597 LastDoor1CmdCode "Last door 1 command code";
BA_ "CI_SigId" SG_ 2566870597 LastDoor1CmdCode 1879;
BA_ "CI_ParId" SG_ 2566870597 LastDoor1CmdCode "IB771";
BA_ "GenSigTimeoutTime_SGW" SG_ 2566870597 Door4ActvInEmerMode 5000;
BA_ "GenSigTimeoutTime_PCM" SG_ 2566870597 Door4ActvInEmerMode 5000;
BA_ "CI_SigName" SG_ 2566870597 Door4ActvInEmerMode "Door 4 activated in emergency mode";
BA_ "CI_SigId" SG_ 2566870597 Door4ActvInEmerMode 1878;
BA_ "CI_ParId" SG_ 2566870597 Door4ActvInEmerMode "IB770";
BA_ "GenSigTimeoutTime_SGW" SG_ 2566870597 Door3ActvInEmerMode 5000;
BA_ "GenSigTimeoutTime_PCM" SG_ 2566870597 Door3ActvInEmerMode 5000;
BA_ "CI_SigName" SG_ 2566870597 Door3ActvInEmerMode "Door 3 activated in emergency mode";
BA_ "CI_SigId" SG_ 2566870597 Door3ActvInEmerMode 1877;
BA_ "CI_ParId" SG_ 2566870597 Door3ActvInEmerMode "IB769";
BA_ "GenSigTimeoutTime_SGW" SG_ 2566870597 Door2ActvInEmerMode 5000;
BA_ "GenSigTimeoutTime_PCM" SG_ 2566870597 Door2ActvInEmerMode 5000;
BA_ "CI_SigName" SG_ 2566870597 Door2ActvInEmerMode "Door 2 activated in emergency mode";
BA_ "CI_SigId" SG_ 2566870597 Door2ActvInEmerMode 1876;
BA_ "CI_ParId" SG_ 2566870597 Door2ActvInEmerMode "IB768";
BA_ "GenSigTimeoutTime_SGW" SG_ 2566870597 Door1ActvInEmerMode 5000;
BA_ "GenSigTimeoutTime_PCM" SG_ 2566870597 Door1ActvInEmerMode 5000;
BA_ "CI_SigName" SG_ 2566870597 Door1ActvInEmerMode "Door 1 activated in emergency mode";
BA_ "CI_SigId" SG_ 2566870597 Door1ActvInEmerMode 1875;
BA_ "CI_ParId" SG_ 2566870597 Door1ActvInEmerMode "IB767";
BA_ "GenSigTimeoutTime_SGW" SG_ 2566870597 Door4EmerInh 5000;
BA_ "GenSigTimeoutTime_PCM" SG_ 2566870597 Door4EmerInh 5000;
BA_ "CI_SigName" SG_ 2566870597 Door4EmerInh "Door 4 - Emergency inhibition";
BA_ "CI_SigId" SG_ 2566870597 Door4EmerInh 1874;
BA_ "CI_ParId" SG_ 2566870597 Door4EmerInh "IB766";
BA_ "GenSigTimeoutTime_SGW" SG_ 2566870597 Door3EmerInh 5000;
BA_ "GenSigTimeoutTime_PCM" SG_ 2566870597 Door3EmerInh 5000;
BA_ "CI_SigName" SG_ 2566870597 Door3EmerInh "Door 3 - Emergency inhibition";
BA_ "CI_SigId" SG_ 2566870597 Door3EmerInh 1873;
BA_ "CI_ParId" SG_ 2566870597 Door3EmerInh "IB765";
BA_ "GenSigTimeoutTime_SGW" SG_ 2566870597 Door2EmerInh 5000;
BA_ "GenSigTimeoutTime_PCM" SG_ 2566870597 Door2EmerInh 5000;
BA_ "CI_SigName" SG_ 2566870597 Door2EmerInh "Door 2 - Emergency inhibition";
BA_ "CI_SigId" SG_ 2566870597 Door2EmerInh 1872;
BA_ "CI_ParId" SG_ 2566870597 Door2EmerInh "IB764";
BA_ "GenSigTimeoutTime_SGW" SG_ 2566870597 Door1EmerInh 5000;
BA_ "GenSigTimeoutTime_PCM" SG_ 2566870597 Door1EmerInh 5000;
BA_ "CI_SigName" SG_ 2566870597 Door1EmerInh "Door 1 - Emergency inhibition";
BA_ "CI_SigId" SG_ 2566870597 Door1EmerInh 1871;
BA_ "CI_ParId" SG_ 2566870597 Door1EmerInh "IB763";
BA_ "GenSigTimeoutTime_SGW" SG_ 2566870597 EmerBtnSts 5000;
BA_ "GenSigTimeoutTime_PCM" SG_ 2566870597 EmerBtnSts 5000;
BA_ "CI_SigName" SG_ 2566870597 EmerBtnSts "Emergency button state ";
BA_ "CI_SigId" SG_ 2566870597 EmerBtnSts 1870;
BA_ "CI_ParId" SG_ 2566870597 EmerBtnSts "IB762";
BA_ "SigType" SG_ 2566870597 FipoSts 4;
BA_ "GenSigTimeoutTime_SGW" SG_ 2566870597 FipoSts 5000;
BA_ "GenSigTimeoutTime_PCM" SG_ 2566870597 FipoSts 5000;
BA_ "CI_SigName" SG_ 2566870597 FipoSts "FIPO status";
BA_ "CI_SigId" SG_ 2566870597 FipoSts 1869;
BA_ "CI_ParId" SG_ 2566870597 FipoSts "IB761";
BA_ "SigType" SG_ 2566870597 FaeSts 4;
BA_ "GenSigTimeoutTime_SGW" SG_ 2566870597 FaeSts 5000;
BA_ "GenSigTimeoutTime_PCM" SG_ 2566870597 FaeSts 5000;
BA_ "CI_SigName" SG_ 2566870597 FaeSts "FAE status";
BA_ "CI_SigId" SG_ 2566870597 FaeSts 1868;
BA_ "CI_ParId" SG_ 2566870597 FaeSts "IB760";
BA_ "GenSigTimeoutTime_SGW" SG_ 2566870597 ParkBrkSwFullyApplied 5000;
BA_ "GenSigTimeoutTime_PCM" SG_ 2566870597 ParkBrkSwFullyApplied 5000;
BA_ "CI_SigName" SG_ 2566870597 ParkBrkSwFullyApplied "Parking Brake Switch fully applied";
BA_ "CI_SigId" SG_ 2566870597 ParkBrkSwFullyApplied 1867;
BA_ "CI_ParId" SG_ 2566870597 ParkBrkSwFullyApplied "IB759";
BA_ "GenSigTimeoutTime_SGW" SG_ 2566870597 HeatSysHighTempFault 5000;
BA_ "GenSigTimeoutTime_PCM" SG_ 2566870597 HeatSysHighTempFault 5000;
BA_ "CI_SigName" SG_ 2566870597 HeatSysHighTempFault "Heating system high temperature fault";
BA_ "CI_SigId" SG_ 2566870597 HeatSysHighTempFault 1866;
BA_ "CI_ParId" SG_ 2566870597 HeatSysHighTempFault "IB758";
BA_ "GenSigTimeoutTime_SGW" SG_ 2566870597 HeatFuelLowLev 5000;
BA_ "GenSigTimeoutTime_PCM" SG_ 2566870597 HeatFuelLowLev 5000;
BA_ "CI_SigName" SG_ 2566870597 HeatFuelLowLev "Heating Fuel Low Level";
BA_ "CI_SigId" SG_ 2566870597 HeatFuelLowLev 1865;
BA_ "CI_ParId" SG_ 2566870597 HeatFuelLowLev "IB757";
BA_ "GenSigTimeoutTime_SGW" SG_ 2566870597 HeatLiquidLowLev 5000;
BA_ "GenSigTimeoutTime_PCM" SG_ 2566870597 HeatLiquidLowLev 5000;
BA_ "CI_SigName" SG_ 2566870597 HeatLiquidLowLev "Heating Liquid Low Level";
BA_ "CI_SigId" SG_ 2566870597 HeatLiquidLowLev 1864;
BA_ "CI_ParId" SG_ 2566870597 HeatLiquidLowLev "IB756";
BA_ "GenSigTimeoutTime_SGW" SG_ 2566870597 VehMode 5000;
BA_ "GenSigTimeoutTime_PCM" SG_ 2566870597 VehMode 5000;
BA_ "CI_SigName" SG_ 2566870597 VehMode "Vehicle Mode";
BA_ "CI_SigId" SG_ 2566870597 VehMode 1861;
BA_ "CI_ParId" SG_ 2566870597 VehMode "IB753";
BA_ "SigType" SG_ 2566854469 OilMaintenanceReset 4;
BA_ "GenSigTimeoutTime_SGW" SG_ 2566854469 OilMaintenanceReset 5000;
BA_ "GenSigTimeoutTime_PCM" SG_ 2566854469 OilMaintenanceReset 5000;
BA_ "CI_SigName" SG_ 2566854469 OilMaintenanceReset "Oil maintenance reset";
BA_ "CI_SigId" SG_ 2566854469 OilMaintenanceReset 17500;
BA_ "CI_ParId" SG_ 2566854469 OilMaintenanceReset "IB2159";
BA_ "SigType" SG_ 2566854469 OilMaintenanceAlert 4;
BA_ "GenSigTimeoutTime_SGW" SG_ 2566854469 OilMaintenanceAlert 5000;
BA_ "GenSigTimeoutTime_PCM" SG_ 2566854469 OilMaintenanceAlert 5000;
BA_ "CI_SigName" SG_ 2566854469 OilMaintenanceAlert "Oil maintenance alert";
BA_ "CI_SigId" SG_ 2566854469 OilMaintenanceAlert 17499;
BA_ "CI_ParId" SG_ 2566854469 OilMaintenanceAlert "IB2158";
BA_ "SigType" SG_ 2566854469 TotEngCntsInfo 1;
BA_ "GenSigTimeoutTime_SGW" SG_ 2566854469 TotEngCntsInfo 5000;
BA_ "GenSigTimeoutTime_PCM" SG_ 2566854469 TotEngCntsInfo 5000;
BA_ "CI_SigName" SG_ 2566854469 TotEngCntsInfo "Total engine counters information";
BA_ "CI_SigId" SG_ 2566854469 TotEngCntsInfo 1895;
BA_ "CI_ParId" SG_ 2566854469 TotEngCntsInfo "IB786";
BA_ "SigType" SG_ 2566854469 ExtTempIvecoBus 1;
BA_ "GenSigTimeoutTime_SGW" SG_ 2566854469 ExtTempIvecoBus 5000;
BA_ "GenSigTimeoutTime_PCM" SG_ 2566854469 ExtTempIvecoBus 5000;
BA_ "GenSigStartValue" SG_ 2566854469 ExtTempIvecoBus 40;
BA_ "CI_SigName" SG_ 2566854469 ExtTempIvecoBus "External temperature - IVECO BUS";
BA_ "CI_SigId" SG_ 2566854469 ExtTempIvecoBus 1894;
BA_ "CI_ParId" SG_ 2566854469 ExtTempIvecoBus "IB785";
BA_ "GenSigTimeoutTime_SGW" SG_ 2566854469 PropellerShaftOverspeedAlert 5000;
BA_ "GenSigTimeoutTime_PCM" SG_ 2566854469 PropellerShaftOverspeedAlert 5000;
BA_ "CI_SigName" SG_ 2566854469 PropellerShaftOverspeedAlert "Propeller shaft overspeed alert";
BA_ "CI_SigId" SG_ 2566854469 PropellerShaftOverspeedAlert 1893;
BA_ "CI_ParId" SG_ 2566854469 PropellerShaftOverspeedAlert "IB784";
BA_ "GenSigTimeoutTime_SGW" SG_ 2566854469 _3RdAxleOvl 5000;
BA_ "GenSigTimeoutTime_PCM" SG_ 2566854469 _3RdAxleOvl 5000;
BA_ "CI_SigName" SG_ 2566854469 _3RdAxleOvl "3rd axle overload";
BA_ "CI_SigId" SG_ 2566854469 _3RdAxleOvl 1891;
BA_ "CI_ParId" SG_ 2566854469 _3RdAxleOvl "IB782";
BA_ "GenSigTimeoutTime_SGW" SG_ 2566854469 _3RdAxleOilLevLow 5000;
BA_ "GenSigTimeoutTime_PCM" SG_ 2566854469 _3RdAxleOilLevLow 5000;
BA_ "CI_SigName" SG_ 2566854469 _3RdAxleOilLevLow "3rd axle oil level low";
BA_ "CI_SigId" SG_ 2566854469 _3RdAxleOilLevLow 1890;
BA_ "CI_ParId" SG_ 2566854469 _3RdAxleOilLevLow "IB781";
BA_ "GenSigTimeoutTime_SGW" SG_ 2566854469 _3RdAxlePrsLow 5000;
BA_ "GenSigTimeoutTime_PCM" SG_ 2566854469 _3RdAxlePrsLow 5000;
BA_ "CI_SigName" SG_ 2566854469 _3RdAxlePrsLow "3rd axle pressure Low";
BA_ "CI_SigId" SG_ 2566854469 _3RdAxlePrsLow 1889;
BA_ "CI_ParId" SG_ 2566854469 _3RdAxlePrsLow "IB780";
BA_ "GenSigTimeoutTime_SGW" SG_ 2566854469 NoBat3Recharge 5000;
BA_ "GenSigTimeoutTime_PCM" SG_ 2566854469 NoBat3Recharge 5000;
BA_ "CI_SigName" SG_ 2566854469 NoBat3Recharge "No battery 3  recharge";
BA_ "CI_SigId" SG_ 2566854469 NoBat3Recharge 1888;
BA_ "CI_ParId" SG_ 2566854469 NoBat3Recharge "IB779";
BA_ "GenSigTimeoutTime_SGW" SG_ 2566854469 NoBat2Recharge 5000;
BA_ "GenSigTimeoutTime_PCM" SG_ 2566854469 NoBat2Recharge 5000;
BA_ "CI_SigName" SG_ 2566854469 NoBat2Recharge "No battery 2 recharge";
BA_ "CI_SigId" SG_ 2566854469 NoBat2Recharge 1887;
BA_ "CI_ParId" SG_ 2566854469 NoBat2Recharge "IB778";
BA_ "GenSigTimeoutTime_SGW" SG_ 2566854469 NoBat1Recharge 5000;
BA_ "GenSigTimeoutTime_PCM" SG_ 2566854469 NoBat1Recharge 5000;
BA_ "CI_SigName" SG_ 2566854469 NoBat1Recharge "No battery 1 recharge";
BA_ "CI_SigId" SG_ 2566854469 NoBat1Recharge 1886;
BA_ "CI_ParId" SG_ 2566854469 NoBat1Recharge "IB777";
BA_ "SigType" SG_ 2566906905 ElHtrOverheatingWarn 4;
BA_ "GenSigTimeoutTime_SGW" SG_ 2566906905 ElHtrOverheatingWarn 5000;
BA_ "GenSigTimeoutTime_PCM" SG_ 2566906905 ElHtrOverheatingWarn 5000;
BA_ "GenSigTimeoutTime_BCM_NBM" SG_ 2566906905 ElHtrOverheatingWarn 5000;
BA_ "CI_SigName" SG_ 2566906905 ElHtrOverheatingWarn "Electric Heater Overheating warning";
BA_ "CI_SigId" SG_ 2566906905 ElHtrOverheatingWarn 10934;
BA_ "CI_ParId" SG_ 2566906905 ElHtrOverheatingWarn "IB1379";
BA_ "SigType" SG_ 2566906905 ElHtrHvRelayDamaged 4;
BA_ "GenSigTimeoutTime_SGW" SG_ 2566906905 ElHtrHvRelayDamaged 5000;
BA_ "GenSigTimeoutTime_PCM" SG_ 2566906905 ElHtrHvRelayDamaged 5000;
BA_ "GenSigTimeoutTime_BCM_NBM" SG_ 2566906905 ElHtrHvRelayDamaged 5000;
BA_ "CI_SigName" SG_ 2566906905 ElHtrHvRelayDamaged "Electric Heater HV relay damaged";
BA_ "CI_SigId" SG_ 2566906905 ElHtrHvRelayDamaged 10933;
BA_ "CI_ParId" SG_ 2566906905 ElHtrHvRelayDamaged "IB1378";
BA_ "SigType" SG_ 2566906905 ElHtrOverheating 4;
BA_ "GenSigTimeoutTime_SGW" SG_ 2566906905 ElHtrOverheating 5000;
BA_ "GenSigTimeoutTime_PCM" SG_ 2566906905 ElHtrOverheating 5000;
BA_ "GenSigTimeoutTime_BCM_NBM" SG_ 2566906905 ElHtrOverheating 5000;
BA_ "CI_SigName" SG_ 2566906905 ElHtrOverheating "Electric Heater Overheating";
BA_ "CI_SigId" SG_ 2566906905 ElHtrOverheating 10932;
BA_ "CI_ParId" SG_ 2566906905 ElHtrOverheating "IB1377";
BA_ "SigType" SG_ 2566906905 StartStopInhibMildHybrid 4;
BA_ "GenSigTimeoutTime_SGW" SG_ 2566906905 StartStopInhibMildHybrid 5000;
BA_ "GenSigTimeoutTime_PCM" SG_ 2566906905 StartStopInhibMildHybrid 5000;
BA_ "GenSigTimeoutTime_BCM_NBM" SG_ 2566906905 StartStopInhibMildHybrid 5000;
BA_ "CI_SigName" SG_ 2566906905 StartStopInhibMildHybrid "Start/Stop Inhibit Mild Hybrid ";
BA_ "CI_SigId" SG_ 2566906905 StartStopInhibMildHybrid 10931;
BA_ "CI_ParId" SG_ 2566906905 StartStopInhibMildHybrid "IB1385";
BA_ "SigType" SG_ 2566906905 AcDischPrs 1;
BA_ "GenSigTimeoutTime_SGW" SG_ 2566906905 AcDischPrs 5000;
BA_ "GenSigTimeoutTime_PCM" SG_ 2566906905 AcDischPrs 5000;
BA_ "GenSigTimeoutTime_BCM_NBM" SG_ 2566906905 AcDischPrs 5000;
BA_ "CI_SigName" SG_ 2566906905 AcDischPrs "Air conditioning discharge pressure";
BA_ "CI_SigId" SG_ 2566906905 AcDischPrs 10930;
BA_ "CI_ParId" SG_ 2566906905 AcDischPrs "IB650";
BA_ "SigType" SG_ 2566906905 AcSuctPrs 1;
BA_ "GenSigTimeoutTime_SGW" SG_ 2566906905 AcSuctPrs 5000;
BA_ "GenSigTimeoutTime_PCM" SG_ 2566906905 AcSuctPrs 5000;
BA_ "GenSigTimeoutTime_BCM_NBM" SG_ 2566906905 AcSuctPrs 5000;
BA_ "CI_SigName" SG_ 2566906905 AcSuctPrs "Air conditioning suction pressure";
BA_ "CI_SigId" SG_ 2566906905 AcSuctPrs 10929;
BA_ "CI_ParId" SG_ 2566906905 AcSuctPrs "IB649";
BA_ "SigType" SG_ 2566906905 AcComprInvSpeedReq 1;
BA_ "GenSigTimeoutTime_SGW" SG_ 2566906905 AcComprInvSpeedReq 5000;
BA_ "GenSigTimeoutTime_PCM" SG_ 2566906905 AcComprInvSpeedReq 5000;
BA_ "GenSigTimeoutTime_BCM_NBM" SG_ 2566906905 AcComprInvSpeedReq 5000;
BA_ "CI_SigName" SG_ 2566906905 AcComprInvSpeedReq "Air conditioning compressor inverter speed request";
BA_ "CI_SigId" SG_ 2566906905 AcComprInvSpeedReq 10928;
BA_ "CI_ParId" SG_ 2566906905 AcComprInvSpeedReq "IB648";
BA_ "SigType" SG_ 2566906905 ElHtrSts 4;
BA_ "GenSigTimeoutTime_SGW" SG_ 2566906905 ElHtrSts 5000;
BA_ "GenSigTimeoutTime_PCM" SG_ 2566906905 ElHtrSts 5000;
BA_ "GenSigTimeoutTime_BCM_NBM" SG_ 2566906905 ElHtrSts 5000;
BA_ "CI_SigName" SG_ 2566906905 ElHtrSts "Electrical heater status";
BA_ "CI_SigId" SG_ 2566906905 ElHtrSts 10927;
BA_ "CI_ParId" SG_ 2566906905 ElHtrSts "IB647";
BA_ "SigType" SG_ 2566906905 ThermHtrSts 4;
BA_ "GenSigTimeoutTime_SGW" SG_ 2566906905 ThermHtrSts 5000;
BA_ "GenSigTimeoutTime_PCM" SG_ 2566906905 ThermHtrSts 5000;
BA_ "GenSigTimeoutTime_BCM_NBM" SG_ 2566906905 ThermHtrSts 5000;
BA_ "CI_SigName" SG_ 2566906905 ThermHtrSts "Thermal heater status";
BA_ "CI_SigId" SG_ 2566906905 ThermHtrSts 10926;
BA_ "CI_ParId" SG_ 2566906905 ThermHtrSts "IB646";
BA_ "SigType" SG_ 2566906905 CirculationSts 4;
BA_ "GenSigTimeoutTime_SGW" SG_ 2566906905 CirculationSts 5000;
BA_ "GenSigTimeoutTime_PCM" SG_ 2566906905 CirculationSts 5000;
BA_ "CI_SigName" SG_ 2566906905 CirculationSts "Circulation status";
BA_ "CI_SigId" SG_ 2566906905 CirculationSts 10925;
BA_ "CI_ParId" SG_ 2566906905 CirculationSts "IB645";
BA_ "SigType" SG_ 2566906905 AcComprInvActvReq 4;
BA_ "GenSigTimeoutTime_SGW" SG_ 2566906905 AcComprInvActvReq 5000;
BA_ "GenSigTimeoutTime_PCM" SG_ 2566906905 AcComprInvActvReq 5000;
BA_ "GenSigTimeoutTime_BCM_NBM" SG_ 2566906905 AcComprInvActvReq 5000;
BA_ "CI_SigName" SG_ 2566906905 AcComprInvActvReq "Air conditioning compressor inverter activation request";
BA_ "CI_SigId" SG_ 2566906905 AcComprInvActvReq 10924;
BA_ "CI_ParId" SG_ 2566906905 AcComprInvActvReq "IB644";
BA_ "SigType" SG_ 2566846467 TransmOilTemp1 1;
BA_ "SPN" SG_ 2566846467 TransmOilTemp1 177;
BA_ "GenSigTimeoutTime_SGW" SG_ 2566846467 TransmOilTemp1 5000;
BA_ "GenSigTimeoutTime_PCM" SG_ 2566846467 TransmOilTemp1 5000;
BA_ "GenSigTimeoutTime_IC_MulticS" SG_ 2566846467 TransmOilTemp1 5000;
BA_ "GenSigTimeoutTime_FMS_FMS5" SG_ 2566846467 TransmOilTemp1 5000;
BA_ "GenSigTimeoutTime_FMS_FMS4" SG_ 2566846467 TransmOilTemp1 5000;
BA_ "GenSigTimeoutTime_BCM_NBM" SG_ 2566846467 TransmOilTemp1 5000;
BA_ "GenSigStartValue" SG_ 2566846467 TransmOilTemp1 8736;
BA_ "CI_SigName" SG_ 2566846467 TransmOilTemp1 "Transmission Oil Temperature 1";
BA_ "CI_SigId" SG_ 2566846467 TransmOilTemp1 635;
BA_ "CI_ParId" SG_ 2566846467 TransmOilTemp1 "177";
BA_ "SigType" SG_ 2566852119 TripRecovEnergy 1;
BA_ "SPN" SG_ 2566852119 TripRecovEnergy 52007;
BA_ "GenSigTimeoutTime_SGW" SG_ 2566852119 TripRecovEnergy 5000;
BA_ "GenSigTimeoutTime_PCM" SG_ 2566852119 TripRecovEnergy 5000;
BA_ "GenSigTimeoutTime_MPPxPTFE2" SG_ 2566852119 TripRecovEnergy 5000;
BA_ "GenSigTimeoutTime_FMS_FMS5" SG_ 2566852119 TripRecovEnergy 5000;
BA_ "GenSigTimeoutTime_FMS_FMS4" SG_ 2566852119 TripRecovEnergy 5000;
BA_ "CI_SigName" SG_ 2566852119 TripRecovEnergy "Trip Recovery Energy ";
BA_ "CI_SigId" SG_ 2566852119 TripRecovEnergy 1905;
BA_ "CI_ParId" SG_ 2566852119 TripRecovEnergy "52007";
BA_ "SigType" SG_ 2566852119 TripAuxEnergy 1;
BA_ "SPN" SG_ 2566852119 TripAuxEnergy 52006;
BA_ "GenSigTimeoutTime_SGW" SG_ 2566852119 TripAuxEnergy 5000;
BA_ "GenSigTimeoutTime_PCM" SG_ 2566852119 TripAuxEnergy 5000;
BA_ "GenSigTimeoutTime_MPPxPTFE2" SG_ 2566852119 TripAuxEnergy 5000;
BA_ "GenSigTimeoutTime_FMS_FMS5" SG_ 2566852119 TripAuxEnergy 5000;
BA_ "GenSigTimeoutTime_FMS_FMS4" SG_ 2566852119 TripAuxEnergy 5000;
BA_ "CI_SigName" SG_ 2566852119 TripAuxEnergy "Trip Auxiliary Energy";
BA_ "CI_SigId" SG_ 2566852119 TripAuxEnergy 1904;
BA_ "CI_ParId" SG_ 2566852119 TripAuxEnergy "52006";
BA_ "SigType" SG_ 2566852119 TripTractEnergy 1;
BA_ "SPN" SG_ 2566852119 TripTractEnergy 52005;
BA_ "GenSigTimeoutTime_SGW" SG_ 2566852119 TripTractEnergy 5000;
BA_ "GenSigTimeoutTime_PCM" SG_ 2566852119 TripTractEnergy 5000;
BA_ "GenSigTimeoutTime_MPPxPTFE2" SG_ 2566852119 TripTractEnergy 5000;
BA_ "GenSigTimeoutTime_FMS_FMS5" SG_ 2566852119 TripTractEnergy 5000;
BA_ "GenSigTimeoutTime_FMS_FMS4" SG_ 2566852119 TripTractEnergy 5000;
BA_ "CI_SigName" SG_ 2566852119 TripTractEnergy "Trip Traction Energy";
BA_ "CI_SigId" SG_ 2566852119 TripTractEnergy 1903;
BA_ "CI_ParId" SG_ 2566852119 TripTractEnergy "52005";
BA_ "SigType" SG_ 2566852119 TripBatEnergy 1;
BA_ "SPN" SG_ 2566852119 TripBatEnergy 52004;
BA_ "GenSigTimeoutTime_SGW" SG_ 2566852119 TripBatEnergy 5000;
BA_ "GenSigTimeoutTime_PCM" SG_ 2566852119 TripBatEnergy 5000;
BA_ "GenSigTimeoutTime_MPPxPTFE2" SG_ 2566852119 TripBatEnergy 5000;
BA_ "GenSigTimeoutTime_FMS_FMS5" SG_ 2566852119 TripBatEnergy 5000;
BA_ "GenSigTimeoutTime_FMS_FMS4" SG_ 2566852119 TripBatEnergy 5000;
BA_ "CI_SigName" SG_ 2566852119 TripBatEnergy "Trip Battery Energy";
BA_ "CI_SigId" SG_ 2566852119 TripBatEnergy 1902;
BA_ "CI_ParId" SG_ 2566852119 TripBatEnergy "52004";
BA_ "SigType" SG_ 2566856261 TripNet24VEnergy 1;
BA_ "GenSigTimeoutTime_SGW" SG_ 2566856261 TripNet24VEnergy 5000;
BA_ "GenSigTimeoutTime_PCM" SG_ 2566856261 TripNet24VEnergy 5000;
BA_ "CI_SigName" SG_ 2566856261 TripNet24VEnergy "Trip Network 24V Energy";
BA_ "CI_SigId" SG_ 2566856261 TripNet24VEnergy 1925;
BA_ "CI_ParId" SG_ 2566856261 TripNet24VEnergy "IB807";
BA_ "SigType" SG_ 2566856261 TripAcEnergy 1;
BA_ "GenSigTimeoutTime_SGW" SG_ 2566856261 TripAcEnergy 5000;
BA_ "GenSigTimeoutTime_PCM" SG_ 2566856261 TripAcEnergy 5000;
BA_ "CI_SigName" SG_ 2566856261 TripAcEnergy "Trip A/C Energy";
BA_ "CI_SigId" SG_ 2566856261 TripAcEnergy 1924;
BA_ "CI_ParId" SG_ 2566856261 TripAcEnergy "IB806";
BA_ "GenSigTimeoutTime_SGW" SG_ 2566749463 LdwSwdOff 5000;
BA_ "GenSigTimeoutTime_PCM" SG_ 2566749463 LdwSwdOff 5000;
BA_ "GenSigTimeoutTime_MPPxPTFE2" SG_ 2566749463 LdwSwdOff 5000;
BA_ "GenSigTimeoutTime_FMS_FMS5" SG_ 2566749463 LdwSwdOff 5000;
BA_ "GenSigTimeoutTime_FMS_FMS4" SG_ 2566749463 LdwSwdOff 5000;
BA_ "CI_SigName" SG_ 2566749463 LdwSwdOff "Lane departure warning switched off";
BA_ "CI_SigId" SG_ 2566749463 LdwSwdOff 14860;
BA_ "CI_ParId" SG_ 2566749463 LdwSwdOff "FMS015";
BA_ "GenSigTimeoutTime_SGW" SG_ 2566749463 EngCompTemp 5000;
BA_ "GenSigTimeoutTime_PCM" SG_ 2566749463 EngCompTemp 5000;
BA_ "GenSigTimeoutTime_MPPxPTFE2" SG_ 2566749463 EngCompTemp 5000;
BA_ "GenSigTimeoutTime_FMS_FMS5" SG_ 2566749463 EngCompTemp 5000;
BA_ "GenSigTimeoutTime_FMS_FMS4" SG_ 2566749463 EngCompTemp 5000;
BA_ "CI_SigName" SG_ 2566749463 EngCompTemp "Engine compartment temperature";
BA_ "CI_SigId" SG_ 2566749463 EngCompTemp 14845;
BA_ "CI_ParId" SG_ 2566749463 EngCompTemp "FMS015";
BA_ "GenSigTimeoutTime_SGW" SG_ 2566749463 SteerFluidLev 5000;
BA_ "GenSigTimeoutTime_PCM" SG_ 2566749463 SteerFluidLev 5000;
BA_ "GenSigTimeoutTime_MPPxPTFE2" SG_ 2566749463 SteerFluidLev 5000;
BA_ "GenSigTimeoutTime_FMS_FMS5" SG_ 2566749463 SteerFluidLev 5000;
BA_ "GenSigTimeoutTime_FMS_FMS4" SG_ 2566749463 SteerFluidLev 5000;
BA_ "CI_SigName" SG_ 2566749463 SteerFluidLev "Steering fluid level";
BA_ "CI_SigId" SG_ 2566749463 SteerFluidLev 14830;
BA_ "CI_ParId" SG_ 2566749463 SteerFluidLev "FMS015";
BA_ "GenSigTimeoutTime_SGW" SG_ 2566749463 FrontFogLight 5000;
BA_ "GenSigTimeoutTime_PCM" SG_ 2566749463 FrontFogLight 5000;
BA_ "GenSigTimeoutTime_MPPxPTFE2" SG_ 2566749463 FrontFogLight 5000;
BA_ "GenSigTimeoutTime_FMS_FMS5" SG_ 2566749463 FrontFogLight 5000;
BA_ "GenSigTimeoutTime_FMS_FMS4" SG_ 2566749463 FrontFogLight 5000;
BA_ "CI_SigName" SG_ 2566749463 FrontFogLight "Front fog light";
BA_ "CI_SigId" SG_ 2566749463 FrontFogLight 3217;
BA_ "CI_ParId" SG_ 2566749463 FrontFogLight "FMS015";
BA_ "GenSigTimeoutTime_SGW" SG_ 2566749463 EscSwdOff 5000;
BA_ "GenSigTimeoutTime_PCM" SG_ 2566749463 EscSwdOff 5000;
BA_ "GenSigTimeoutTime_MPPxPTFE2" SG_ 2566749463 EscSwdOff 5000;
BA_ "GenSigTimeoutTime_FMS_FMS5" SG_ 2566749463 EscSwdOff 5000;
BA_ "GenSigTimeoutTime_FMS_FMS4" SG_ 2566749463 EscSwdOff 5000;
BA_ "CI_SigName" SG_ 2566749463 EscSwdOff "ESC switched off";
BA_ "CI_SigId" SG_ 2566749463 EscSwdOff 14859;
BA_ "CI_ParId" SG_ 2566749463 EscSwdOff "FMS014";
BA_ "GenSigTimeoutTime_SGW" SG_ 2566749463 Kneel 5000;
BA_ "GenSigTimeoutTime_PCM" SG_ 2566749463 Kneel 5000;
BA_ "GenSigTimeoutTime_MPPxPTFE2" SG_ 2566749463 Kneel 5000;
BA_ "GenSigTimeoutTime_FMS_FMS5" SG_ 2566749463 Kneel 5000;
BA_ "GenSigTimeoutTime_FMS_FMS4" SG_ 2566749463 Kneel 5000;
BA_ "CI_SigName" SG_ 2566749463 Kneel "Kneeling";
BA_ "CI_SigId" SG_ 2566749463 Kneel 14844;
BA_ "CI_ParId" SG_ 2566749463 Kneel "FMS014";
BA_ "GenSigTimeoutTime_SGW" SG_ 2566749463 EngCoolLev 5000;
BA_ "GenSigTimeoutTime_PCM" SG_ 2566749463 EngCoolLev 5000;
BA_ "GenSigTimeoutTime_MPPxPTFE2" SG_ 2566749463 EngCoolLev 5000;
BA_ "GenSigTimeoutTime_FMS_FMS5" SG_ 2566749463 EngCoolLev 5000;
BA_ "GenSigTimeoutTime_FMS_FMS4" SG_ 2566749463 EngCoolLev 5000;
BA_ "CI_SigName" SG_ 2566749463 EngCoolLev "Engine coolant level";
BA_ "CI_SigId" SG_ 2566749463 EngCoolLev 14829;
BA_ "CI_ParId" SG_ 2566749463 EngCoolLev "FMS014";
BA_ "GenSigTimeoutTime_SGW" SG_ 2566749463 PosLightSideLight 5000;
BA_ "GenSigTimeoutTime_PCM" SG_ 2566749463 PosLightSideLight 5000;
BA_ "GenSigTimeoutTime_MPPxPTFE2" SG_ 2566749463 PosLightSideLight 5000;
BA_ "GenSigTimeoutTime_FMS_FMS5" SG_ 2566749463 PosLightSideLight 5000;
BA_ "GenSigTimeoutTime_FMS_FMS4" SG_ 2566749463 PosLightSideLight 5000;
BA_ "CI_SigName" SG_ 2566749463 PosLightSideLight "Position lights,side lights";
BA_ "CI_SigId" SG_ 2566749463 PosLightSideLight 3216;
BA_ "CI_ParId" SG_ 2566749463 PosLightSideLight "FMS014";
BA_ "GenSigTimeoutTime_SGW" SG_ 2566749463 TcoInd 5000;
BA_ "GenSigTimeoutTime_PCM" SG_ 2566749463 TcoInd 5000;
BA_ "GenSigTimeoutTime_MPPxPTFE2" SG_ 2566749463 TcoInd 5000;
BA_ "GenSigTimeoutTime_FMS_FMS5" SG_ 2566749463 TcoInd 5000;
BA_ "GenSigTimeoutTime_FMS_FMS4" SG_ 2566749463 TcoInd 5000;
BA_ "CI_SigName" SG_ 2566749463 TcoInd "Tachograph indication";
BA_ "CI_SigId" SG_ 2566749463 TcoInd 14858;
BA_ "CI_ParId" SG_ 2566749463 TcoInd "FMS013";
BA_ "GenSigTimeoutTime_SGW" SG_ 2566749463 Low 5000;
BA_ "GenSigTimeoutTime_PCM" SG_ 2566749463 Low 5000;
BA_ "GenSigTimeoutTime_MPPxPTFE2" SG_ 2566749463 Low 5000;
BA_ "GenSigTimeoutTime_FMS_FMS5" SG_ 2566749463 Low 5000;
BA_ "GenSigTimeoutTime_FMS_FMS4" SG_ 2566749463 Low 5000;
BA_ "CI_SigName" SG_ 2566749463 Low "Lowering";
BA_ "CI_SigId" SG_ 2566749463 Low 14843;
BA_ "CI_ParId" SG_ 2566749463 Low "FMS013";
BA_ "GenSigTimeoutTime_SGW" SG_ 2566749463 EngOilLev_FD7D17 5000;
BA_ "GenSigTimeoutTime_PCM" SG_ 2566749463 EngOilLev_FD7D17 5000;
BA_ "GenSigTimeoutTime_MPPxPTFE2" SG_ 2566749463 EngOilLev_FD7D17 5000;
BA_ "GenSigTimeoutTime_FMS_FMS5" SG_ 2566749463 EngOilLev_FD7D17 5000;
BA_ "GenSigTimeoutTime_FMS_FMS4" SG_ 2566749463 EngOilLev_FD7D17 5000;
BA_ "CI_SigName" SG_ 2566749463 EngOilLev_FD7D17 "Engine oil level";
BA_ "CI_SigId" SG_ 2566749463 EngOilLev_FD7D17 14828;
BA_ "CI_ParId" SG_ 2566749463 EngOilLev_FD7D17 "FMS013";
BA_ "GenSigTimeoutTime_SGW" SG_ 2566749463 EngOil 5000;
BA_ "GenSigTimeoutTime_PCM" SG_ 2566749463 EngOil 5000;
BA_ "GenSigTimeoutTime_MPPxPTFE2" SG_ 2566749463 EngOil 5000;
BA_ "GenSigTimeoutTime_FMS_FMS5" SG_ 2566749463 EngOil 5000;
BA_ "GenSigTimeoutTime_FMS_FMS4" SG_ 2566749463 EngOil 5000;
BA_ "CI_SigName" SG_ 2566749463 EngOil "Engine oil";
BA_ "CI_SigId" SG_ 2566749463 EngOil 3215;
BA_ "CI_ParId" SG_ 2566749463 EngOil "FMS013";
BA_ "GenSigTimeoutTime_SGW" SG_ 2566749463 EbsTrail12 5000;
BA_ "GenSigTimeoutTime_PCM" SG_ 2566749463 EbsTrail12 5000;
BA_ "GenSigTimeoutTime_MPPxPTFE2" SG_ 2566749463 EbsTrail12 5000;
BA_ "GenSigTimeoutTime_FMS_FMS5" SG_ 2566749463 EbsTrail12 5000;
BA_ "GenSigTimeoutTime_FMS_FMS4" SG_ 2566749463 EbsTrail12 5000;
BA_ "CI_SigName" SG_ 2566749463 EbsTrail12 "EBS Trailer 1,2";
BA_ "CI_SigId" SG_ 2566749463 EbsTrail12 14857;
BA_ "CI_ParId" SG_ 2566749463 EbsTrail12 "FMS012";
BA_ "GenSigTimeoutTime_SGW" SG_ 2566749463 Raising 5000;
BA_ "GenSigTimeoutTime_PCM" SG_ 2566749463 Raising 5000;
BA_ "GenSigTimeoutTime_MPPxPTFE2" SG_ 2566749463 Raising 5000;
BA_ "GenSigTimeoutTime_FMS_FMS5" SG_ 2566749463 Raising 5000;
BA_ "GenSigTimeoutTime_FMS_FMS4" SG_ 2566749463 Raising 5000;
BA_ "CI_SigName" SG_ 2566749463 Raising "Raising";
BA_ "CI_SigId" SG_ 2566749463 Raising 14842;
BA_ "CI_ParId" SG_ 2566749463 Raising "FMS012";
BA_ "GenSigTimeoutTime_SGW" SG_ 2566749463 EngOilTemp 5000;
BA_ "GenSigTimeoutTime_PCM" SG_ 2566749463 EngOilTemp 5000;
BA_ "GenSigTimeoutTime_MPPxPTFE2" SG_ 2566749463 EngOilTemp 5000;
BA_ "GenSigTimeoutTime_FMS_FMS5" SG_ 2566749463 EngOilTemp 5000;
BA_ "GenSigTimeoutTime_FMS_FMS4" SG_ 2566749463 EngOilTemp 5000;
BA_ "CI_SigName" SG_ 2566749463 EngOilTemp "Engine oil temperature";
BA_ "CI_SigId" SG_ 2566749463 EngOilTemp 14827;
BA_ "CI_ParId" SG_ 2566749463 EngOilTemp "FMS012";
BA_ "GenSigTimeoutTime_SGW" SG_ 2566749463 BatChgCond 5000;
BA_ "GenSigTimeoutTime_PCM" SG_ 2566749463 BatChgCond 5000;
BA_ "GenSigTimeoutTime_MPPxPTFE2" SG_ 2566749463 BatChgCond 5000;
BA_ "GenSigTimeoutTime_FMS_FMS5" SG_ 2566749463 BatChgCond 5000;
BA_ "GenSigTimeoutTime_FMS_FMS4" SG_ 2566749463 BatChgCond 5000;
BA_ "CI_SigName" SG_ 2566749463 BatChgCond "Battery charging condition";
BA_ "CI_SigId" SG_ 2566749463 BatChgCond 3214;
BA_ "CI_ParId" SG_ 2566749463 BatChgCond "FMS012";
BA_ "GenSigTimeoutTime_SGW" SG_ 2566749463 Airbag 5000;
BA_ "GenSigTimeoutTime_PCM" SG_ 2566749463 Airbag 5000;
BA_ "GenSigTimeoutTime_MPPxPTFE2" SG_ 2566749463 Airbag 5000;
BA_ "GenSigTimeoutTime_FMS_FMS5" SG_ 2566749463 Airbag 5000;
BA_ "GenSigTimeoutTime_FMS_FMS4" SG_ 2566749463 Airbag 5000;
BA_ "CI_SigName" SG_ 2566749463 Airbag "Airbag";
BA_ "CI_SigId" SG_ 2566749463 Airbag 14856;
BA_ "CI_ParId" SG_ 2566749463 Airbag "FMS011";
BA_ "GenSigTimeoutTime_SGW" SG_ 2566749463 AdblueLev 5000;
BA_ "GenSigTimeoutTime_PCM" SG_ 2566749463 AdblueLev 5000;
BA_ "GenSigTimeoutTime_MPPxPTFE2" SG_ 2566749463 AdblueLev 5000;
BA_ "GenSigTimeoutTime_FMS_FMS5" SG_ 2566749463 AdblueLev 5000;
BA_ "GenSigTimeoutTime_FMS_FMS4" SG_ 2566749463 AdblueLev 5000;
BA_ "CI_SigName" SG_ 2566749463 AdblueLev "AdBlue level";
BA_ "CI_SigId" SG_ 2566749463 AdblueLev 14841;
BA_ "CI_ParId" SG_ 2566749463 AdblueLev "FMS011";
BA_ "GenSigTimeoutTime_SGW" SG_ 2566749463 Malf_GenFail 5000;
BA_ "GenSigTimeoutTime_PCM" SG_ 2566749463 Malf_GenFail 5000;
BA_ "GenSigTimeoutTime_MPPxPTFE2" SG_ 2566749463 Malf_GenFail 5000;
BA_ "GenSigTimeoutTime_FMS_FMS5" SG_ 2566749463 Malf_GenFail 5000;
BA_ "GenSigTimeoutTime_FMS_FMS4" SG_ 2566749463 Malf_GenFail 5000;
BA_ "CI_SigName" SG_ 2566749463 Malf_GenFail "Malfunction/general failure";
BA_ "CI_SigId" SG_ 2566749463 Malf_GenFail 14826;
BA_ "CI_ParId" SG_ 2566749463 Malf_GenFail "FMS011";
BA_ "GenSigTimeoutTime_SGW" SG_ 2566749463 EngCoolTemp_FD7D17 5000;
BA_ "GenSigTimeoutTime_PCM" SG_ 2566749463 EngCoolTemp_FD7D17 5000;
BA_ "GenSigTimeoutTime_MPPxPTFE2" SG_ 2566749463 EngCoolTemp_FD7D17 5000;
BA_ "GenSigTimeoutTime_FMS_FMS5" SG_ 2566749463 EngCoolTemp_FD7D17 5000;
BA_ "GenSigTimeoutTime_FMS_FMS4" SG_ 2566749463 EngCoolTemp_FD7D17 5000;
BA_ "CI_SigName" SG_ 2566749463 EngCoolTemp_FD7D17 "Engine coolant temperature";
BA_ "CI_SigId" SG_ 2566749463 EngCoolTemp_FD7D17 3213;
BA_ "CI_ParId" SG_ 2566749463 EngCoolTemp_FD7D17 "FMS011";
BA_ "GenSigTimeoutTime_SGW" SG_ 2566749463 AbsTrail12 5000;
BA_ "GenSigTimeoutTime_PCM" SG_ 2566749463 AbsTrail12 5000;
BA_ "GenSigTimeoutTime_MPPxPTFE2" SG_ 2566749463 AbsTrail12 5000;
BA_ "GenSigTimeoutTime_FMS_FMS5" SG_ 2566749463 AbsTrail12 5000;
BA_ "GenSigTimeoutTime_FMS_FMS4" SG_ 2566749463 AbsTrail12 5000;
BA_ "CI_SigName" SG_ 2566749463 AbsTrail12 "ABS Trailer 1,2";
BA_ "CI_SigId" SG_ 2566749463 AbsTrail12 14855;
BA_ "CI_ParId" SG_ 2566749463 AbsTrail12 "FMS010";
BA_ "GenSigTimeoutTime_SGW" SG_ 2566749463 BusStopBrk 5000;
BA_ "GenSigTimeoutTime_PCM" SG_ 2566749463 BusStopBrk 5000;
BA_ "GenSigTimeoutTime_MPPxPTFE2" SG_ 2566749463 BusStopBrk 5000;
BA_ "GenSigTimeoutTime_FMS_FMS5" SG_ 2566749463 BusStopBrk 5000;
BA_ "GenSigTimeoutTime_FMS_FMS4" SG_ 2566749463 BusStopBrk 5000;
BA_ "CI_SigName" SG_ 2566749463 BusStopBrk "Bus stop brake";
BA_ "CI_SigId" SG_ 2566749463 BusStopBrk 14840;
BA_ "CI_ParId" SG_ 2566749463 BusStopBrk "FMS010";
BA_ "GenSigTimeoutTime_SGW" SG_ 2566749463 TireFail_Malf 5000;
BA_ "GenSigTimeoutTime_PCM" SG_ 2566749463 TireFail_Malf 5000;
BA_ "GenSigTimeoutTime_MPPxPTFE2" SG_ 2566749463 TireFail_Malf 5000;
BA_ "GenSigTimeoutTime_FMS_FMS5" SG_ 2566749463 TireFail_Malf 5000;
BA_ "GenSigTimeoutTime_FMS_FMS4" SG_ 2566749463 TireFail_Malf 5000;
BA_ "CI_SigName" SG_ 2566749463 TireFail_Malf "Tire failure/malfunction";
BA_ "CI_SigId" SG_ 2566749463 TireFail_Malf 14825;
BA_ "CI_ParId" SG_ 2566749463 TireFail_Malf "FMS010";
BA_ "GenSigTimeoutTime_SGW" SG_ 2566749463 FuelLev 5000;
BA_ "GenSigTimeoutTime_PCM" SG_ 2566749463 FuelLev 5000;
BA_ "GenSigTimeoutTime_MPPxPTFE2" SG_ 2566749463 FuelLev 5000;
BA_ "GenSigTimeoutTime_FMS_FMS5" SG_ 2566749463 FuelLev 5000;
BA_ "GenSigTimeoutTime_FMS_FMS4" SG_ 2566749463 FuelLev 5000;
BA_ "CI_SigName" SG_ 2566749463 FuelLev "Fuel level";
BA_ "CI_SigId" SG_ 2566749463 FuelLev 3212;
BA_ "CI_ParId" SG_ 2566749463 FuelLev "FMS010";
BA_ "GenSigTimeoutTime_SGW" SG_ 2566749463 BatPakCool 5000;
BA_ "GenSigTimeoutTime_PCM" SG_ 2566749463 BatPakCool 5000;
BA_ "GenSigTimeoutTime_MPPxPTFE2" SG_ 2566749463 BatPakCool 5000;
BA_ "GenSigTimeoutTime_FMS_FMS5" SG_ 2566749463 BatPakCool 5000;
BA_ "GenSigTimeoutTime_FMS_FMS4" SG_ 2566749463 BatPakCool 5000;
BA_ "CI_SigName" SG_ 2566749463 BatPakCool "Battery pack cooling";
BA_ "CI_SigId" SG_ 2566749463 BatPakCool 14869;
BA_ "CI_ParId" SG_ 2566749463 BatPakCool "FMS009";
BA_ "GenSigTimeoutTime_SGW" SG_ 2566749463 TrailConn 5000;
BA_ "GenSigTimeoutTime_PCM" SG_ 2566749463 TrailConn 5000;
BA_ "GenSigTimeoutTime_MPPxPTFE2" SG_ 2566749463 TrailConn 5000;
BA_ "GenSigTimeoutTime_FMS_FMS5" SG_ 2566749463 TrailConn 5000;
BA_ "GenSigTimeoutTime_FMS_FMS4" SG_ 2566749463 TrailConn 5000;
BA_ "CI_SigName" SG_ 2566749463 TrailConn "Trailer connected";
BA_ "CI_SigId" SG_ 2566749463 TrailConn 14854;
BA_ "CI_ParId" SG_ 2566749463 TrailConn "FMS009";
BA_ "GenSigTimeoutTime_SGW" SG_ 2566749463 PramReq 5000;
BA_ "GenSigTimeoutTime_PCM" SG_ 2566749463 PramReq 5000;
BA_ "GenSigTimeoutTime_MPPxPTFE2" SG_ 2566749463 PramReq 5000;
BA_ "GenSigTimeoutTime_FMS_FMS5" SG_ 2566749463 PramReq 5000;
BA_ "GenSigTimeoutTime_FMS_FMS4" SG_ 2566749463 PramReq 5000;
BA_ "CI_SigName" SG_ 2566749463 PramReq "Pram request";
BA_ "CI_SigId" SG_ 2566749463 PramReq 14839;
BA_ "CI_ParId" SG_ 2566749463 PramReq "FMS009";
BA_ "GenSigTimeoutTime_SGW" SG_ 2566749463 Windsh_WindshWasherFluid 5000;
BA_ "GenSigTimeoutTime_PCM" SG_ 2566749463 Windsh_WindshWasherFluid 5000;
BA_ "GenSigTimeoutTime_MPPxPTFE2" SG_ 2566749463 Windsh_WindshWasherFluid 5000;
BA_ "GenSigTimeoutTime_FMS_FMS5" SG_ 2566749463 Windsh_WindshWasherFluid 5000;
BA_ "GenSigTimeoutTime_FMS_FMS4" SG_ 2566749463 Windsh_WindshWasherFluid 5000;
BA_ "CI_SigName" SG_ 2566749463 Windsh_WindshWasherFluid "Windscreen/windshield washer fluid";
BA_ "CI_SigId" SG_ 2566749463 Windsh_WindshWasherFluid 14824;
BA_ "CI_ParId" SG_ 2566749463 Windsh_WindshWasherFluid "FMS009";
BA_ "GenSigTimeoutTime_SGW" SG_ 2566749463 HatchOpen 5000;
BA_ "GenSigTimeoutTime_PCM" SG_ 2566749463 HatchOpen 5000;
BA_ "GenSigTimeoutTime_MPPxPTFE2" SG_ 2566749463 HatchOpen 5000;
BA_ "GenSigTimeoutTime_FMS_FMS5" SG_ 2566749463 HatchOpen 5000;
BA_ "GenSigTimeoutTime_FMS_FMS4" SG_ 2566749463 HatchOpen 5000;
BA_ "CI_SigName" SG_ 2566749463 HatchOpen "Hatch open";
BA_ "CI_SigId" SG_ 2566749463 HatchOpen 3211;
BA_ "CI_ParId" SG_ 2566749463 HatchOpen "FMS009";
BA_ "GenSigTimeoutTime_SGW" SG_ 2566749463 LimPerfElMot 5000;
BA_ "GenSigTimeoutTime_PCM" SG_ 2566749463 LimPerfElMot 5000;
BA_ "GenSigTimeoutTime_MPPxPTFE2" SG_ 2566749463 LimPerfElMot 5000;
BA_ "GenSigTimeoutTime_FMS_FMS5" SG_ 2566749463 LimPerfElMot 5000;
BA_ "GenSigTimeoutTime_FMS_FMS4" SG_ 2566749463 LimPerfElMot 5000;
BA_ "CI_SigName" SG_ 2566749463 LimPerfElMot "Limited performance electric motor";
BA_ "CI_SigId" SG_ 2566749463 LimPerfElMot 14868;
BA_ "CI_ParId" SG_ 2566749463 LimPerfElMot "FMS008";
BA_ "GenSigTimeoutTime_SGW" SG_ 2566749463 Acc 5000;
BA_ "GenSigTimeoutTime_PCM" SG_ 2566749463 Acc 5000;
BA_ "GenSigTimeoutTime_MPPxPTFE2" SG_ 2566749463 Acc 5000;
BA_ "GenSigTimeoutTime_FMS_FMS5" SG_ 2566749463 Acc 5000;
BA_ "GenSigTimeoutTime_FMS_FMS4" SG_ 2566749463 Acc 5000;
BA_ "CI_SigName" SG_ 2566749463 Acc "ACC";
BA_ "CI_SigId" SG_ 2566749463 Acc 14853;
BA_ "CI_ParId" SG_ 2566749463 Acc "FMS008";
BA_ "GenSigTimeoutTime_SGW" SG_ 2566749463 StopReq 5000;
BA_ "GenSigTimeoutTime_PCM" SG_ 2566749463 StopReq 5000;
BA_ "GenSigTimeoutTime_MPPxPTFE2" SG_ 2566749463 StopReq 5000;
BA_ "GenSigTimeoutTime_FMS_FMS5" SG_ 2566749463 StopReq 5000;
BA_ "GenSigTimeoutTime_FMS_FMS4" SG_ 2566749463 StopReq 5000;
BA_ "CI_SigName" SG_ 2566749463 StopReq "Stop Request";
BA_ "CI_SigId" SG_ 2566749463 StopReq 14838;
BA_ "CI_ParId" SG_ 2566749463 StopReq "FMS008";
BA_ "GenSigTimeoutTime_SGW" SG_ 2566749463 WornBrkLin 5000;
BA_ "GenSigTimeoutTime_PCM" SG_ 2566749463 WornBrkLin 5000;
BA_ "GenSigTimeoutTime_MPPxPTFE2" SG_ 2566749463 WornBrkLin 5000;
BA_ "GenSigTimeoutTime_FMS_FMS5" SG_ 2566749463 WornBrkLin 5000;
BA_ "GenSigTimeoutTime_FMS_FMS4" SG_ 2566749463 WornBrkLin 5000;
BA_ "CI_SigName" SG_ 2566749463 WornBrkLin "Worn brake linings";
BA_ "CI_SigId" SG_ 2566749463 WornBrkLin 14823;
BA_ "CI_ParId" SG_ 2566749463 WornBrkLin "FMS008";
BA_ "GenSigTimeoutTime_SGW" SG_ 2566749463 BrkFail_BrkSysMalf 5000;
BA_ "GenSigTimeoutTime_PCM" SG_ 2566749463 BrkFail_BrkSysMalf 5000;
BA_ "GenSigTimeoutTime_MPPxPTFE2" SG_ 2566749463 BrkFail_BrkSysMalf 5000;
BA_ "GenSigTimeoutTime_FMS_FMS5" SG_ 2566749463 BrkFail_BrkSysMalf 5000;
BA_ "GenSigTimeoutTime_FMS_FMS4" SG_ 2566749463 BrkFail_BrkSysMalf 5000;
BA_ "CI_SigName" SG_ 2566749463 BrkFail_BrkSysMalf "Brake failure/brake system malfunction";
BA_ "CI_SigId" SG_ 2566749463 BrkFail_BrkSysMalf 3210;
BA_ "CI_ParId" SG_ 2566749463 BrkFail_BrkSysMalf "FMS008";
BA_ "GenSigTimeoutTime_SGW" SG_ 2566749463 BatPakTemp 5000;
BA_ "GenSigTimeoutTime_PCM" SG_ 2566749463 BatPakTemp 5000;
BA_ "GenSigTimeoutTime_MPPxPTFE2" SG_ 2566749463 BatPakTemp 5000;
BA_ "GenSigTimeoutTime_FMS_FMS5" SG_ 2566749463 BatPakTemp 5000;
BA_ "GenSigTimeoutTime_FMS_FMS4" SG_ 2566749463 BatPakTemp 5000;
BA_ "CI_SigName" SG_ 2566749463 BatPakTemp "Battery pack temperature ";
BA_ "CI_SigId" SG_ 2566749463 BatPakTemp 14867;
BA_ "CI_ParId" SG_ 2566749463 BatPakTemp "FMS007";
BA_ "GenSigTimeoutTime_SGW" SG_ 2566749463 Aebs 5000;
BA_ "GenSigTimeoutTime_PCM" SG_ 2566749463 Aebs 5000;
BA_ "GenSigTimeoutTime_MPPxPTFE2" SG_ 2566749463 Aebs 5000;
BA_ "GenSigTimeoutTime_FMS_FMS5" SG_ 2566749463 Aebs 5000;
BA_ "GenSigTimeoutTime_FMS_FMS4" SG_ 2566749463 Aebs 5000;
BA_ "CI_SigName" SG_ 2566749463 Aebs "Advanced emergency braking system";
BA_ "CI_SigId" SG_ 2566749463 Aebs 14852;
BA_ "CI_ParId" SG_ 2566749463 Aebs "FMS007";
BA_ "GenSigTimeoutTime_SGW" SG_ 2566749463 Artic 5000;
BA_ "GenSigTimeoutTime_PCM" SG_ 2566749463 Artic 5000;
BA_ "GenSigTimeoutTime_MPPxPTFE2" SG_ 2566749463 Artic 5000;
BA_ "GenSigTimeoutTime_FMS_FMS5" SG_ 2566749463 Artic 5000;
BA_ "GenSigTimeoutTime_FMS_FMS4" SG_ 2566749463 Artic 5000;
BA_ "CI_SigName" SG_ 2566749463 Artic "Articulation";
BA_ "CI_SigId" SG_ 2566749463 Artic 14837;
BA_ "CI_ParId" SG_ 2566749463 Artic "FMS007";
BA_ "GenSigTimeoutTime_SGW" SG_ 2566749463 AntiLckBrkSysFail 5000;
BA_ "GenSigTimeoutTime_PCM" SG_ 2566749463 AntiLckBrkSysFail 5000;
BA_ "GenSigTimeoutTime_MPPxPTFE2" SG_ 2566749463 AntiLckBrkSysFail 5000;
BA_ "GenSigTimeoutTime_FMS_FMS5" SG_ 2566749463 AntiLckBrkSysFail 5000;
BA_ "GenSigTimeoutTime_FMS_FMS4" SG_ 2566749463 AntiLckBrkSysFail 5000;
BA_ "CI_SigName" SG_ 2566749463 AntiLckBrkSysFail "Anti-lock brake system failure";
BA_ "CI_SigId" SG_ 2566749463 AntiLckBrkSysFail 14822;
BA_ "CI_ParId" SG_ 2566749463 AntiLckBrkSysFail "FMS007";
BA_ "GenSigTimeoutTime_SGW" SG_ 2566749463 ParkBrk 5000;
BA_ "GenSigTimeoutTime_PCM" SG_ 2566749463 ParkBrk 5000;
BA_ "GenSigTimeoutTime_MPPxPTFE2" SG_ 2566749463 ParkBrk 5000;
BA_ "GenSigTimeoutTime_FMS_FMS5" SG_ 2566749463 ParkBrk 5000;
BA_ "GenSigTimeoutTime_FMS_FMS4" SG_ 2566749463 ParkBrk 5000;
BA_ "CI_SigName" SG_ 2566749463 ParkBrk "Parking Brake";
BA_ "CI_SigId" SG_ 2566749463 ParkBrk 3209;
BA_ "CI_ParId" SG_ 2566749463 ParkBrk "FMS007";
BA_ "GenSigTimeoutTime_SGW" SG_ 2566749463 highVsysCaution 5000;
BA_ "GenSigTimeoutTime_PCM" SG_ 2566749463 highVsysCaution 5000;
BA_ "GenSigTimeoutTime_MPPxPTFE2" SG_ 2566749463 highVsysCaution 5000;
BA_ "GenSigTimeoutTime_FMS_FMS5" SG_ 2566749463 highVsysCaution 5000;
BA_ "GenSigTimeoutTime_FMS_FMS4" SG_ 2566749463 highVsysCaution 5000;
BA_ "CI_SigName" SG_ 2566749463 highVsysCaution "High voltage system caution";
BA_ "CI_SigId" SG_ 2566749463 highVsysCaution 14866;
BA_ "CI_ParId" SG_ 2566749463 highVsysCaution "FMS006";
BA_ "GenSigTimeoutTime_SGW" SG_ 2566749463 LaneDepInd 5000;
BA_ "GenSigTimeoutTime_PCM" SG_ 2566749463 LaneDepInd 5000;
BA_ "GenSigTimeoutTime_MPPxPTFE2" SG_ 2566749463 LaneDepInd 5000;
BA_ "GenSigTimeoutTime_FMS_FMS5" SG_ 2566749463 LaneDepInd 5000;
BA_ "GenSigTimeoutTime_FMS_FMS4" SG_ 2566749463 LaneDepInd 5000;
BA_ "CI_SigName" SG_ 2566749463 LaneDepInd "Lane departure indication";
BA_ "CI_SigId" SG_ 2566749463 LaneDepInd 14851;
BA_ "CI_ParId" SG_ 2566749463 LaneDepInd "FMS006";
BA_ "GenSigTimeoutTime_SGW" SG_ 2566749463 BrkLight 5000;
BA_ "GenSigTimeoutTime_PCM" SG_ 2566749463 BrkLight 5000;
BA_ "GenSigTimeoutTime_MPPxPTFE2" SG_ 2566749463 BrkLight 5000;
BA_ "GenSigTimeoutTime_FMS_FMS5" SG_ 2566749463 BrkLight 5000;
BA_ "GenSigTimeoutTime_FMS_FMS4" SG_ 2566749463 BrkLight 5000;
BA_ "CI_SigName" SG_ 2566749463 BrkLight "Brake lights";
BA_ "CI_SigId" SG_ 2566749463 BrkLight 14836;
BA_ "CI_ParId" SG_ 2566749463 BrkLight "FMS006";
BA_ "GenSigTimeoutTime_SGW" SG_ 2566749463 TransmFail_Malf 5000;
BA_ "GenSigTimeoutTime_PCM" SG_ 2566749463 TransmFail_Malf 5000;
BA_ "GenSigTimeoutTime_MPPxPTFE2" SG_ 2566749463 TransmFail_Malf 5000;
BA_ "GenSigTimeoutTime_FMS_FMS5" SG_ 2566749463 TransmFail_Malf 5000;
BA_ "GenSigTimeoutTime_FMS_FMS4" SG_ 2566749463 TransmFail_Malf 5000;
BA_ "CI_SigName" SG_ 2566749463 TransmFail_Malf "Transmission failure/malfunction";
BA_ "CI_SigId" SG_ 2566749463 TransmFail_Malf 14821;
BA_ "CI_ParId" SG_ 2566749463 TransmFail_Malf "FMS006";
BA_ "GenSigTimeoutTime_SGW" SG_ 2566749463 ProvDisOrHandiPers 5000;
BA_ "GenSigTimeoutTime_PCM" SG_ 2566749463 ProvDisOrHandiPers 5000;
BA_ "GenSigTimeoutTime_MPPxPTFE2" SG_ 2566749463 ProvDisOrHandiPers 5000;
BA_ "GenSigTimeoutTime_FMS_FMS5" SG_ 2566749463 ProvDisOrHandiPers 5000;
BA_ "GenSigTimeoutTime_FMS_FMS4" SG_ 2566749463 ProvDisOrHandiPers 5000;
BA_ "CI_SigName" SG_ 2566749463 ProvDisOrHandiPers "Provision for the disabled or handicapped persons";
BA_ "CI_SigId" SG_ 2566749463 ProvDisOrHandiPers 3208;
BA_ "CI_ParId" SG_ 2566749463 ProvDisOrHandiPers "FMS006";
BA_ "GenSigTimeoutTime_SGW" SG_ 2566749463 BatPak 5000;
BA_ "GenSigTimeoutTime_PCM" SG_ 2566749463 BatPak 5000;
BA_ "GenSigTimeoutTime_MPPxPTFE2" SG_ 2566749463 BatPak 5000;
BA_ "GenSigTimeoutTime_FMS_FMS5" SG_ 2566749463 BatPak 5000;
BA_ "GenSigTimeoutTime_FMS_FMS4" SG_ 2566749463 BatPak 5000;
BA_ "CI_SigName" SG_ 2566749463 BatPak "Battery pack";
BA_ "CI_SigId" SG_ 2566749463 BatPak 14865;
BA_ "CI_ParId" SG_ 2566749463 BatPak "FMS005";
BA_ "GenSigTimeoutTime_SGW" SG_ 2566749463 Ebs 5000;
BA_ "GenSigTimeoutTime_PCM" SG_ 2566749463 Ebs 5000;
BA_ "GenSigTimeoutTime_MPPxPTFE2" SG_ 2566749463 Ebs 5000;
BA_ "GenSigTimeoutTime_FMS_FMS5" SG_ 2566749463 Ebs 5000;
BA_ "GenSigTimeoutTime_FMS_FMS4" SG_ 2566749463 Ebs 5000;
BA_ "CI_SigName" SG_ 2566749463 Ebs "EBS";
BA_ "CI_SigId" SG_ 2566749463 Ebs 14850;
BA_ "CI_ParId" SG_ 2566749463 Ebs "FMS005";
BA_ "GenSigTimeoutTime_SGW" SG_ 2566749463 EscInd 5000;
BA_ "GenSigTimeoutTime_PCM" SG_ 2566749463 EscInd 5000;
BA_ "GenSigTimeoutTime_MPPxPTFE2" SG_ 2566749463 EscInd 5000;
BA_ "GenSigTimeoutTime_FMS_FMS5" SG_ 2566749463 EscInd 5000;
BA_ "GenSigTimeoutTime_FMS_FMS4" SG_ 2566749463 EscInd 5000;
BA_ "CI_SigName" SG_ 2566749463 EscInd "ESC indication";
BA_ "CI_SigId" SG_ 2566749463 EscInd 14835;
BA_ "CI_ParId" SG_ 2566749463 EscInd "FMS005";
BA_ "GenSigTimeoutTime_SGW" SG_ 2566749463 TransmFluidTemp 5000;
BA_ "GenSigTimeoutTime_PCM" SG_ 2566749463 TransmFluidTemp 5000;
BA_ "GenSigTimeoutTime_MPPxPTFE2" SG_ 2566749463 TransmFluidTemp 5000;
BA_ "GenSigTimeoutTime_FMS_FMS5" SG_ 2566749463 TransmFluidTemp 5000;
BA_ "GenSigTimeoutTime_FMS_FMS4" SG_ 2566749463 TransmFluidTemp 5000;
BA_ "CI_SigName" SG_ 2566749463 TransmFluidTemp "Transmission fluid temperature";
BA_ "CI_SigId" SG_ 2566749463 TransmFluidTemp 14820;
BA_ "CI_ParId" SG_ 2566749463 TransmFluidTemp "FMS005";
BA_ "GenSigTimeoutTime_SGW" SG_ 2566749463 HazardWarn 5000;
BA_ "GenSigTimeoutTime_PCM" SG_ 2566749463 HazardWarn 5000;
BA_ "GenSigTimeoutTime_MPPxPTFE2" SG_ 2566749463 HazardWarn 5000;
BA_ "GenSigTimeoutTime_FMS_FMS5" SG_ 2566749463 HazardWarn 5000;
BA_ "GenSigTimeoutTime_FMS_FMS4" SG_ 2566749463 HazardWarn 5000;
BA_ "CI_SigName" SG_ 2566749463 HazardWarn "Hazard warning";
BA_ "CI_SigId" SG_ 2566749463 HazardWarn 3207;
BA_ "CI_ParId" SG_ 2566749463 HazardWarn "FMS005";
BA_ "GenSigTimeoutTime_SGW" SG_ 2566749463 MuxSys 5000;
BA_ "GenSigTimeoutTime_PCM" SG_ 2566749463 MuxSys 5000;
BA_ "GenSigTimeoutTime_MPPxPTFE2" SG_ 2566749463 MuxSys 5000;
BA_ "GenSigTimeoutTime_FMS_FMS5" SG_ 2566749463 MuxSys 5000;
BA_ "GenSigTimeoutTime_FMS_FMS4" SG_ 2566749463 MuxSys 5000;
BA_ "CI_SigName" SG_ 2566749463 MuxSys "Multiplex System";
BA_ "CI_SigId" SG_ 2566749463 MuxSys 14864;
BA_ "CI_ParId" SG_ 2566749463 MuxSys "FMS004";
BA_ "GenSigTimeoutTime_SGW" SG_ 2566749463 SeatBelt 5000;
BA_ "GenSigTimeoutTime_PCM" SG_ 2566749463 SeatBelt 5000;
BA_ "GenSigTimeoutTime_MPPxPTFE2" SG_ 2566749463 SeatBelt 5000;
BA_ "GenSigTimeoutTime_FMS_FMS5" SG_ 2566749463 SeatBelt 5000;
BA_ "GenSigTimeoutTime_FMS_FMS4" SG_ 2566749463 SeatBelt 5000;
BA_ "CI_SigName" SG_ 2566749463 SeatBelt "Seat belt";
BA_ "CI_SigId" SG_ 2566749463 SeatBelt 14849;
BA_ "CI_ParId" SG_ 2566749463 SeatBelt "FMS004";
BA_ "GenSigTimeoutTime_SGW" SG_ 2566749463 EngEmisSysFailMil 5000;
BA_ "GenSigTimeoutTime_PCM" SG_ 2566749463 EngEmisSysFailMil 5000;
BA_ "GenSigTimeoutTime_MPPxPTFE2" SG_ 2566749463 EngEmisSysFailMil 5000;
BA_ "GenSigTimeoutTime_FMS_FMS5" SG_ 2566749463 EngEmisSysFailMil 5000;
BA_ "GenSigTimeoutTime_FMS_FMS4" SG_ 2566749463 EngEmisSysFailMil 5000;
BA_ "CI_SigName" SG_ 2566749463 EngEmisSysFailMil "Engine Emission system failure -Mil indicator";
BA_ "CI_SigId" SG_ 2566749463 EngEmisSysFailMil 14834;
BA_ "CI_ParId" SG_ 2566749463 EngEmisSysFailMil "FMS004";
BA_ "GenSigTimeoutTime_SGW" SG_ 2566749463 ServCallForMaint 5000;
BA_ "GenSigTimeoutTime_PCM" SG_ 2566749463 ServCallForMaint 5000;
BA_ "GenSigTimeoutTime_MPPxPTFE2" SG_ 2566749463 ServCallForMaint 5000;
BA_ "GenSigTimeoutTime_FMS_FMS5" SG_ 2566749463 ServCallForMaint 5000;
BA_ "GenSigTimeoutTime_FMS_FMS4" SG_ 2566749463 ServCallForMaint 5000;
BA_ "CI_SigName" SG_ 2566749463 ServCallForMaint "Service, call for maintenance";
BA_ "CI_SigId" SG_ 2566749463 ServCallForMaint 14819;
BA_ "CI_ParId" SG_ 2566749463 ServCallForMaint "FMS004";
BA_ "GenSigTimeoutTime_SGW" SG_ 2566749463 TurnSigs 5000;
BA_ "GenSigTimeoutTime_PCM" SG_ 2566749463 TurnSigs 5000;
BA_ "GenSigTimeoutTime_MPPxPTFE2" SG_ 2566749463 TurnSigs 5000;
BA_ "GenSigTimeoutTime_FMS_FMS5" SG_ 2566749463 TurnSigs 5000;
BA_ "GenSigTimeoutTime_FMS_FMS4" SG_ 2566749463 TurnSigs 5000;
BA_ "CI_SigName" SG_ 2566749463 TurnSigs "Turn signals";
BA_ "CI_SigId" SG_ 2566749463 TurnSigs 3206;
BA_ "CI_ParId" SG_ 2566749463 TurnSigs "FMS004";
BA_ "GenSigTimeoutTime_SGW" SG_ 2566749463 AdblueTamp 5000;
BA_ "GenSigTimeoutTime_PCM" SG_ 2566749463 AdblueTamp 5000;
BA_ "GenSigTimeoutTime_MPPxPTFE2" SG_ 2566749463 AdblueTamp 5000;
BA_ "GenSigTimeoutTime_FMS_FMS5" SG_ 2566749463 AdblueTamp 5000;
BA_ "GenSigTimeoutTime_FMS_FMS4" SG_ 2566749463 AdblueTamp 5000;
BA_ "CI_SigName" SG_ 2566749463 AdblueTamp "AdBlue tampering";
BA_ "CI_SigId" SG_ 2566749463 AdblueTamp 14863;
BA_ "CI_ParId" SG_ 2566749463 AdblueTamp "FMS003";
BA_ "GenSigTimeoutTime_SGW" SG_ 2566749463 FuelFiltDiffPrs 5000;
BA_ "GenSigTimeoutTime_PCM" SG_ 2566749463 FuelFiltDiffPrs 5000;
BA_ "GenSigTimeoutTime_MPPxPTFE2" SG_ 2566749463 FuelFiltDiffPrs 5000;
BA_ "GenSigTimeoutTime_FMS_FMS5" SG_ 2566749463 FuelFiltDiffPrs 5000;
BA_ "GenSigTimeoutTime_FMS_FMS4" SG_ 2566749463 FuelFiltDiffPrs 5000;
BA_ "CI_SigName" SG_ 2566749463 FuelFiltDiffPrs "Fuel filter differential pressure";
BA_ "CI_SigId" SG_ 2566749463 FuelFiltDiffPrs 14848;
BA_ "CI_ParId" SG_ 2566749463 FuelFiltDiffPrs "FMS003";
BA_ "GenSigTimeoutTime_SGW" SG_ 2566749463 Ret 5000;
BA_ "GenSigTimeoutTime_PCM" SG_ 2566749463 Ret 5000;
BA_ "GenSigTimeoutTime_MPPxPTFE2" SG_ 2566749463 Ret 5000;
BA_ "GenSigTimeoutTime_FMS_FMS5" SG_ 2566749463 Ret 5000;
BA_ "GenSigTimeoutTime_FMS_FMS4" SG_ 2566749463 Ret 5000;
BA_ "CI_SigName" SG_ 2566749463 Ret "Retarder";
BA_ "CI_SigId" SG_ 2566749463 Ret 14833;
BA_ "CI_ParId" SG_ 2566749463 Ret "FMS003";
BA_ "GenSigTimeoutTime_SGW" SG_ 2566749463 Eng_Mil 5000;
BA_ "GenSigTimeoutTime_PCM" SG_ 2566749463 Eng_Mil 5000;
BA_ "GenSigTimeoutTime_MPPxPTFE2" SG_ 2566749463 Eng_Mil 5000;
BA_ "GenSigTimeoutTime_FMS_FMS5" SG_ 2566749463 Eng_Mil 5000;
BA_ "GenSigTimeoutTime_FMS_FMS4" SG_ 2566749463 Eng_Mil 5000;
BA_ "CI_SigName" SG_ 2566749463 Eng_Mil "Engine / Mil indicator";
BA_ "CI_SigId" SG_ 2566749463 Eng_Mil 14818;
BA_ "CI_ParId" SG_ 2566749463 Eng_Mil "FMS003";
BA_ "GenSigTimeoutTime_SGW" SG_ 2566749463 LowBeamDipBeam 5000;
BA_ "GenSigTimeoutTime_PCM" SG_ 2566749463 LowBeamDipBeam 5000;
BA_ "GenSigTimeoutTime_MPPxPTFE2" SG_ 2566749463 LowBeamDipBeam 5000;
BA_ "GenSigTimeoutTime_FMS_FMS5" SG_ 2566749463 LowBeamDipBeam 5000;
BA_ "GenSigTimeoutTime_FMS_FMS4" SG_ 2566749463 LowBeamDipBeam 5000;
BA_ "CI_SigName" SG_ 2566749463 LowBeamDipBeam "Low beam, dipped beam";
BA_ "CI_SigId" SG_ 2566749463 LowBeamDipBeam 3205;
BA_ "CI_ParId" SG_ 2566749463 LowBeamDipBeam "FMS003";
BA_ "GenSigTimeoutTime_SGW" SG_ 2566749463 ElMotFails 5000;
BA_ "GenSigTimeoutTime_PCM" SG_ 2566749463 ElMotFails 5000;
BA_ "GenSigTimeoutTime_MPPxPTFE2" SG_ 2566749463 ElMotFails 5000;
BA_ "GenSigTimeoutTime_FMS_FMS5" SG_ 2566749463 ElMotFails 5000;
BA_ "GenSigTimeoutTime_FMS_FMS4" SG_ 2566749463 ElMotFails 5000;
BA_ "CI_SigName" SG_ 2566749463 ElMotFails "Electric motor failures";
BA_ "CI_SigId" SG_ 2566749463 ElMotFails 14862;
BA_ "CI_ParId" SG_ 2566749463 ElMotFails "FMS002";
BA_ "GenSigTimeoutTime_SGW" SG_ 2566749463 AirFiltClog 5000;
BA_ "GenSigTimeoutTime_PCM" SG_ 2566749463 AirFiltClog 5000;
BA_ "GenSigTimeoutTime_MPPxPTFE2" SG_ 2566749463 AirFiltClog 5000;
BA_ "GenSigTimeoutTime_FMS_FMS5" SG_ 2566749463 AirFiltClog 5000;
BA_ "GenSigTimeoutTime_FMS_FMS4" SG_ 2566749463 AirFiltClog 5000;
BA_ "CI_SigName" SG_ 2566749463 AirFiltClog "Air filter clogged";
BA_ "CI_SigId" SG_ 2566749463 AirFiltClog 14847;
BA_ "CI_ParId" SG_ 2566749463 AirFiltClog "FMS002";
BA_ "GenSigTimeoutTime_SGW" SG_ 2566749463 HtCtrl 5000;
BA_ "GenSigTimeoutTime_PCM" SG_ 2566749463 HtCtrl 5000;
BA_ "GenSigTimeoutTime_MPPxPTFE2" SG_ 2566749463 HtCtrl 5000;
BA_ "GenSigTimeoutTime_FMS_FMS5" SG_ 2566749463 HtCtrl 5000;
BA_ "GenSigTimeoutTime_FMS_FMS4" SG_ 2566749463 HtCtrl 5000;
BA_ "CI_SigName" SG_ 2566749463 HtCtrl "Height Control (Levelling)";
BA_ "CI_SigId" SG_ 2566749463 HtCtrl 14832;
BA_ "CI_ParId" SG_ 2566749463 HtCtrl "FMS002";
BA_ "GenSigTimeoutTime_SGW" SG_ 2566749463 ParkHeat 5000;
BA_ "GenSigTimeoutTime_PCM" SG_ 2566749463 ParkHeat 5000;
BA_ "GenSigTimeoutTime_MPPxPTFE2" SG_ 2566749463 ParkHeat 5000;
BA_ "GenSigTimeoutTime_FMS_FMS5" SG_ 2566749463 ParkHeat 5000;
BA_ "GenSigTimeoutTime_FMS_FMS4" SG_ 2566749463 ParkHeat 5000;
BA_ "CI_SigName" SG_ 2566749463 ParkHeat "Park Heating";
BA_ "CI_SigId" SG_ 2566749463 ParkHeat 14817;
BA_ "CI_ParId" SG_ 2566749463 ParkHeat "FMS002";
BA_ "GenSigTimeoutTime_SGW" SG_ 2566749463 HighBeamMainBeam 5000;
BA_ "GenSigTimeoutTime_PCM" SG_ 2566749463 HighBeamMainBeam 5000;
BA_ "GenSigTimeoutTime_MPPxPTFE2" SG_ 2566749463 HighBeamMainBeam 5000;
BA_ "GenSigTimeoutTime_FMS_FMS5" SG_ 2566749463 HighBeamMainBeam 5000;
BA_ "GenSigTimeoutTime_FMS_FMS4" SG_ 2566749463 HighBeamMainBeam 5000;
BA_ "CI_SigName" SG_ 2566749463 HighBeamMainBeam "High beam, main beam";
BA_ "CI_SigId" SG_ 2566749463 HighBeamMainBeam 3204;
BA_ "CI_ParId" SG_ 2566749463 HighBeamMainBeam "FMS002";
BA_ "GenSigTimeoutTime_SGW" SG_ 2566749463 EngEmisFilt 5000;
BA_ "GenSigTimeoutTime_PCM" SG_ 2566749463 EngEmisFilt 5000;
BA_ "GenSigTimeoutTime_MPPxPTFE2" SG_ 2566749463 EngEmisFilt 5000;
BA_ "GenSigTimeoutTime_FMS_FMS5" SG_ 2566749463 EngEmisFilt 5000;
BA_ "GenSigTimeoutTime_FMS_FMS4" SG_ 2566749463 EngEmisFilt 5000;
BA_ "CI_SigName" SG_ 2566749463 EngEmisFilt "Engine emission filter (Soot Filter)";
BA_ "CI_SigId" SG_ 2566749463 EngEmisFilt 14861;
BA_ "CI_ParId" SG_ 2566749463 EngEmisFilt "FMS001";
BA_ "GenSigTimeoutTime_SGW" SG_ 2566749463 AuxAirPrs 5000;
BA_ "GenSigTimeoutTime_PCM" SG_ 2566749463 AuxAirPrs 5000;
BA_ "GenSigTimeoutTime_MPPxPTFE2" SG_ 2566749463 AuxAirPrs 5000;
BA_ "GenSigTimeoutTime_FMS_FMS5" SG_ 2566749463 AuxAirPrs 5000;
BA_ "GenSigTimeoutTime_FMS_FMS4" SG_ 2566749463 AuxAirPrs 5000;
BA_ "CI_SigName" SG_ 2566749463 AuxAirPrs "Auxiliary air pressure";
BA_ "CI_SigId" SG_ 2566749463 AuxAirPrs 14846;
BA_ "CI_ParId" SG_ 2566749463 AuxAirPrs "FMS001";
BA_ "GenSigTimeoutTime_SGW" SG_ 2566749463 SteerFail 5000;
BA_ "GenSigTimeoutTime_PCM" SG_ 2566749463 SteerFail 5000;
BA_ "GenSigTimeoutTime_MPPxPTFE2" SG_ 2566749463 SteerFail 5000;
BA_ "GenSigTimeoutTime_FMS_FMS5" SG_ 2566749463 SteerFail 5000;
BA_ "GenSigTimeoutTime_FMS_FMS4" SG_ 2566749463 SteerFail 5000;
BA_ "CI_SigName" SG_ 2566749463 SteerFail "Steering failure";
BA_ "CI_SigId" SG_ 2566749463 SteerFail 14831;
BA_ "CI_ParId" SG_ 2566749463 SteerFail "FMS001";
BA_ "GenSigTimeoutTime_SGW" SG_ 2566749463 RearFogLight 5000;
BA_ "GenSigTimeoutTime_PCM" SG_ 2566749463 RearFogLight 5000;
BA_ "GenSigTimeoutTime_MPPxPTFE2" SG_ 2566749463 RearFogLight 5000;
BA_ "GenSigTimeoutTime_FMS_FMS5" SG_ 2566749463 RearFogLight 5000;
BA_ "GenSigTimeoutTime_FMS_FMS4" SG_ 2566749463 RearFogLight 5000;
BA_ "CI_SigName" SG_ 2566749463 RearFogLight "Rear fog light";
BA_ "CI_SigId" SG_ 2566749463 RearFogLight 14816;
BA_ "CI_ParId" SG_ 2566749463 RearFogLight "FMS001";
BA_ "GenSigTimeoutTime_SGW" SG_ 2566749463 CoolAc 5000;
BA_ "GenSigTimeoutTime_PCM" SG_ 2566749463 CoolAc 5000;
BA_ "GenSigTimeoutTime_MPPxPTFE2" SG_ 2566749463 CoolAc 5000;
BA_ "GenSigTimeoutTime_FMS_FMS5" SG_ 2566749463 CoolAc 5000;
BA_ "GenSigTimeoutTime_FMS_FMS4" SG_ 2566749463 CoolAc 5000;
BA_ "CI_SigName" SG_ 2566749463 CoolAc "Cooling air conditioning";
BA_ "CI_SigId" SG_ 2566749463 CoolAc 3203;
BA_ "CI_ParId" SG_ 2566749463 CoolAc "FMS001";
BA_ "GenSigTimeoutTime_SGW" SG_ 2566749463 TtBlkId 5000;
BA_ "GenSigTimeoutTime_PCM" SG_ 2566749463 TtBlkId 5000;
BA_ "GenSigTimeoutTime_MPPxPTFE2" SG_ 2566749463 TtBlkId 5000;
BA_ "GenSigTimeoutTime_FMS_FMS5" SG_ 2566749463 TtBlkId 5000;
BA_ "GenSigTimeoutTime_FMS_FMS4" SG_ 2566749463 TtBlkId 5000;
BA_ "CI_SigName" SG_ 2566749463 TtBlkId "Telltale Block ID";
BA_ "CI_SigId" SG_ 2566749463 TtBlkId 3202;
BA_ "CI_ParId" SG_ 2566749463 TtBlkId "FMS000";
BA_ "GenSigTimeoutTime_SGW2" SG_ 2566884426 AllTheDataRemoval 5000;
BA_ "GenSigTimeoutTime_SGW" SG_ 2566884426 AllTheDataRemoval 5000;
BA_ "GenSigTimeoutTime_AI_CAID" SG_ 2566884426 AllTheDataRemoval 5000;
BA_ "CI_SigName" SG_ 2566884426 AllTheDataRemoval "All the data removal";
BA_ "CI_SigId" SG_ 2566884426 AllTheDataRemoval 1333;
BA_ "CI_ParId" SG_ 2566884426 AllTheDataRemoval "IB078";
BA_ "GenSigTimeoutTime_SGW2" SG_ 2566884426 SwIdReq 5000;
BA_ "GenSigTimeoutTime_SGW" SG_ 2566884426 SwIdReq 5000;
BA_ "GenSigTimeoutTime_AI_CAID" SG_ 2566884426 SwIdReq 5000;
BA_ "CI_SigName" SG_ 2566884426 SwIdReq "Software identification request";
BA_ "CI_SigId" SG_ 2566884426 SwIdReq 1332;
BA_ "CI_ParId" SG_ 2566884426 SwIdReq "IB077";
BA_ "GenSigTimeoutTime_SGW2" SG_ 2566884426 CompIdReq 5000;
BA_ "GenSigTimeoutTime_SGW" SG_ 2566884426 CompIdReq 5000;
BA_ "GenSigTimeoutTime_AI_CAID" SG_ 2566884426 CompIdReq 5000;
BA_ "CI_SigName" SG_ 2566884426 CompIdReq "Component identification request";
BA_ "CI_SigId" SG_ 2566884426 CompIdReq 1331;
BA_ "CI_ParId" SG_ 2566884426 CompIdReq "IB076";
BA_ "GenSigTimeoutTime_SGW2" SG_ 2566884426 EcuIdReq 5000;
BA_ "GenSigTimeoutTime_SGW" SG_ 2566884426 EcuIdReq 5000;
BA_ "GenSigTimeoutTime_AI_CAID" SG_ 2566884426 EcuIdReq 5000;
BA_ "CI_SigName" SG_ 2566884426 EcuIdReq "ECU identification request";
BA_ "CI_SigId" SG_ 2566884426 EcuIdReq 1330;
BA_ "CI_ParId" SG_ 2566884426 EcuIdReq "IB075";
BA_ "GenSigTimeoutTime_SGW2" SG_ 2566884426 DeferredDataReq 5000;
BA_ "GenSigTimeoutTime_SGW" SG_ 2566884426 DeferredDataReq 5000;
BA_ "GenSigTimeoutTime_AI_CAID" SG_ 2566884426 DeferredDataReq 5000;
BA_ "CI_SigName" SG_ 2566884426 DeferredDataReq "Deferred data request";
BA_ "CI_SigId" SG_ 2566884426 DeferredDataReq 1329;
BA_ "CI_ParId" SG_ 2566884426 DeferredDataReq "IB074";
BA_ "SigType" SG_ 2566877568 FCU2_8_FC_Consump 1;
BA_ "GenSigTimeoutTime_SGW" SG_ 2566877568 FCU2_8_FC_Consump 500;
BA_ "GenSigTimeoutTime_PCM" SG_ 2566877568 FCU2_8_FC_Consump 500;
BA_ "GenSigTimeoutTime_IC_MulticII" SG_ 2566877568 FCU2_8_FC_Consump 500;
BA_ "CI_SigName" SG_ 2566877568 FCU2_8_FC_Consump "FCU2_8_FuelcellConsumption";
BA_ "CI_SigId" SG_ 2566877568 FCU2_8_FC_Consump 18935;
BA_ "CI_ParId" SG_ 2566877568 FCU2_8_FC_Consump "IB4031";
BA_ "GenSigTimeoutTime_SGW" SG_ 2566877568 FillAuthorizDueToSafetyReas 500;
BA_ "GenSigTimeoutTime_PCM" SG_ 2566877568 FillAuthorizDueToSafetyReas 500;
BA_ "GenSigTimeoutTime_IC_MulticII" SG_ 2566877568 FillAuthorizDueToSafetyReas 500;
BA_ "CI_SigName" SG_ 2566877568 FillAuthorizDueToSafetyReas "Filling authorization due to safety reasons";
BA_ "CI_SigId" SG_ 2566877568 FillAuthorizDueToSafetyReas 18934;
BA_ "CI_ParId" SG_ 2566877568 FillAuthorizDueToSafetyReas "IB4030";
BA_ "GenSigTimeoutTime_SGW" SG_ 2566877568 NrTanksOpenH2_RdyToProvide2FC 500;
BA_ "GenSigTimeoutTime_PCM" SG_ 2566877568 NrTanksOpenH2_RdyToProvide2FC 500;
BA_ "GenSigTimeoutTime_IC_MulticII" SG_ 2566877568 NrTanksOpenH2_RdyToProvide2FC 500;
BA_ "CI_SigName" SG_ 2566877568 NrTanksOpenH2_RdyToProvide2FC "Number of tanks open for H2 (Ready to provide H2 to the FC)";
BA_ "CI_SigId" SG_ 2566877568 NrTanksOpenH2_RdyToProvide2FC 18933;
BA_ "CI_ParId" SG_ 2566877568 NrTanksOpenH2_RdyToProvide2FC "IB4029";
BA_ "GenSigTimeoutTime_SGW" SG_ 2566877568 FC_Mode_ReqBySupervisor 500;
BA_ "GenSigTimeoutTime_PCM" SG_ 2566877568 FC_Mode_ReqBySupervisor 500;
BA_ "GenSigTimeoutTime_IC_MulticII" SG_ 2566877568 FC_Mode_ReqBySupervisor 500;
BA_ "CI_SigName" SG_ 2566877568 FC_Mode_ReqBySupervisor "FC Mode request (by the Supervisor)";
BA_ "CI_SigId" SG_ 2566877568 FC_Mode_ReqBySupervisor 18932;
BA_ "CI_ParId" SG_ 2566877568 FC_Mode_ReqBySupervisor "IB4028";
BA_ "GenSigTimeoutTime_SGW" SG_ 2566877568 HV_DC_Link_Sts 500;
BA_ "GenSigTimeoutTime_PCM" SG_ 2566877568 HV_DC_Link_Sts 500;
BA_ "GenSigTimeoutTime_IC_MulticII" SG_ 2566877568 HV_DC_Link_Sts 500;
BA_ "CI_SigName" SG_ 2566877568 HV_DC_Link_Sts "HV DC Link Status";
BA_ "CI_SigId" SG_ 2566877568 HV_DC_Link_Sts 18931;
BA_ "CI_ParId" SG_ 2566877568 HV_DC_Link_Sts "IB4027";
BA_ "GenSigTimeoutTime_SGW" SG_ 2566877568 LimpHomeMode 500;
BA_ "GenSigTimeoutTime_PCM" SG_ 2566877568 LimpHomeMode 500;
BA_ "GenSigTimeoutTime_IC_MulticII" SG_ 2566877568 LimpHomeMode 500;
BA_ "CI_SigName" SG_ 2566877568 LimpHomeMode "Limp home mode";
BA_ "CI_SigId" SG_ 2566877568 LimpHomeMode 18928;
BA_ "CI_ParId" SG_ 2566877568 LimpHomeMode "IB4024";
BA_ "GenSigTimeoutTime_SGW" SG_ 2566877568 H2_Circuit_Sts 500;
BA_ "GenSigTimeoutTime_PCM" SG_ 2566877568 H2_Circuit_Sts 500;
BA_ "GenSigTimeoutTime_IC_MulticII" SG_ 2566877568 H2_Circuit_Sts 500;
BA_ "CI_SigName" SG_ 2566877568 H2_Circuit_Sts "H2 Circuit status";
BA_ "CI_SigId" SG_ 2566877568 H2_Circuit_Sts 18927;
BA_ "CI_ParId" SG_ 2566877568 H2_Circuit_Sts "IB4023";
BA_ "GenSigTimeoutTime_SGW" SG_ 2566877568 FC_Sts_SupervisorSide 500;
BA_ "GenSigTimeoutTime_PCM" SG_ 2566877568 FC_Sts_SupervisorSide 500;
BA_ "GenSigTimeoutTime_IC_MulticII" SG_ 2566877568 FC_Sts_SupervisorSide 500;
BA_ "CI_SigName" SG_ 2566877568 FC_Sts_SupervisorSide "Fuel Cell status (from Supervisor side)";
BA_ "CI_SigId" SG_ 2566877568 FC_Sts_SupervisorSide 18926;
BA_ "CI_ParId" SG_ 2566877568 FC_Sts_SupervisorSide "IB4022";
BA_ "GenSigTimeoutTime_SGW" SG_ 2566877568 H2_Sensor4LeakageSts 500;
BA_ "GenSigTimeoutTime_PCM" SG_ 2566877568 H2_Sensor4LeakageSts 500;
BA_ "GenSigTimeoutTime_IC_MulticII" SG_ 2566877568 H2_Sensor4LeakageSts 500;
BA_ "CI_SigName" SG_ 2566877568 H2_Sensor4LeakageSts "H2 sensor 4 leakage status";
BA_ "CI_SigId" SG_ 2566877568 H2_Sensor4LeakageSts 18925;
BA_ "CI_ParId" SG_ 2566877568 H2_Sensor4LeakageSts "IB4021";
BA_ "GenSigTimeoutTime_SGW" SG_ 2566877568 H2_Sensor3LeakageSts 500;
BA_ "GenSigTimeoutTime_PCM" SG_ 2566877568 H2_Sensor3LeakageSts 500;
BA_ "GenSigTimeoutTime_IC_MulticII" SG_ 2566877568 H2_Sensor3LeakageSts 500;
BA_ "CI_SigName" SG_ 2566877568 H2_Sensor3LeakageSts "H2 sensor 3 leakage status";
BA_ "CI_SigId" SG_ 2566877568 H2_Sensor3LeakageSts 18924;
BA_ "CI_ParId" SG_ 2566877568 H2_Sensor3LeakageSts "IB4020";
BA_ "GenSigTimeoutTime_SGW" SG_ 2566877568 H2_Sensor2LeakageSts 500;
BA_ "GenSigTimeoutTime_PCM" SG_ 2566877568 H2_Sensor2LeakageSts 500;
BA_ "GenSigTimeoutTime_IC_MulticII" SG_ 2566877568 H2_Sensor2LeakageSts 500;
BA_ "CI_SigName" SG_ 2566877568 H2_Sensor2LeakageSts "H2 sensor 2 leakage status";
BA_ "CI_SigId" SG_ 2566877568 H2_Sensor2LeakageSts 18923;
BA_ "CI_ParId" SG_ 2566877568 H2_Sensor2LeakageSts "IB4019";
BA_ "GenSigTimeoutTime_SGW" SG_ 2566877568 H2_Sensor1LeakageSts 500;
BA_ "GenSigTimeoutTime_PCM" SG_ 2566877568 H2_Sensor1LeakageSts 500;
BA_ "GenSigTimeoutTime_IC_MulticII" SG_ 2566877568 H2_Sensor1LeakageSts 500;
BA_ "CI_SigName" SG_ 2566877568 H2_Sensor1LeakageSts "H2 sensor 1 leakage status";
BA_ "CI_SigId" SG_ 2566877568 H2_Sensor1LeakageSts 18922;
BA_ "CI_ParId" SG_ 2566877568 H2_Sensor1LeakageSts "IB4018";
BA_ "GenSigTimeoutTime_SGW" SG_ 2566877568 H2ConctValExc4Pc_RslR134 500;
BA_ "GenSigTimeoutTime_PCM" SG_ 2566877568 H2ConctValExc4Pc_RslR134 500;
BA_ "GenSigTimeoutTime_IC_MulticII" SG_ 2566877568 H2ConctValExc4Pc_RslR134 500;
BA_ "CI_SigName" SG_ 2566877568 H2ConctValExc4Pc_RslR134 "H2 concentration value exceeding 4%";
BA_ "CI_SigId" SG_ 2566877568 H2ConctValExc4Pc_RslR134 18921;
BA_ "CI_ParId" SG_ 2566877568 H2ConctValExc4Pc_RslR134 "IB4017";
BA_ "GenSigTimeoutTime_SGW" SG_ 2566877568 H2ConctValExc3Pc_AwlR134 500;
BA_ "GenSigTimeoutTime_PCM" SG_ 2566877568 H2ConctValExc3Pc_AwlR134 500;
BA_ "GenSigTimeoutTime_IC_MulticII" SG_ 2566877568 H2ConctValExc3Pc_AwlR134 500;
BA_ "CI_SigName" SG_ 2566877568 H2ConctValExc3Pc_AwlR134 "H2 concentration value exceeding 3%";
BA_ "CI_SigId" SG_ 2566877568 H2ConctValExc3Pc_AwlR134 18920;
BA_ "CI_ParId" SG_ 2566877568 H2ConctValExc3Pc_AwlR134 "IB4016";
BA_ "SigType" SG_ 2566877568 FC_Act_DeacStsDashbDisplay 4;
BA_ "GenSigTimeoutTime_SGW" SG_ 2566877568 FC_Act_DeacStsDashbDisplay 500;
BA_ "GenSigTimeoutTime_PCM" SG_ 2566877568 FC_Act_DeacStsDashbDisplay 500;
BA_ "GenSigTimeoutTime_IC_MulticII" SG_ 2566877568 FC_Act_DeacStsDashbDisplay 500;
BA_ "CI_SigName" SG_ 2566877568 FC_Act_DeacStsDashbDisplay "FC activation / deactivation status for dashboard displaying";
BA_ "CI_SigId" SG_ 2566877568 FC_Act_DeacStsDashbDisplay 18919;
BA_ "CI_ParId" SG_ 2566877568 FC_Act_DeacStsDashbDisplay "IB4015";
BA_ "GenSigTimeoutTime_SGW" SG_ 2566877568 VCU_TkClosEmrgShtDwnRq_FC1 500;
BA_ "GenSigTimeoutTime_PCM" SG_ 2566877568 VCU_TkClosEmrgShtDwnRq_FC1 500;
BA_ "GenSigTimeoutTime_IC_MulticII" SG_ 2566877568 VCU_TkClosEmrgShtDwnRq_FC1 500;
BA_ "CI_SigName" SG_ 2566877568 VCU_TkClosEmrgShtDwnRq_FC1 "VCU_TankCloseEmergencyShutdownRequest_Fuelcell1";
BA_ "CI_SigId" SG_ 2566877568 VCU_TkClosEmrgShtDwnRq_FC1 18918;
BA_ "CI_ParId" SG_ 2566877568 VCU_TkClosEmrgShtDwnRq_FC1 "IB4014";
BA_ "GenSigTimeoutTime_SGW" SG_ 2566877568 VCU_HV_FtEmrgShtDwnRq_FC1 500;
BA_ "GenSigTimeoutTime_PCM" SG_ 2566877568 VCU_HV_FtEmrgShtDwnRq_FC1 500;
BA_ "GenSigTimeoutTime_IC_MulticII" SG_ 2566877568 VCU_HV_FtEmrgShtDwnRq_FC1 500;
BA_ "CI_SigName" SG_ 2566877568 VCU_HV_FtEmrgShtDwnRq_FC1 "VCU_HighvoltageFaultEmergencyShutdownRequest_Fuelcell1";
BA_ "CI_SigId" SG_ 2566877568 VCU_HV_FtEmrgShtDwnRq_FC1 18917;
BA_ "CI_ParId" SG_ 2566877568 VCU_HV_FtEmrgShtDwnRq_FC1 "IB4013";
BA_ "SigType" SG_ 2566877568 FCU2_7_FC_StopState 4;
BA_ "GenSigTimeoutTime_SGW" SG_ 2566877568 FCU2_7_FC_StopState 500;
BA_ "GenSigTimeoutTime_PCM" SG_ 2566877568 FCU2_7_FC_StopState 500;
BA_ "GenSigTimeoutTime_IC_MulticII" SG_ 2566877568 FCU2_7_FC_StopState 500;
BA_ "CI_SigName" SG_ 2566877568 FCU2_7_FC_StopState "FCU2_7_FuelcellStopState";
BA_ "CI_SigId" SG_ 2566877568 FCU2_7_FC_StopState 18916;
BA_ "CI_ParId" SG_ 2566877568 FCU2_7_FC_StopState "IB4012";
BA_ "SigType" SG_ 2566877568 FCU2_7_FC_StopImposs 4;
BA_ "GenSigTimeoutTime_SGW" SG_ 2566877568 FCU2_7_FC_StopImposs 500;
BA_ "GenSigTimeoutTime_PCM" SG_ 2566877568 FCU2_7_FC_StopImposs 500;
BA_ "GenSigTimeoutTime_IC_MulticII" SG_ 2566877568 FCU2_7_FC_StopImposs 500;
BA_ "CI_SigName" SG_ 2566877568 FCU2_7_FC_StopImposs "FCU2_7_FuelcellStopImpossible";
BA_ "CI_SigId" SG_ 2566877568 FCU2_7_FC_StopImposs 18915;
BA_ "CI_ParId" SG_ 2566877568 FCU2_7_FC_StopImposs "IB4011";
BA_ "GenSigTimeoutTime_SGW" SG_ 2566877568 FCU2_5_FC_Fault 500;
BA_ "GenSigTimeoutTime_PCM" SG_ 2566877568 FCU2_5_FC_Fault 500;
BA_ "GenSigTimeoutTime_IC_MulticII" SG_ 2566877568 FCU2_5_FC_Fault 500;
BA_ "CI_SigName" SG_ 2566877568 FCU2_5_FC_Fault "FCU2_5_FuelcellFault";
BA_ "CI_SigId" SG_ 2566877568 FCU2_5_FC_Fault 18914;
BA_ "CI_ParId" SG_ 2566877568 FCU2_5_FC_Fault "IB4010";
BA_ "SigType" SG_ 2566877568 FCU2_5_FC_Shutdown 4;
BA_ "GenSigTimeoutTime_SGW" SG_ 2566877568 FCU2_5_FC_Shutdown 500;
BA_ "GenSigTimeoutTime_PCM" SG_ 2566877568 FCU2_5_FC_Shutdown 500;
BA_ "GenSigTimeoutTime_IC_MulticII" SG_ 2566877568 FCU2_5_FC_Shutdown 500;
BA_ "CI_SigName" SG_ 2566877568 FCU2_5_FC_Shutdown "FCU2_5_FuelcellShutdown";
BA_ "CI_SigId" SG_ 2566877568 FCU2_5_FC_Shutdown 18913;
BA_ "CI_ParId" SG_ 2566877568 FCU2_5_FC_Shutdown "IB4009";
BA_ "GenSigTimeoutTime_SGW" SG_ 2566877568 FCU2_5_FC_LoadPermmit 500;
BA_ "GenSigTimeoutTime_PCM" SG_ 2566877568 FCU2_5_FC_LoadPermmit 500;
BA_ "GenSigTimeoutTime_IC_MulticII" SG_ 2566877568 FCU2_5_FC_LoadPermmit 500;
BA_ "CI_SigName" SG_ 2566877568 FCU2_5_FC_LoadPermmit "FCU2_5_FuelcellLoadPermmit";
BA_ "CI_SigId" SG_ 2566877568 FCU2_5_FC_LoadPermmit 18912;
BA_ "CI_ParId" SG_ 2566877568 FCU2_5_FC_LoadPermmit "IB4008";
BA_ "SigType" SG_ 2566877568 FCU2_5_FC_Startup 4;
BA_ "GenSigTimeoutTime_SGW" SG_ 2566877568 FCU2_5_FC_Startup 500;
BA_ "GenSigTimeoutTime_PCM" SG_ 2566877568 FCU2_5_FC_Startup 500;
BA_ "GenSigTimeoutTime_IC_MulticII" SG_ 2566877568 FCU2_5_FC_Startup 500;
BA_ "CI_SigName" SG_ 2566877568 FCU2_5_FC_Startup "FCU2_5_FuelcellStartup";
BA_ "CI_SigId" SG_ 2566877568 FCU2_5_FC_Startup 18911;
BA_ "CI_ParId" SG_ 2566877568 FCU2_5_FC_Startup "IB4007";
BA_ "GenSigTimeoutTime_SGW" SG_ 2566877568 VCU_FC_CoolantLevLow 500;
BA_ "GenSigTimeoutTime_PCM" SG_ 2566877568 VCU_FC_CoolantLevLow 500;
BA_ "GenSigTimeoutTime_IC_MulticII" SG_ 2566877568 VCU_FC_CoolantLevLow 500;
BA_ "CI_SigName" SG_ 2566877568 VCU_FC_CoolantLevLow "VCU_FuelcellCoolantLevelLow";
BA_ "CI_SigId" SG_ 2566877568 VCU_FC_CoolantLevLow 18910;
BA_ "CI_ParId" SG_ 2566877568 VCU_FC_CoolantLevLow "IB4006";
BA_ "GenSigTimeoutTime_SGW" SG_ 2566877568 FuelCellSwON_OFF 500;
BA_ "GenSigTimeoutTime_PCM" SG_ 2566877568 FuelCellSwON_OFF 500;
BA_ "GenSigTimeoutTime_IC_MulticII" SG_ 2566877568 FuelCellSwON_OFF 500;
BA_ "CI_SigName" SG_ 2566877568 FuelCellSwON_OFF "Fuel Cell Switch ON/OFF (input VCU)";
BA_ "CI_SigId" SG_ 2566877568 FuelCellSwON_OFF 18909;
BA_ "CI_ParId" SG_ 2566877568 FuelCellSwON_OFF "IB4005";
BA_ "GenSigTimeoutTime_SGW" SG_ 2566877568 FCU2_H2TankValveEmrgClos 500;
BA_ "GenSigTimeoutTime_PCM" SG_ 2566877568 FCU2_H2TankValveEmrgClos 500;
BA_ "GenSigTimeoutTime_IC_MulticII" SG_ 2566877568 FCU2_H2TankValveEmrgClos 500;
BA_ "CI_SigName" SG_ 2566877568 FCU2_H2TankValveEmrgClos "FCU2_H2TankValveEmergencyClose";
BA_ "CI_SigId" SG_ 2566877568 FCU2_H2TankValveEmrgClos 18908;
BA_ "CI_ParId" SG_ 2566877568 FCU2_H2TankValveEmrgClos "IB4004";
BA_ "GenSigTimeoutTime_SGW" SG_ 2566877568 FCU2_HV_InterlockReactRq 500;
BA_ "GenSigTimeoutTime_PCM" SG_ 2566877568 FCU2_HV_InterlockReactRq 500;
BA_ "GenSigTimeoutTime_IC_MulticII" SG_ 2566877568 FCU2_HV_InterlockReactRq 500;
BA_ "CI_SigName" SG_ 2566877568 FCU2_HV_InterlockReactRq "FCU2_HighvoltageInterlockReactRequest";
BA_ "CI_SigId" SG_ 2566877568 FCU2_HV_InterlockReactRq 18907;
BA_ "CI_ParId" SG_ 2566877568 FCU2_HV_InterlockReactRq "IB4003";
BA_ "GenSigTimeoutTime_SGW" SG_ 2566877568 FCU2_5_H2FaultLamp 500;
BA_ "GenSigTimeoutTime_PCM" SG_ 2566877568 FCU2_5_H2FaultLamp 500;
BA_ "GenSigTimeoutTime_IC_MulticII" SG_ 2566877568 FCU2_5_H2FaultLamp 500;
BA_ "CI_SigName" SG_ 2566877568 FCU2_5_H2FaultLamp "FCU2_5_H2FaultLamp";
BA_ "CI_SigId" SG_ 2566877568 FCU2_5_H2FaultLamp 18906;
BA_ "CI_ParId" SG_ 2566877568 FCU2_5_H2FaultLamp "IB4002";
BA_ "SigType" SG_ 2566877568 FCU2_8_H2LeakLamp 4;
BA_ "GenSigTimeoutTime_SGW" SG_ 2566877568 FCU2_8_H2LeakLamp 500;
BA_ "GenSigTimeoutTime_PCM" SG_ 2566877568 FCU2_8_H2LeakLamp 500;
BA_ "GenSigTimeoutTime_IC_MulticII" SG_ 2566877568 FCU2_8_H2LeakLamp 500;
BA_ "CI_SigName" SG_ 2566877568 FCU2_8_H2LeakLamp "FCU2_8_H2LeakLamp";
BA_ "CI_SigId" SG_ 2566877568 FCU2_8_H2LeakLamp 18905;
BA_ "CI_ParId" SG_ 2566877568 FCU2_8_H2LeakLamp "IB4001";
BA_ "SigType" SG_ 2566877824 Autonomy_H2 1;
BA_ "GenSigTimeoutTime_SGW" SG_ 2566877824 Autonomy_H2 5000;
BA_ "GenSigTimeoutTime_PCM" SG_ 2566877824 Autonomy_H2 5000;
BA_ "GenSigTimeoutTime_IC_MulticII" SG_ 2566877824 Autonomy_H2 5000;
BA_ "CI_SigName" SG_ 2566877824 Autonomy_H2 "Autonomy H2";
BA_ "CI_SigId" SG_ 2566877824 Autonomy_H2 18942;
BA_ "CI_ParId" SG_ 2566877824 Autonomy_H2 "IB4037";
BA_ "SigType" SG_ 2566877824 FC_Hours_of_running 1;
BA_ "GenSigTimeoutTime_SGW" SG_ 2566877824 FC_Hours_of_running 5000;
BA_ "GenSigTimeoutTime_PCM" SG_ 2566877824 FC_Hours_of_running 5000;
BA_ "GenSigTimeoutTime_IC_MulticII" SG_ 2566877824 FC_Hours_of_running 5000;
BA_ "CI_SigName" SG_ 2566877824 FC_Hours_of_running "Fuel Cell Hours of running";
BA_ "CI_SigId" SG_ 2566877824 FC_Hours_of_running 18941;
BA_ "CI_ParId" SG_ 2566877824 FC_Hours_of_running "IB4036";
BA_ "SigType" SG_ 2566877824 FCU2_4_FC_NetPower 1;
BA_ "GenSigTimeoutTime_SGW" SG_ 2566877824 FCU2_4_FC_NetPower 5000;
BA_ "GenSigTimeoutTime_PCM" SG_ 2566877824 FCU2_4_FC_NetPower 5000;
BA_ "GenSigTimeoutTime_IC_MulticII" SG_ 2566877824 FCU2_4_FC_NetPower 5000;
BA_ "CI_SigName" SG_ 2566877824 FCU2_4_FC_NetPower "FCU2_4_FuelcellNetPower";
BA_ "CI_SigId" SG_ 2566877824 FCU2_4_FC_NetPower 18940;
BA_ "CI_ParId" SG_ 2566877824 FCU2_4_FC_NetPower "IB4035";
BA_ "SigType" SG_ 2566877824 SOC_H2 1;
BA_ "GenSigTimeoutTime_SGW" SG_ 2566877824 SOC_H2 5000;
BA_ "GenSigTimeoutTime_PCM" SG_ 2566877824 SOC_H2 5000;
BA_ "GenSigTimeoutTime_IC_MulticII" SG_ 2566877824 SOC_H2 5000;
BA_ "CI_SigName" SG_ 2566877824 SOC_H2 "SOC H2";
BA_ "CI_SigId" SG_ 2566877824 SOC_H2 18939;
BA_ "CI_ParId" SG_ 2566877824 SOC_H2 "IB4034";
BA_ "SigType" SG_ 2566877824 FDC1_2_FDC1_CoolTemp 1;
BA_ "GenSigTimeoutTime_SGW" SG_ 2566877824 FDC1_2_FDC1_CoolTemp 5000;
BA_ "GenSigTimeoutTime_PCM" SG_ 2566877824 FDC1_2_FDC1_CoolTemp 5000;
BA_ "GenSigTimeoutTime_IC_MulticII" SG_ 2566877824 FDC1_2_FDC1_CoolTemp 5000;
BA_ "GenSigStartValue" SG_ 2566877824 FDC1_2_FDC1_CoolTemp 40;
BA_ "CI_SigName" SG_ 2566877824 FDC1_2_FDC1_CoolTemp "FDC1_2_FDC1 Coolant Temperature";
BA_ "CI_SigId" SG_ 2566877824 FDC1_2_FDC1_CoolTemp 18938;
BA_ "CI_ParId" SG_ 2566877824 FDC1_2_FDC1_CoolTemp "IB4033";
BA_ "SigType" SG_ 2566877824 FC_CoolantTempGaugeSgn 1;
BA_ "GenSigTimeoutTime_SGW" SG_ 2566877824 FC_CoolantTempGaugeSgn 5000;
BA_ "GenSigTimeoutTime_PCM" SG_ 2566877824 FC_CoolantTempGaugeSgn 5000;
BA_ "GenSigTimeoutTime_IC_MulticII" SG_ 2566877824 FC_CoolantTempGaugeSgn 5000;
BA_ "GenSigStartValue" SG_ 2566877824 FC_CoolantTempGaugeSgn 60;
BA_ "CI_SigName" SG_ 2566877824 FC_CoolantTempGaugeSgn "FC Coolant temperature gauge signal";
BA_ "CI_SigId" SG_ 2566877824 FC_CoolantTempGaugeSgn 18937;
BA_ "CI_ParId" SG_ 2566877824 FC_CoolantTempGaugeSgn "IB4032";
BA_ "SigType" SG_ 2566878080 VCU_H2PressTank4 1;
BA_ "GenSigTimeoutTime_SGW" SG_ 2566878080 VCU_H2PressTank4 5000;
BA_ "GenSigTimeoutTime_PCM" SG_ 2566878080 VCU_H2PressTank4 5000;
BA_ "GenSigTimeoutTime_IC_MulticII" SG_ 2566878080 VCU_H2PressTank4 5000;
BA_ "CI_SigName" SG_ 2566878080 VCU_H2PressTank4 "VCU_H2PressureTank4";
BA_ "CI_SigId" SG_ 2566878080 VCU_H2PressTank4 18956;
BA_ "CI_ParId" SG_ 2566878080 VCU_H2PressTank4 "IB4050";
BA_ "SigType" SG_ 2566878080 VCU_H2PressTank3 1;
BA_ "GenSigTimeoutTime_SGW" SG_ 2566878080 VCU_H2PressTank3 5000;
BA_ "GenSigTimeoutTime_PCM" SG_ 2566878080 VCU_H2PressTank3 5000;
BA_ "GenSigTimeoutTime_IC_MulticII" SG_ 2566878080 VCU_H2PressTank3 5000;
BA_ "CI_SigName" SG_ 2566878080 VCU_H2PressTank3 "VCU_H2PressureTank3";
BA_ "CI_SigId" SG_ 2566878080 VCU_H2PressTank3 18955;
BA_ "CI_ParId" SG_ 2566878080 VCU_H2PressTank3 "IB4049";
BA_ "SigType" SG_ 2566878080 VCU_H2PressTank2 1;
BA_ "GenSigTimeoutTime_SGW" SG_ 2566878080 VCU_H2PressTank2 5000;
BA_ "GenSigTimeoutTime_PCM" SG_ 2566878080 VCU_H2PressTank2 5000;
BA_ "GenSigTimeoutTime_IC_MulticII" SG_ 2566878080 VCU_H2PressTank2 5000;
BA_ "CI_SigName" SG_ 2566878080 VCU_H2PressTank2 "VCU_H2PressureTank2";
BA_ "CI_SigId" SG_ 2566878080 VCU_H2PressTank2 18954;
BA_ "CI_ParId" SG_ 2566878080 VCU_H2PressTank2 "IB4048";
BA_ "SigType" SG_ 2566878080 VCU_H2PressTank1 1;
BA_ "GenSigTimeoutTime_SGW" SG_ 2566878080 VCU_H2PressTank1 5000;
BA_ "GenSigTimeoutTime_PCM" SG_ 2566878080 VCU_H2PressTank1 5000;
BA_ "GenSigTimeoutTime_IC_MulticII" SG_ 2566878080 VCU_H2PressTank1 5000;
BA_ "CI_SigName" SG_ 2566878080 VCU_H2PressTank1 "VCU_H2PressureTank1";
BA_ "CI_SigId" SG_ 2566878080 VCU_H2PressTank1 18953;
BA_ "CI_ParId" SG_ 2566878080 VCU_H2PressTank1 "IB4047";
BA_ "SigType" SG_ 2566878080 VCU_H2MidPress 1;
BA_ "GenSigTimeoutTime_SGW" SG_ 2566878080 VCU_H2MidPress 5000;
BA_ "GenSigTimeoutTime_PCM" SG_ 2566878080 VCU_H2MidPress 5000;
BA_ "GenSigTimeoutTime_IC_MulticII" SG_ 2566878080 VCU_H2MidPress 5000;
BA_ "CI_SigName" SG_ 2566878080 VCU_H2MidPress "VCU_H2MidPressure";
BA_ "CI_SigId" SG_ 2566878080 VCU_H2MidPress 18952;
BA_ "CI_ParId" SG_ 2566878080 VCU_H2MidPress "IB4046";
BA_ "SigType" SG_ 2566878080 VCU_H2LowPress 1;
BA_ "GenSigTimeoutTime_SGW" SG_ 2566878080 VCU_H2LowPress 5000;
BA_ "GenSigTimeoutTime_PCM" SG_ 2566878080 VCU_H2LowPress 5000;
BA_ "GenSigTimeoutTime_IC_MulticII" SG_ 2566878080 VCU_H2LowPress 5000;
BA_ "CI_SigName" SG_ 2566878080 VCU_H2LowPress "VCU_H2LowPressure";
BA_ "CI_SigId" SG_ 2566878080 VCU_H2LowPress 18951;
BA_ "CI_ParId" SG_ 2566878080 VCU_H2LowPress "IB4045";
BA_ "SigType" SG_ 2566878080 LeakTestsStsAtShtDwn 4;
BA_ "GenSigTimeoutTime_SGW" SG_ 2566878080 LeakTestsStsAtShtDwn 5000;
BA_ "GenSigTimeoutTime_PCM" SG_ 2566878080 LeakTestsStsAtShtDwn 5000;
BA_ "GenSigTimeoutTime_IC_MulticII" SG_ 2566878080 LeakTestsStsAtShtDwn 5000;
BA_ "CI_SigName" SG_ 2566878080 LeakTestsStsAtShtDwn "Leakage tests Status at Shutdown";
BA_ "CI_SigId" SG_ 2566878080 LeakTestsStsAtShtDwn 18950;
BA_ "CI_ParId" SG_ 2566878080 LeakTestsStsAtShtDwn "IB4044";
BA_ "GenSigTimeoutTime_SGW" SG_ 2566878080 LeakTestsStsAtStartUp 5000;
BA_ "GenSigTimeoutTime_PCM" SG_ 2566878080 LeakTestsStsAtStartUp 5000;
BA_ "GenSigTimeoutTime_IC_MulticII" SG_ 2566878080 LeakTestsStsAtStartUp 5000;
BA_ "CI_SigName" SG_ 2566878080 LeakTestsStsAtStartUp "Leakage tests Status at start up";
BA_ "CI_SigId" SG_ 2566878080 LeakTestsStsAtStartUp 18949;
BA_ "CI_ParId" SG_ 2566878080 LeakTestsStsAtStartUp "IB4043";
BA_ "GenSigTimeoutTime_SGW" SG_ 2566878080 Sts_H2_Lines 5000;
BA_ "GenSigTimeoutTime_PCM" SG_ 2566878080 Sts_H2_Lines 5000;
BA_ "GenSigTimeoutTime_IC_MulticII" SG_ 2566878080 Sts_H2_Lines 5000;
BA_ "CI_SigName" SG_ 2566878080 Sts_H2_Lines "Status H2 Lines";
BA_ "CI_SigId" SG_ 2566878080 Sts_H2_Lines 18948;
BA_ "CI_ParId" SG_ 2566878080 Sts_H2_Lines "IB4042";
BA_ "GenSigTimeoutTime_SGW" SG_ 2566878080 Sts_ShutOff_Valve 5000;
BA_ "GenSigTimeoutTime_PCM" SG_ 2566878080 Sts_ShutOff_Valve 5000;
BA_ "GenSigTimeoutTime_IC_MulticII" SG_ 2566878080 Sts_ShutOff_Valve 5000;
BA_ "CI_SigName" SG_ 2566878080 Sts_ShutOff_Valve "Status ShutOff Valve";
BA_ "CI_SigId" SG_ 2566878080 Sts_ShutOff_Valve 18947;
BA_ "CI_ParId" SG_ 2566878080 Sts_ShutOff_Valve "IB4041";
BA_ "GenSigTimeoutTime_SGW" SG_ 2566878080 Sts_HP_LP_PressSensors 5000;
BA_ "GenSigTimeoutTime_PCM" SG_ 2566878080 Sts_HP_LP_PressSensors 5000;
BA_ "GenSigTimeoutTime_IC_MulticII" SG_ 2566878080 Sts_HP_LP_PressSensors 5000;
BA_ "CI_SigName" SG_ 2566878080 Sts_HP_LP_PressSensors "Status HP&LP pressure sensors";
BA_ "CI_SigId" SG_ 2566878080 Sts_HP_LP_PressSensors 18946;
BA_ "CI_ParId" SG_ 2566878080 Sts_HP_LP_PressSensors "IB4040";
BA_ "GenSigTimeoutTime_SGW" SG_ 2566878080 VCU_H2HighPress 5000;
BA_ "GenSigTimeoutTime_PCM" SG_ 2566878080 VCU_H2HighPress 5000;
BA_ "GenSigTimeoutTime_IC_MulticII" SG_ 2566878080 VCU_H2HighPress 5000;
BA_ "CI_SigName" SG_ 2566878080 VCU_H2HighPress "VCU_H2HighPressure";
BA_ "CI_SigId" SG_ 2566878080 VCU_H2HighPress 18944;
BA_ "CI_ParId" SG_ 2566878080 VCU_H2HighPress "IB4038";
BA_ "GenSigTimeoutTime_SGW" SG_ 2566878592 CSP_Fill_PurgPrAllowBySuperv 5000;
BA_ "GenSigTimeoutTime_PCM" SG_ 2566878592 CSP_Fill_PurgPrAllowBySuperv 5000;
BA_ "GenSigTimeoutTime_IC_MulticII" SG_ 2566878592 CSP_Fill_PurgPrAllowBySuperv 5000;
BA_ "CI_SigName" SG_ 2566878592 CSP_Fill_PurgPrAllowBySuperv "CSP Filling / Purging procedure allowed by Supervion";
BA_ "CI_SigId" SG_ 2566878592 CSP_Fill_PurgPrAllowBySuperv 23009;
BA_ "CI_ParId" SG_ 2566878592 CSP_Fill_PurgPrAllowBySuperv "IB4093";
BA_ "GenSigTimeoutTime_SGW" SG_ 2566878592 Concentr_H2Capteur_I_ppm 5000;
BA_ "GenSigTimeoutTime_PCM" SG_ 2566878592 Concentr_H2Capteur_I_ppm 5000;
BA_ "GenSigTimeoutTime_IC_MulticII" SG_ 2566878592 Concentr_H2Capteur_I_ppm 5000;
BA_ "CI_SigName" SG_ 2566878592 Concentr_H2Capteur_I_ppm "Concentration H2 capteur i en ppm";
BA_ "CI_SigId" SG_ 2566878592 Concentr_H2Capteur_I_ppm 18978;
BA_ "CI_ParId" SG_ 2566878592 Concentr_H2Capteur_I_ppm "IB4070";
BA_ "GenSigTimeoutTime_SGW" SG_ 2566878592 Concentr_H2Capteur_I 5000;
BA_ "GenSigTimeoutTime_PCM" SG_ 2566878592 Concentr_H2Capteur_I 5000;
BA_ "GenSigTimeoutTime_IC_MulticII" SG_ 2566878592 Concentr_H2Capteur_I 5000;
BA_ "CI_SigName" SG_ 2566878592 Concentr_H2Capteur_I "Concentration H2 capteur i";
BA_ "CI_SigId" SG_ 2566878592 Concentr_H2Capteur_I 18977;
BA_ "CI_ParId" SG_ 2566878592 Concentr_H2Capteur_I "IB4069";
BA_ "GenSigTimeoutTime_SGW" SG_ 2566878592 RefuelingMode 5000;
BA_ "GenSigTimeoutTime_PCM" SG_ 2566878592 RefuelingMode 5000;
BA_ "GenSigTimeoutTime_IC_MulticII" SG_ 2566878592 RefuelingMode 5000;
BA_ "CI_SigName" SG_ 2566878592 RefuelingMode "Refueling mode";
BA_ "CI_SigId" SG_ 2566878592 RefuelingMode 18976;
BA_ "CI_ParId" SG_ 2566878592 RefuelingMode "IB4068";
BA_ "GenSigTimeoutTime_SGW" SG_ 2566878592 FCU2_FC_CoolFilterCheck 5000;
BA_ "GenSigTimeoutTime_PCM" SG_ 2566878592 FCU2_FC_CoolFilterCheck 5000;
BA_ "CI_SigName" SG_ 2566878592 FCU2_FC_CoolFilterCheck "FCU2_FuelcellCoolantFilterCheck";
BA_ "CI_SigId" SG_ 2566878592 FCU2_FC_CoolFilterCheck 18975;
BA_ "CI_ParId" SG_ 2566878592 FCU2_FC_CoolFilterCheck "IB4067";
BA_ "GenSigTimeoutTime_SGW" SG_ 2566878592 FCU2_FC_CoolSupplyCheck 5000;
BA_ "GenSigTimeoutTime_PCM" SG_ 2566878592 FCU2_FC_CoolSupplyCheck 5000;
BA_ "CI_SigName" SG_ 2566878592 FCU2_FC_CoolSupplyCheck "FCU2_FuelcellCoolantSupplyCheck";
BA_ "CI_SigId" SG_ 2566878592 FCU2_FC_CoolSupplyCheck 18974;
BA_ "CI_ParId" SG_ 2566878592 FCU2_FC_CoolSupplyCheck "IB4066";
BA_ "SigType" SG_ 2566878592 IRD_2_Sts 4;
BA_ "GenSigTimeoutTime_SGW" SG_ 2566878592 IRD_2_Sts 5000;
BA_ "GenSigTimeoutTime_PCM" SG_ 2566878592 IRD_2_Sts 5000;
BA_ "GenSigTimeoutTime_IC_MulticII" SG_ 2566878592 IRD_2_Sts 5000;
BA_ "CI_SigName" SG_ 2566878592 IRD_2_Sts "IRD #2 status";
BA_ "CI_SigId" SG_ 2566878592 IRD_2_Sts 18973;
BA_ "CI_ParId" SG_ 2566878592 IRD_2_Sts "IB4065";
BA_ "SigType" SG_ 2566878592 IRD_1_Sts 4;
BA_ "GenSigTimeoutTime_SGW" SG_ 2566878592 IRD_1_Sts 5000;
BA_ "GenSigTimeoutTime_PCM" SG_ 2566878592 IRD_1_Sts 5000;
BA_ "GenSigTimeoutTime_IC_MulticII" SG_ 2566878592 IRD_1_Sts 5000;
BA_ "CI_SigName" SG_ 2566878592 IRD_1_Sts "IRD #1 status";
BA_ "CI_SigId" SG_ 2566878592 IRD_1_Sts 18972;
BA_ "CI_ParId" SG_ 2566878592 IRD_1_Sts "IB4064";
BA_ "GenSigTimeoutTime_SGW" SG_ 2566878592 H2_sensor_6_leakage_Sts 5000;
BA_ "GenSigTimeoutTime_PCM" SG_ 2566878592 H2_sensor_6_leakage_Sts 5000;
BA_ "GenSigTimeoutTime_IC_MulticII" SG_ 2566878592 H2_sensor_6_leakage_Sts 5000;
BA_ "CI_SigName" SG_ 2566878592 H2_sensor_6_leakage_Sts "H2 sensor 6 leakage status";
BA_ "CI_SigId" SG_ 2566878592 H2_sensor_6_leakage_Sts 18971;
BA_ "CI_ParId" SG_ 2566878592 H2_sensor_6_leakage_Sts "IB4063";
BA_ "GenSigTimeoutTime_SGW" SG_ 2566878592 H2_sensor_5_leakage_Sts 5000;
BA_ "GenSigTimeoutTime_PCM" SG_ 2566878592 H2_sensor_5_leakage_Sts 5000;
BA_ "GenSigTimeoutTime_IC_MulticII" SG_ 2566878592 H2_sensor_5_leakage_Sts 5000;
BA_ "CI_SigName" SG_ 2566878592 H2_sensor_5_leakage_Sts "H2 sensor 5 leakage status";
BA_ "CI_SigId" SG_ 2566878592 H2_sensor_5_leakage_Sts 18970;
BA_ "CI_ParId" SG_ 2566878592 H2_sensor_5_leakage_Sts "IB4062";
BA_ "SigType" SG_ 2566878592 H2_Refuel_plug_2 4;
BA_ "GenSigTimeoutTime_SGW" SG_ 2566878592 H2_Refuel_plug_2 5000;
BA_ "GenSigTimeoutTime_PCM" SG_ 2566878592 H2_Refuel_plug_2 5000;
BA_ "GenSigTimeoutTime_IC_MulticII" SG_ 2566878592 H2_Refuel_plug_2 5000;
BA_ "CI_SigName" SG_ 2566878592 H2_Refuel_plug_2 "H2 refueling plug 2";
BA_ "CI_SigId" SG_ 2566878592 H2_Refuel_plug_2 18969;
BA_ "CI_ParId" SG_ 2566878592 H2_Refuel_plug_2 "IB4061";
BA_ "SigType" SG_ 2566878592 H2_Refuel_plug_1 4;
BA_ "GenSigTimeoutTime_SGW" SG_ 2566878592 H2_Refuel_plug_1 5000;
BA_ "GenSigTimeoutTime_PCM" SG_ 2566878592 H2_Refuel_plug_1 5000;
BA_ "GenSigTimeoutTime_IC_MulticII" SG_ 2566878592 H2_Refuel_plug_1 5000;
BA_ "CI_SigName" SG_ 2566878592 H2_Refuel_plug_1 "H2 refueling plug 1";
BA_ "CI_SigId" SG_ 2566878592 H2_Refuel_plug_1 18968;
BA_ "CI_ParId" SG_ 2566878592 H2_Refuel_plug_1 "IB4060";
BA_ "SigType" SG_ 2566878592 H2_Temp_tank_4 1;
BA_ "GenSigTimeoutTime_SGW" SG_ 2566878592 H2_Temp_tank_4 5000;
BA_ "GenSigTimeoutTime_PCM" SG_ 2566878592 H2_Temp_tank_4 5000;
BA_ "GenSigTimeoutTime_IC_MulticII" SG_ 2566878592 H2_Temp_tank_4 5000;
BA_ "GenSigStartValue" SG_ 2566878592 H2_Temp_tank_4 40;
BA_ "CI_SigName" SG_ 2566878592 H2_Temp_tank_4 "H2 temperature tank 4";
BA_ "CI_SigId" SG_ 2566878592 H2_Temp_tank_4 18967;
BA_ "CI_ParId" SG_ 2566878592 H2_Temp_tank_4 "IB4059";
BA_ "SigType" SG_ 2566878592 H2_Temp_tank_3 1;
BA_ "GenSigTimeoutTime_SGW" SG_ 2566878592 H2_Temp_tank_3 5000;
BA_ "GenSigTimeoutTime_PCM" SG_ 2566878592 H2_Temp_tank_3 5000;
BA_ "GenSigTimeoutTime_IC_MulticII" SG_ 2566878592 H2_Temp_tank_3 5000;
BA_ "GenSigStartValue" SG_ 2566878592 H2_Temp_tank_3 40;
BA_ "CI_SigName" SG_ 2566878592 H2_Temp_tank_3 "H2 temperature tank 3";
BA_ "CI_SigId" SG_ 2566878592 H2_Temp_tank_3 18966;
BA_ "CI_ParId" SG_ 2566878592 H2_Temp_tank_3 "IB4058";
BA_ "SigType" SG_ 2566878592 H2_Temp_tank_2 1;
BA_ "GenSigTimeoutTime_SGW" SG_ 2566878592 H2_Temp_tank_2 5000;
BA_ "GenSigTimeoutTime_PCM" SG_ 2566878592 H2_Temp_tank_2 5000;
BA_ "GenSigTimeoutTime_IC_MulticII" SG_ 2566878592 H2_Temp_tank_2 5000;
BA_ "GenSigStartValue" SG_ 2566878592 H2_Temp_tank_2 40;
BA_ "CI_SigName" SG_ 2566878592 H2_Temp_tank_2 "H2 temperature tank 2";
BA_ "CI_SigId" SG_ 2566878592 H2_Temp_tank_2 18965;
BA_ "CI_ParId" SG_ 2566878592 H2_Temp_tank_2 "IB4057";
BA_ "SigType" SG_ 2566878592 H2_Temp_tank_1 1;
BA_ "GenSigTimeoutTime_SGW" SG_ 2566878592 H2_Temp_tank_1 5000;
BA_ "GenSigTimeoutTime_PCM" SG_ 2566878592 H2_Temp_tank_1 5000;
BA_ "GenSigTimeoutTime_IC_MulticII" SG_ 2566878592 H2_Temp_tank_1 5000;
BA_ "GenSigStartValue" SG_ 2566878592 H2_Temp_tank_1 40;
BA_ "CI_SigName" SG_ 2566878592 H2_Temp_tank_1 "H2 temperature tank 1";
BA_ "CI_SigId" SG_ 2566878592 H2_Temp_tank_1 18964;
BA_ "CI_ParId" SG_ 2566878592 H2_Temp_tank_1 "IB4056";
BA_ "SigType" SG_ 2566803211 VdcFullyOp 4;
BA_ "SPN" SG_ 2566803211 VdcFullyOp 1814;
BA_ "GenSigTimeoutTime_VCM" SG_ 2566803211 VdcFullyOp 500;
BA_ "GenSigTimeoutTime_SGW" SG_ 2566803211 VdcFullyOp 500;
BA_ "GenSigTimeoutTime_PCM" SG_ 2566803211 VdcFullyOp 500;
BA_ "GenSigTimeoutTime_IC_MulticS" SG_ 2566803211 VdcFullyOp 500;
BA_ "GenSigTimeoutTime_IC_MulticII" SG_ 2566803211 VdcFullyOp 500;
BA_ "GenSigTimeoutTime_ETC_Ecolife2" SG_ 2566803211 VdcFullyOp 500;
BA_ "GenSigTimeoutTime_ADCU" SG_ 2566803211 VdcFullyOp 500;
BA_ "CI_SigName" SG_ 2566803211 VdcFullyOp "VDC Fully Operational";
BA_ "CI_SigId" SG_ 2566803211 VdcFullyOp 347;
BA_ "CI_ParId" SG_ 2566803211 VdcFullyOp "1814";
BA_ "SigType" SG_ 2566803211 VdcInfoSig 4;
BA_ "SPN" SG_ 2566803211 VdcInfoSig 1813;
BA_ "GenSigTimeoutTime_VCM" SG_ 2566803211 VdcInfoSig 500;
BA_ "GenSigTimeoutTime_SGW" SG_ 2566803211 VdcInfoSig 500;
BA_ "GenSigTimeoutTime_PCM" SG_ 2566803211 VdcInfoSig 500;
BA_ "GenSigTimeoutTime_IC_MulticS" SG_ 2566803211 VdcInfoSig 500;
BA_ "GenSigTimeoutTime_IC_MulticII" SG_ 2566803211 VdcInfoSig 500;
BA_ "CI_SigName" SG_ 2566803211 VdcInfoSig "VDC Information Signal";
BA_ "CI_SigId" SG_ 2566803211 VdcInfoSig 346;
BA_ "CI_ParId" SG_ 2566803211 VdcInfoSig "1813";
BA_ "SigType" SG_ 2565867787 LongAccel 1;
BA_ "SPN" SG_ 2565867787 LongAccel 1810;
BA_ "GenSigTimeoutTime_SGW" SG_ 2565867787 LongAccel 500;
BA_ "GenSigTimeoutTime_PCM" SG_ 2565867787 LongAccel 500;
BA_ "GenSigTimeoutTime_ADCU" SG_ 2565867787 LongAccel 500;
BA_ "GenSigStartValue" SG_ 2565867787 LongAccel 125;
BA_ "CI_SigName" SG_ 2565867787 LongAccel "Longitudinal Acceleration";
BA_ "CI_SigId" SG_ 2565867787 LongAccel 360;
BA_ "CI_ParId" SG_ 2565867787 LongAccel "1810";
BA_ "SigType" SG_ 2565867787 LatAccel 1;
BA_ "SPN" SG_ 2565867787 LatAccel 1809;
BA_ "GenSigTimeoutTime_SGW" SG_ 2565867787 LatAccel 500;
BA_ "GenSigTimeoutTime_PCM" SG_ 2565867787 LatAccel 500;
BA_ "GenSigTimeoutTime_ADCU" SG_ 2565867787 LatAccel 500;
BA_ "GenSigStartValue" SG_ 2565867787 LatAccel 32127;
BA_ "CI_SigName" SG_ 2565867787 LatAccel "Lateral Acceleration";
BA_ "CI_SigId" SG_ 2565867787 LatAccel 359;
BA_ "CI_ParId" SG_ 2565867787 LatAccel "1809";
BA_ "SigType" SG_ 2565867787 YawRate 1;
BA_ "SPN" SG_ 2565867787 YawRate 1808;
BA_ "GenSigTimeoutTime_SGW" SG_ 2565867787 YawRate 500;
BA_ "GenSigTimeoutTime_PCM" SG_ 2565867787 YawRate 500;
BA_ "GenSigTimeoutTime_ADCU" SG_ 2565867787 YawRate 500;
BA_ "GenSigStartValue" SG_ 2565867787 YawRate 32113;
BA_ "CI_SigName" SG_ 2565867787 YawRate "Yaw Rate";
BA_ "CI_SigId" SG_ 2565867787 YawRate 358;
BA_ "CI_ParId" SG_ 2565867787 YawRate "1808";
BA_ "SigType" SG_ 2565867787 SteerWhAngle 1;
BA_ "SPN" SG_ 2565867787 SteerWhAngle 1807;
BA_ "GenSigTimeoutTime_SGW" SG_ 2565867787 SteerWhAngle 500;
BA_ "GenSigTimeoutTime_PCM" SG_ 2565867787 SteerWhAngle 500;
BA_ "GenSigTimeoutTime_MPPxPTFE2" SG_ 2565867787 SteerWhAngle 500;
BA_ "GenSigTimeoutTime_FMS_FMS5" SG_ 2565867787 SteerWhAngle 500;
BA_ "GenSigTimeoutTime_FMS_FMS4" SG_ 2565867787 SteerWhAngle 500;
BA_ "GenSigTimeoutTime_BCM_NBM" SG_ 2565867787 SteerWhAngle 500;
BA_ "GenSigTimeoutTime_ASM_ELC5_Fr" SG_ 2565867787 SteerWhAngle 500;
BA_ "GenSigTimeoutTime_ADCU" SG_ 2565867787 SteerWhAngle 500;
BA_ "GenSigStartValue" SG_ 2565867787 SteerWhAngle 32127;
BA_ "CI_SigName" SG_ 2565867787 SteerWhAngle "Steering Wheel Angle";
BA_ "CI_SigId" SG_ 2565867787 SteerWhAngle 355;
BA_ "CI_ParId" SG_ 2565867787 SteerWhAngle "1807";
BA_ "SigType" SG_ 2566832622 TripDistHr 1;
BA_ "SPN" SG_ 2566832622 TripDistHr 918;
BA_ "GenSigTimeoutTime_VMU" SG_ 2566832622 TripDistHr 5000;
BA_ "GenSigTimeoutTime_VCU" SG_ 2566832622 TripDistHr 5000;
BA_ "GenSigTimeoutTime_VCM" SG_ 2566832622 TripDistHr 5000;
BA_ "GenSigTimeoutTime_SGW2" SG_ 2566832622 TripDistHr 5000;
BA_ "GenSigTimeoutTime_SGW" SG_ 2566832622 TripDistHr 5000;
BA_ "GenSigTimeoutTime_PCM" SG_ 2566832622 TripDistHr 5000;
BA_ "GenSigTimeoutTime_INVEM1_ELFA3" SG_ 2566832622 TripDistHr 5000;
BA_ "GenSigTimeoutTime_IC_MulticS" SG_ 2566832622 TripDistHr 5000;
BA_ "GenSigTimeoutTime_DICO" SG_ 2566832622 TripDistHr 5000;
BA_ "GenSigTimeoutTime_ACM_CANAIR" SG_ 2566832622 TripDistHr 5000;
BA_ "CI_SigName" SG_ 2566832622 TripDistHr "Trip Distance (High Resolution)";
BA_ "CI_SigId" SG_ 2566832622 TripDistHr 675;
BA_ "CI_ParId" SG_ 2566832622 TripDistHr "918";
BA_ "SigType" SG_ 2566832622 TotVehDistHr 1;
BA_ "SPN" SG_ 2566832622 TotVehDistHr 917;
BA_ "GenSigTimeoutTime_VMU" SG_ 2566832622 TotVehDistHr 5000;
BA_ "GenSigTimeoutTime_VCU" SG_ 2566832622 TotVehDistHr 5000;
BA_ "GenSigTimeoutTime_VCM" SG_ 2566832622 TotVehDistHr 5000;
BA_ "GenSigTimeoutTime_TPMS" SG_ 2566832622 TotVehDistHr 5000;
BA_ "GenSigTimeoutTime_SGW2" SG_ 2566832622 TotVehDistHr 5000;
BA_ "GenSigTimeoutTime_SGW" SG_ 2566832622 TotVehDistHr 5000;
BA_ "GenSigTimeoutTime_RM_IRCS" SG_ 2566832622 TotVehDistHr 5000;
BA_ "GenSigTimeoutTime_PCM" SG_ 2566832622 TotVehDistHr 5000;
BA_ "GenSigTimeoutTime_MPPxPTFE2" SG_ 2566832622 TotVehDistHr 5000;
BA_ "GenSigTimeoutTime_MBMS" SG_ 2566832622 TotVehDistHr 5000;
BA_ "GenSigTimeoutTime_INVEM1_ELFA3" SG_ 2566832622 TotVehDistHr 5000;
BA_ "GenSigTimeoutTime_IC_MulticS" SG_ 2566832622 TotVehDistHr 5000;
BA_ "GenSigTimeoutTime_IC_MulticII" SG_ 2566832622 TotVehDistHr 5000;
BA_ "GenSigTimeoutTime_FMS_FMS5" SG_ 2566832622 TotVehDistHr 5000;
BA_ "GenSigTimeoutTime_FMS_FMS4" SG_ 2566832622 TotVehDistHr 5000;
BA_ "GenSigTimeoutTime_ETC_Ecolife2" SG_ 2566832622 TotVehDistHr 5000;
BA_ "GenSigTimeoutTime_ECM_MD1_G" SG_ 2566832622 TotVehDistHr 5000;
BA_ "GenSigTimeoutTime_ECM_MD1_D" SG_ 2566832622 TotVehDistHr 5000;
BA_ "GenSigTimeoutTime_DMS" SG_ 2566832622 TotVehDistHr 5000;
BA_ "GenSigTimeoutTime_DICO" SG_ 2566832622 TotVehDistHr 5000;
BA_ "GenSigTimeoutTime_BSM_EBS" SG_ 2566832622 TotVehDistHr 5000;
BA_ "GenSigTimeoutTime_BCM_NBM" SG_ 2566832622 TotVehDistHr 5000;
BA_ "GenSigTimeoutTime_Av2HP" SG_ 2566832622 TotVehDistHr 5000;
BA_ "GenSigTimeoutTime_ADCU" SG_ 2566832622 TotVehDistHr 5000;
BA_ "GenSigTimeoutTime_ACM_CANAIR" SG_ 2566832622 TotVehDistHr 5000;
BA_ "CI_SigName" SG_ 2566832622 TotVehDistHr "Total Vehicle Distance (High Resolution)";
BA_ "CI_SigId" SG_ 2566832622 TotVehDistHr 674;
BA_ "CI_ParId" SG_ 2566832622 TotVehDistHr "917";
BA_ "SigType" SG_ 2566842606 Altitude 1;
BA_ "SPN" SG_ 2566842606 Altitude 580;
BA_ "GenSigTimeoutTime_SGW2" SG_ 2566842606 Altitude 5000;
BA_ "GenSigTimeoutTime_SGW" SG_ 2566842606 Altitude 5000;
BA_ "GenSigTimeoutTime_AI_CAID" SG_ 2566842606 Altitude 5000;
BA_ "GenSigStartValue" SG_ 2566842606 Altitude 20000;
BA_ "CI_SigName" SG_ 2566842606 Altitude "Altitude";
BA_ "CI_SigId" SG_ 2566842606 Altitude 3459;
BA_ "CI_ParId" SG_ 2566842606 Altitude "580";
BA_ "SigType" SG_ 2566842606 Pitch 1;
BA_ "SPN" SG_ 2566842606 Pitch 583;
BA_ "GenSigStartValue" SG_ 2566842606 Pitch 25600;
BA_ "CI_SigName" SG_ 2566842606 Pitch "Pitch";
BA_ "CI_SigId" SG_ 2566842606 Pitch 3458;
BA_ "CI_ParId" SG_ 2566842606 Pitch "583";
BA_ "SigType" SG_ 2566842606 NavBasedVehSpeed 1;
BA_ "SPN" SG_ 2566842606 NavBasedVehSpeed 517;
BA_ "GenSigTimeoutTime_SGW2" SG_ 2566842606 NavBasedVehSpeed 5000;
BA_ "GenSigTimeoutTime_SGW" SG_ 2566842606 NavBasedVehSpeed 5000;
BA_ "CI_SigName" SG_ 2566842606 NavBasedVehSpeed "Navigation-Based Vehicle Speed";
BA_ "CI_SigId" SG_ 2566842606 NavBasedVehSpeed 3457;
BA_ "CI_ParId" SG_ 2566842606 NavBasedVehSpeed "517";
BA_ "SigType" SG_ 2566842606 CompassBear 1;
BA_ "SPN" SG_ 2566842606 CompassBear 165;
BA_ "CI_SigName" SG_ 2566842606 CompassBear "Compass Bearing";
BA_ "CI_SigId" SG_ 2566842606 CompassBear 3456;
BA_ "CI_ParId" SG_ 2566842606 CompassBear "165";
BA_ "SigType" SG_ 2566846208 BatPot_PwrIn1 1;
BA_ "SPN" SG_ 2566846208 BatPot_PwrIn1 168;
BA_ "GenSigTimeoutTime_VCM" SG_ 2566846208 BatPot_PwrIn1 5000;
BA_ "GenSigTimeoutTime_SGW" SG_ 2566846208 BatPot_PwrIn1 5000;
BA_ "GenSigTimeoutTime_PCM" SG_ 2566846208 BatPot_PwrIn1 5000;
BA_ "GenSigTimeoutTime_MPPxPTFE2" SG_ 2566846208 BatPot_PwrIn1 5000;
BA_ "GenSigTimeoutTime_FMS_FMS5" SG_ 2566846208 BatPot_PwrIn1 5000;
BA_ "GenSigTimeoutTime_FMS_FMS4" SG_ 2566846208 BatPot_PwrIn1 5000;
BA_ "GenSigTimeoutTime_BSM_EBS" SG_ 2566846208 BatPot_PwrIn1 5000;
BA_ "GenSigTimeoutTime_ADCU" SG_ 2566846208 BatPot_PwrIn1 5000;
BA_ "CI_SigName" SG_ 2566846208 BatPot_PwrIn1 "Battery Potential / Power Input 1";
BA_ "CI_SigId" SG_ 2566846208 BatPot_PwrIn1 2209;
BA_ "CI_ParId" SG_ 2566846208 BatPot_PwrIn1 "168";
BA_ "SigType" SG_ 2566846451 BatPot_PwrIn1_FEF7F3 1;
BA_ "SPN" SG_ 2566846451 BatPot_PwrIn1_FEF7F3 168;
BA_ "GenSigTimeoutTime_SGW" SG_ 2566846451 BatPot_PwrIn1_FEF7F3 500;
BA_ "GenSigTimeoutTime_PCM" SG_ 2566846451 BatPot_PwrIn1_FEF7F3 500;
BA_ "CI_SigName" SG_ 2566846451 BatPot_PwrIn1_FEF7F3 "Battery Potential / Power Input 1";
BA_ "CI_SigId" SG_ 2566846451 BatPot_PwrIn1_FEF7F3 2215;
BA_ "CI_ParId" SG_ 2566846451 BatPot_PwrIn1_FEF7F3 "168";
BA_ "SigType" SG_ 2566804211 SliBat1NetCurHr 1;
BA_ "SPN" SG_ 2566804211 SliBat1NetCurHr 2579;
BA_ "GenSigTimeoutTime_SGW" SG_ 2566804211 SliBat1NetCurHr 500;
BA_ "GenSigTimeoutTime_PCM" SG_ 2566804211 SliBat1NetCurHr 500;
BA_ "GenSigStartValue" SG_ 2566804211 SliBat1NetCurHr 32000;
BA_ "CI_SigName" SG_ 2566804211 SliBat1NetCurHr "SLI Battery 1 Net Current (High Range/Resolution)";
BA_ "CI_SigId" SG_ 2566804211 SliBat1NetCurHr 2219;
BA_ "CI_ParId" SG_ 2566804211 SliBat1NetCurHr "2579";
BA_ "SigType" SG_ 2566698739 SliBatHealth 1;
BA_ "SPN" SG_ 2566698739 SliBatHealth 5983;
BA_ "GenSigTimeoutTime_SGW" SG_ 2566698739 SliBatHealth 5000;
BA_ "GenSigTimeoutTime_PCM" SG_ 2566698739 SliBatHealth 5000;
BA_ "CI_SigName" SG_ 2566698739 SliBatHealth "SLI Battery Pack Health";
BA_ "CI_SigId" SG_ 2566698739 SliBatHealth 2589;
BA_ "CI_ParId" SG_ 2566698739 SliBatHealth "5983";
BA_ "SigType" SG_ 2566698739 SliBatCap 1;
BA_ "SPN" SG_ 2566698739 SliBatCap 5982;
BA_ "GenSigTimeoutTime_SGW" SG_ 2566698739 SliBatCap 5000;
BA_ "GenSigTimeoutTime_PCM" SG_ 2566698739 SliBatCap 5000;
BA_ "CI_SigName" SG_ 2566698739 SliBatCap "SLI Battery Pack Capacity";
BA_ "CI_SigId" SG_ 2566698739 SliBatCap 2588;
BA_ "CI_ParId" SG_ 2566698739 SliBatCap "5982";
BA_ "SigType" SG_ 2566698739 SliBatSoc 1;
BA_ "SPN" SG_ 2566698739 SliBatSoc 5981;
BA_ "GenSigTimeoutTime_SGW" SG_ 2566698739 SliBatSoc 5000;
BA_ "GenSigTimeoutTime_PCM" SG_ 2566698739 SliBatSoc 5000;
BA_ "CI_SigName" SG_ 2566698739 SliBatSoc "SLI Battery Pack State of Charge";
BA_ "CI_SigId" SG_ 2566698739 SliBatSoc 2587;
BA_ "CI_ParId" SG_ 2566698739 SliBatSoc "5981";
BA_ "SigType" SG_ 2566843630 Vin 8;
BA_ "SPN" SG_ 2566843630 Vin 237;
BA_ "GenSigTimeoutTime_SGW" SG_ 2566843630 Vin 50000;
BA_ "GenSigTimeoutTime_PCM" SG_ 2566843630 Vin 50000;
BA_ "GenSigTimeoutTime_MPPxPTFE2" SG_ 2566843630 Vin 50000;
BA_ "GenSigTimeoutTime_FMS_FMS5" SG_ 2566843630 Vin 50000;
BA_ "GenSigTimeoutTime_FMS_FMS4" SG_ 2566843630 Vin 50000;
BA_ "GenSigTimeoutTime_ADCU" SG_ 2566843630 Vin 50000;
BA_ "CI_SigName" SG_ 2566843630 Vin "Vehicle Identification Number";
BA_ "CI_SigId" SG_ 2566843630 Vin 744;
BA_ "CI_ParId" SG_ 2566843630 Vin "237";
BA_ "SigType" SG_ 2566845212 Long 1;
BA_ "SPN" SG_ 2566845212 Long 585;
BA_ "GenSigTimeoutTime_PCM" SG_ 2566845212 Long 5000;
BA_ "GenSigStartValue" SG_ 2566845212 Long 2100000000;
BA_ "CI_SigName" SG_ 2566845212 Long "Longitude";
BA_ "CI_SigId" SG_ 2566845212 Long 3462;
BA_ "CI_ParId" SG_ 2566845212 Long "585";
BA_ "SigType" SG_ 2566845212 Lat 1;
BA_ "SPN" SG_ 2566845212 Lat 584;
BA_ "GenSigTimeoutTime_PCM" SG_ 2566845212 Lat 5000;
BA_ "GenSigStartValue" SG_ 2566845212 Lat 2100000000;
BA_ "CI_SigName" SG_ 2566845212 Lat "Latitude";
BA_ "CI_SigId" SG_ 2566845212 Lat 3461;
BA_ "CI_ParId" SG_ 2566845212 Lat "584";
BA_ "SigType" SG_ 2566845422 Long_FEF3EE 1;
BA_ "SPN" SG_ 2566845422 Long_FEF3EE 585;
BA_ "GenSigTimeoutTime_SGW" SG_ 2566845422 Long_FEF3EE 5000;
BA_ "GenSigTimeoutTime_MBMS" SG_ 2566845422 Long_FEF3EE 5000;
BA_ "GenSigStartValue" SG_ 2566845422 Long_FEF3EE 2100000000;
BA_ "CI_SigName" SG_ 2566845422 Long_FEF3EE "Longitude";
BA_ "CI_SigId" SG_ 2566845422 Long_FEF3EE 3465;
BA_ "CI_ParId" SG_ 2566845422 Long_FEF3EE "585";
BA_ "SigType" SG_ 2566845422 Lat_FEF3EE 1;
BA_ "SPN" SG_ 2566845422 Lat_FEF3EE 584;
BA_ "GenSigTimeoutTime_SGW" SG_ 2566845422 Lat_FEF3EE 5000;
BA_ "GenSigTimeoutTime_MBMS" SG_ 2566845422 Lat_FEF3EE 5000;
BA_ "GenSigStartValue" SG_ 2566845422 Lat_FEF3EE 2100000000;
BA_ "CI_SigName" SG_ 2566845422 Lat_FEF3EE "Latitude";
BA_ "CI_SigId" SG_ 2566845422 Lat_FEF3EE 3464;
BA_ "CI_ParId" SG_ 2566845422 Lat_FEF3EE "584";
BA_ "SigType" SG_ 2566842927 Axle_Weight_5 1;
BA_ "GenSigTimeoutTime_SGW" SG_ 2566842927 Axle_Weight_5 500;
BA_ "GenSigTimeoutTime_PCM" SG_ 2566842927 Axle_Weight_5 500;
BA_ "CI_SigName" SG_ 2566842927 Axle_Weight_5 "Axle_Weight_5";
BA_ "CI_SigId" SG_ 2566842927 Axle_Weight_5 17513;
BA_ "CI_ParId" SG_ 2566842927 Axle_Weight_5 "IB2165";
BA_ "SigType" SG_ 2566842927 Axle_Weight_4 1;
BA_ "GenSigTimeoutTime_SGW" SG_ 2566842927 Axle_Weight_4 500;
BA_ "GenSigTimeoutTime_PCM" SG_ 2566842927 Axle_Weight_4 500;
BA_ "CI_SigName" SG_ 2566842927 Axle_Weight_4 "Axle_Weight_4";
BA_ "CI_SigId" SG_ 2566842927 Axle_Weight_4 17512;
BA_ "CI_ParId" SG_ 2566842927 Axle_Weight_4 "IB2164";
BA_ "SigType" SG_ 2566842927 Axle_Weight_3 1;
BA_ "GenSigTimeoutTime_SGW" SG_ 2566842927 Axle_Weight_3 500;
BA_ "GenSigTimeoutTime_PCM" SG_ 2566842927 Axle_Weight_3 500;
BA_ "CI_SigName" SG_ 2566842927 Axle_Weight_3 "Axle_Weight_3";
BA_ "CI_SigId" SG_ 2566842927 Axle_Weight_3 17511;
BA_ "CI_ParId" SG_ 2566842927 Axle_Weight_3 "IB2163";
BA_ "SigType" SG_ 2566842927 Axle_Weight_2 1;
BA_ "GenSigTimeoutTime_SGW" SG_ 2566842927 Axle_Weight_2 500;
BA_ "GenSigTimeoutTime_PCM" SG_ 2566842927 Axle_Weight_2 500;
BA_ "CI_SigName" SG_ 2566842927 Axle_Weight_2 "Axle_Weight_2";
BA_ "CI_SigId" SG_ 2566842927 Axle_Weight_2 17510;
BA_ "CI_ParId" SG_ 2566842927 Axle_Weight_2 "IB2162";
BA_ "SigType" SG_ 2566842927 Axle_Weight_1 1;
BA_ "GenSigTimeoutTime_SGW" SG_ 2566842927 Axle_Weight_1 500;
BA_ "GenSigTimeoutTime_PCM" SG_ 2566842927 Axle_Weight_1 500;
BA_ "CI_SigName" SG_ 2566842927 Axle_Weight_1 "Axle_Weight_1";
BA_ "CI_SigId" SG_ 2566842927 Axle_Weight_1 17509;
BA_ "CI_ParId" SG_ 2566842927 Axle_Weight_1 "IB2161";
BA_ "GenSigTimeoutTime_SGW" SG_ 2566842927 Axle_Location 500;
BA_ "GenSigTimeoutTime_PCM" SG_ 2566842927 Axle_Location 500;
BA_ "CI_SigName" SG_ 2566842927 Axle_Location "Axle_Location";
BA_ "CI_SigId" SG_ 2566842927 Axle_Location 17508;
BA_ "CI_ParId" SG_ 2566842927 Axle_Location "IB2160";
BA_ "SigType" SG_ 2566842944 Axle_Weight_5_FEEA40 1;
BA_ "GenSigTimeoutTime_SGW" SG_ 2566842944 Axle_Weight_5_FEEA40 500;
BA_ "GenSigTimeoutTime_PCM" SG_ 2566842944 Axle_Weight_5_FEEA40 500;
BA_ "CI_SigName" SG_ 2566842944 Axle_Weight_5_FEEA40 "Axle_Weight_5";
BA_ "CI_SigId" SG_ 2566842944 Axle_Weight_5_FEEA40 17520;
BA_ "CI_ParId" SG_ 2566842944 Axle_Weight_5_FEEA40 "IB2165";
BA_ "SigType" SG_ 2566842944 Axle_Weight_4_FEEA40 1;
BA_ "GenSigTimeoutTime_SGW" SG_ 2566842944 Axle_Weight_4_FEEA40 500;
BA_ "GenSigTimeoutTime_PCM" SG_ 2566842944 Axle_Weight_4_FEEA40 500;
BA_ "CI_SigName" SG_ 2566842944 Axle_Weight_4_FEEA40 "Axle_Weight_4";
BA_ "CI_SigId" SG_ 2566842944 Axle_Weight_4_FEEA40 17519;
BA_ "CI_ParId" SG_ 2566842944 Axle_Weight_4_FEEA40 "IB2164";
BA_ "SigType" SG_ 2566842944 Axle_Weight_3_FEEA40 1;
BA_ "GenSigTimeoutTime_SGW" SG_ 2566842944 Axle_Weight_3_FEEA40 500;
BA_ "GenSigTimeoutTime_PCM" SG_ 2566842944 Axle_Weight_3_FEEA40 500;
BA_ "CI_SigName" SG_ 2566842944 Axle_Weight_3_FEEA40 "Axle_Weight_3";
BA_ "CI_SigId" SG_ 2566842944 Axle_Weight_3_FEEA40 17518;
BA_ "CI_ParId" SG_ 2566842944 Axle_Weight_3_FEEA40 "IB2163";
BA_ "SigType" SG_ 2566842944 Axle_Weight_2_FEEA40 1;
BA_ "GenSigTimeoutTime_SGW" SG_ 2566842944 Axle_Weight_2_FEEA40 500;
BA_ "GenSigTimeoutTime_PCM" SG_ 2566842944 Axle_Weight_2_FEEA40 500;
BA_ "CI_SigName" SG_ 2566842944 Axle_Weight_2_FEEA40 "Axle_Weight_2";
BA_ "CI_SigId" SG_ 2566842944 Axle_Weight_2_FEEA40 17517;
BA_ "CI_ParId" SG_ 2566842944 Axle_Weight_2_FEEA40 "IB2162";
BA_ "SigType" SG_ 2566842944 Axle_Weight_1_FEEA40 1;
BA_ "GenSigTimeoutTime_SGW" SG_ 2566842944 Axle_Weight_1_FEEA40 500;
BA_ "GenSigTimeoutTime_PCM" SG_ 2566842944 Axle_Weight_1_FEEA40 500;
BA_ "CI_SigName" SG_ 2566842944 Axle_Weight_1_FEEA40 "Axle_Weight_1";
BA_ "CI_SigId" SG_ 2566842944 Axle_Weight_1_FEEA40 17516;
BA_ "CI_ParId" SG_ 2566842944 Axle_Weight_1_FEEA40 "IB2161";
BA_ "GenSigTimeoutTime_SGW" SG_ 2566842944 Axle_Location_FEEA40 500;
BA_ "GenSigTimeoutTime_PCM" SG_ 2566842944 Axle_Location_FEEA40 500;
BA_ "CI_SigName" SG_ 2566842944 Axle_Location_FEEA40 "Axle_Location";
BA_ "CI_SigId" SG_ 2566842944 Axle_Location_FEEA40 17515;
BA_ "CI_ParId" SG_ 2566842944 Axle_Location_FEEA40 "IB2160";
BA_ "SigType" SG_ 2566848256 WaterInFuelInd1 4;
BA_ "SPN" SG_ 2566848256 WaterInFuelInd1 97;
BA_ "GenSigTimeoutTime_VCM" SG_ 2566848256 WaterInFuelInd1 5000;
BA_ "GenSigTimeoutTime_SGW" SG_ 2566848256 WaterInFuelInd1 5000;
BA_ "GenSigTimeoutTime_PCM" SG_ 2566848256 WaterInFuelInd1 5000;
BA_ "GenSigTimeoutTime_IC_MulticS" SG_ 2566848256 WaterInFuelInd1 5000;
BA_ "GenSigTimeoutTime_FMS_FMS5" SG_ 2566848256 WaterInFuelInd1 5000;
BA_ "GenSigTimeoutTime_FMS_FMS4" SG_ 2566848256 WaterInFuelInd1 5000;
BA_ "CI_SigName" SG_ 2566848256 WaterInFuelInd1 "Water In Fuel Indicator 1";
BA_ "CI_SigId" SG_ 2566848256 WaterInFuelInd1 1617;
BA_ "CI_ParId" SG_ 2566848256 WaterInFuelInd1 "97";
BA_ "SPN" SG_ 2349075360 XbrMsgCnt 3189;
BA_ "GenSigTimeoutTime_SGW" SG_ 2349075360 XbrMsgCnt 1000;
BA_ "GenSigTimeoutTime_PCM" SG_ 2349075360 XbrMsgCnt 1000;
BA_ "GenSigTimeoutTime_BSM_EBS" SG_ 2349075360 XbrMsgCnt 1000;
BA_ "CI_SigName" SG_ 2349075360 XbrMsgCnt "XBR Message Counter";
BA_ "CI_SigId" SG_ 2349075360 XbrMsgCnt 343;
BA_ "CI_ParId" SG_ 2349075360 XbrMsgCnt "3189";
BA_ "SigType" SG_ 2566845436 Long_FEF3FC 1;
BA_ "SPN" SG_ 2566845436 Long_FEF3FC 585;
BA_ "GenSigTimeoutTime_PCM" SG_ 2566845436 Long_FEF3FC 25000;
BA_ "GenSigStartValue" SG_ 2566845436 Long_FEF3FC 2100000000;
BA_ "CI_SigId" SG_ 2566845436 Long_FEF3FC 50004;
BA_ "SigType" SG_ 2566845436 Lat_FEF3FC 1;
BA_ "SPN" SG_ 2566845436 Lat_FEF3FC 584;
BA_ "GenSigTimeoutTime_PCM" SG_ 2566845436 Lat_FEF3FC 25000;
BA_ "GenSigStartValue" SG_ 2566845436 Lat_FEF3FC 2100000000;
BA_ "CI_SigId" SG_ 2566845436 Lat_FEF3FC 50003;
BA_ "SigType" SG_ 2565472330 PgnRqst_4A_00 6;
BA_ "SPN" SG_ 2565472330 PgnRqst_4A_00 2540;
BA_ "CI_SigName" SG_ 2565472330 PgnRqst_4A_00 "Parameter Group Number (RQST)";
BA_ "CI_SigId" SG_ 2565472330 PgnRqst_4A_00 100001;
BA_ "CI_ParId" SG_ 2565472330 PgnRqst_4A_00 "2540";
BA_ "SigType" SG_ 2565482314 PgnRqst_4A_27 6;
BA_ "SPN" SG_ 2565482314 PgnRqst_4A_27 2540;
BA_ "CI_SigName" SG_ 2565482314 PgnRqst_4A_27 "Parameter Group Number (RQST)";
BA_ "CI_SigId" SG_ 2565482314 PgnRqst_4A_27 100003;
BA_ "CI_ParId" SG_ 2565482314 PgnRqst_4A_27 "2540";
BA_ "SigType" SG_ 2565478218 PgnRqst_4A_17 6;
BA_ "SPN" SG_ 2565478218 PgnRqst_4A_17 2540;
BA_ "CI_SigName" SG_ 2565478218 PgnRqst_4A_17 "Parameter Group Number (RQST)";
BA_ "CI_SigId" SG_ 2565478218 PgnRqst_4A_17 100005;
BA_ "CI_ParId" SG_ 2565478218 PgnRqst_4A_17 "2540";
BA_ "SigType" SG_ 2565473098 PgnRqst_4A_03 6;
BA_ "SPN" SG_ 2565473098 PgnRqst_4A_03 2540;
BA_ "CI_SigName" SG_ 2565473098 PgnRqst_4A_03 "Parameter Group Number (RQST)";
BA_ "CI_SigId" SG_ 2565473098 PgnRqst_4A_03 100007;
BA_ "CI_ParId" SG_ 2565473098 PgnRqst_4A_03 "2540";
BA_ "SigType" SG_ 2565475146 PgnRqst_4A_0B 6;
BA_ "SPN" SG_ 2565475146 PgnRqst_4A_0B 2540;
BA_ "CI_SigName" SG_ 2565475146 PgnRqst_4A_0B "Parameter Group Number (RQST)";
BA_ "CI_SigId" SG_ 2565475146 PgnRqst_4A_0B 100009;
BA_ "CI_ParId" SG_ 2565475146 PgnRqst_4A_0B "2540";
BA_ "SigType" SG_ 2565479754 PgnRqst_4A_1D 6;
BA_ "SPN" SG_ 2565479754 PgnRqst_4A_1D 2540;
BA_ "CI_SigName" SG_ 2565479754 PgnRqst_4A_1D "Parameter Group Number (RQST)";
BA_ "CI_SigId" SG_ 2565479754 PgnRqst_4A_1D 100011;
BA_ "CI_ParId" SG_ 2565479754 PgnRqst_4A_1D "2540";
BA_ "SigType" SG_ 2565486666 PgnRqst_4A_38 6;
BA_ "SPN" SG_ 2565486666 PgnRqst_4A_38 2540;
BA_ "CI_SigName" SG_ 2565486666 PgnRqst_4A_38 "Parameter Group Number (RQST)";
BA_ "CI_SigId" SG_ 2565486666 PgnRqst_4A_38 100013;
BA_ "CI_ParId" SG_ 2565486666 PgnRqst_4A_38 "2540";
BA_ "SigType" SG_ 2565504586 PgnRqst_4A_7E 6;
BA_ "SPN" SG_ 2565504586 PgnRqst_4A_7E 2540;
BA_ "CI_SigName" SG_ 2565504586 PgnRqst_4A_7E "Parameter Group Number (RQST)";
BA_ "CI_SigId" SG_ 2565504586 PgnRqst_4A_7E 100015;
BA_ "CI_ParId" SG_ 2565504586 PgnRqst_4A_7E "2540";
BA_ "SigType" SG_ 2565512778 PgnRqst_4A_9E 6;
BA_ "SPN" SG_ 2565512778 PgnRqst_4A_9E 2540;
BA_ "CI_SigName" SG_ 2565512778 PgnRqst_4A_9E "Parameter Group Number (RQST)";
BA_ "CI_SigId" SG_ 2565512778 PgnRqst_4A_9E 100017;
BA_ "CI_ParId" SG_ 2565512778 PgnRqst_4A_9E "2540";
BA_ "SigType" SG_ 2565513290 PgnRqst_4A_A0 6;
BA_ "SPN" SG_ 2565513290 PgnRqst_4A_A0 2540;
BA_ "CI_SigName" SG_ 2565513290 PgnRqst_4A_A0 "Parameter Group Number (RQST)";
BA_ "CI_SigId" SG_ 2565513290 PgnRqst_4A_A0 100019;
BA_ "CI_ParId" SG_ 2565513290 PgnRqst_4A_A0 "2540";
BA_ "SigType" SG_ 2565480778 PgnRqst_4A_21 6;
BA_ "SPN" SG_ 2565480778 PgnRqst_4A_21 2540;
BA_ "CI_SigName" SG_ 2565480778 PgnRqst_4A_21 "Parameter Group Number (RQST)";
BA_ "CI_SigId" SG_ 2565480778 PgnRqst_4A_21 100021;
BA_ "CI_ParId" SG_ 2565480778 PgnRqst_4A_21 "2540";
BA_ "SigType" SG_ 2565496394 PgnRqst_4A_5E 6;
BA_ "SPN" SG_ 2565496394 PgnRqst_4A_5E 2540;
BA_ "CI_SigName" SG_ 2565496394 PgnRqst_4A_5E "Parameter Group Number (RQST)";
BA_ "CI_SigId" SG_ 2565496394 PgnRqst_4A_5E 100023;
BA_ "CI_ParId" SG_ 2565496394 PgnRqst_4A_5E "2540";
BA_ "SigType" SG_ 2565495370 PgnRqst_4A_5A 6;
BA_ "SPN" SG_ 2565495370 PgnRqst_4A_5A 2540;
BA_ "CI_SigName" SG_ 2565495370 PgnRqst_4A_5A "Parameter Group Number (RQST)";
BA_ "CI_SigId" SG_ 2565495370 PgnRqst_4A_5A 100025;
BA_ "CI_ParId" SG_ 2565495370 PgnRqst_4A_5A "2540";
BA_ "SigType" SG_ 2565484362 PgnRqst_4A_2F 6;
BA_ "SPN" SG_ 2565484362 PgnRqst_4A_2F 2540;
BA_ "CI_SigName" SG_ 2565484362 PgnRqst_4A_2F "Parameter Group Number (RQST)";
BA_ "CI_SigId" SG_ 2565484362 PgnRqst_4A_2F 100027;
BA_ "CI_ParId" SG_ 2565484362 PgnRqst_4A_2F "2540";
BA_ "SigType" SG_ 2565488714 PgnRqst_4A_40 6;
BA_ "SPN" SG_ 2565488714 PgnRqst_4A_40 2540;
BA_ "CI_SigName" SG_ 2565488714 PgnRqst_4A_40 "Parameter Group Number (RQST)";
BA_ "CI_SigId" SG_ 2565488714 PgnRqst_4A_40 100029;
BA_ "CI_ParId" SG_ 2565488714 PgnRqst_4A_40 "2540";
BA_ "SigType" SG_ 2565535562 PgnRqst_4A_F7 6;
BA_ "SPN" SG_ 2565535562 PgnRqst_4A_F7 2540;
BA_ "CI_SigName" SG_ 2565535562 PgnRqst_4A_F7 "Parameter Group Number (RQST)";
BA_ "CI_SigId" SG_ 2565535562 PgnRqst_4A_F7 100031;
BA_ "CI_ParId" SG_ 2565535562 PgnRqst_4A_F7 "2540";
BA_ "SigType" SG_ 2565535306 PgnRqst_4A_F6 6;
BA_ "SPN" SG_ 2565535306 PgnRqst_4A_F6 2540;
BA_ "CI_SigName" SG_ 2565535306 PgnRqst_4A_F6 "Parameter Group Number (RQST)";
BA_ "CI_SigId" SG_ 2565535306 PgnRqst_4A_F6 100033;
BA_ "CI_ParId" SG_ 2565535306 PgnRqst_4A_F6 "2540";
BA_ "SigType" SG_ 2565534538 PgnRqst_4A_F3 6;
BA_ "SPN" SG_ 2565534538 PgnRqst_4A_F3 2540;
BA_ "CI_SigName" SG_ 2565534538 PgnRqst_4A_F3 "Parameter Group Number (RQST)";
BA_ "CI_SigId" SG_ 2565534538 PgnRqst_4A_F3 100035;
BA_ "CI_ParId" SG_ 2565534538 PgnRqst_4A_F3 "2540";
BA_ "SigType" SG_ 2565491018 PgnRqst_4A_49 6;
BA_ "SPN" SG_ 2565491018 PgnRqst_4A_49 2540;
BA_ "CI_SigName" SG_ 2565491018 PgnRqst_4A_49 "Parameter Group Number (RQST)";
BA_ "CI_SigId" SG_ 2565491018 PgnRqst_4A_49 100037;
BA_ "CI_ParId" SG_ 2565491018 PgnRqst_4A_49 "2540";
BA_ "SigType" SG_ 2565476426 PgnRqst_4A_10 6;
BA_ "SPN" SG_ 2565476426 PgnRqst_4A_10 2540;
BA_ "CI_SigName" SG_ 2565476426 PgnRqst_4A_10 "Parameter Group Number (RQST)";
BA_ "CI_SigId" SG_ 2565476426 PgnRqst_4A_10 100039;
BA_ "CI_ParId" SG_ 2565476426 PgnRqst_4A_10 "2540";
BA_ "SigType" SG_ 2565484106 PgnRqst_4A_2E 6;
BA_ "SPN" SG_ 2565484106 PgnRqst_4A_2E 2540;
BA_ "CI_SigName" SG_ 2565484106 PgnRqst_4A_2E "Parameter Group Number (RQST)";
BA_ "CI_SigId" SG_ 2565484106 PgnRqst_4A_2E 100041;
BA_ "CI_ParId" SG_ 2565484106 PgnRqst_4A_2E "2540";
BA_ "SigType" SG_ 2565509194 PgnRqst_4A_90 6;
BA_ "SPN" SG_ 2565509194 PgnRqst_4A_90 2540;
BA_ "CI_SigName" SG_ 2565509194 PgnRqst_4A_90 "Parameter Group Number (RQST)";
BA_ "CI_SigId" SG_ 2565509194 PgnRqst_4A_90 100043;
BA_ "CI_ParId" SG_ 2565509194 PgnRqst_4A_90 "2540";
BA_ "SigType" SG_ 2565509450 PgnRqst_4A_91 6;
BA_ "SPN" SG_ 2565509450 PgnRqst_4A_91 2540;
BA_ "CI_SigName" SG_ 2565509450 PgnRqst_4A_91 "Parameter Group Number (RQST)";
BA_ "CI_SigId" SG_ 2565509450 PgnRqst_4A_91 100045;
BA_ "CI_ParId" SG_ 2565509450 PgnRqst_4A_91 "2540";
BA_ "SigType" SG_ 2565509706 PgnRqst_4A_92 6;
BA_ "SPN" SG_ 2565509706 PgnRqst_4A_92 2540;
BA_ "CI_SigName" SG_ 2565509706 PgnRqst_4A_92 "Parameter Group Number (RQST)";
BA_ "CI_SigId" SG_ 2565509706 PgnRqst_4A_92 100047;
BA_ "CI_ParId" SG_ 2565509706 PgnRqst_4A_92 "2540";
BA_ "SigType" SG_ 2565512266 PgnRqst_4A_9C 6;
BA_ "SPN" SG_ 2565512266 PgnRqst_4A_9C 2540;
BA_ "CI_SigName" SG_ 2565512266 PgnRqst_4A_9C "Parameter Group Number (RQST)";
BA_ "CI_SigId" SG_ 2565512266 PgnRqst_4A_9C 100049;
BA_ "CI_ParId" SG_ 2565512266 PgnRqst_4A_9C "2540";
BA_ "SigType" SG_ 2565531722 PgnRqst_4A_E8 6;
BA_ "SPN" SG_ 2565531722 PgnRqst_4A_E8 2540;
BA_ "CI_SigName" SG_ 2565531722 PgnRqst_4A_E8 "Parameter Group Number (RQST)";
BA_ "CI_SigId" SG_ 2565531722 PgnRqst_4A_E8 100051;
BA_ "CI_ParId" SG_ 2565531722 PgnRqst_4A_E8 "2540";
BA_ "SigType" SG_ 2565533770 PgnRqst_4A_F0 6;
BA_ "SPN" SG_ 2565533770 PgnRqst_4A_F0 2540;
BA_ "CI_SigName" SG_ 2565533770 PgnRqst_4A_F0 "Parameter Group Number (RQST)";
BA_ "CI_SigId" SG_ 2565533770 PgnRqst_4A_F0 100053;
BA_ "CI_ParId" SG_ 2565533770 PgnRqst_4A_F0 "2540";
BA_ "SigType" SG_ 2565478730 PgnRqst_4A_19 6;
BA_ "SPN" SG_ 2565478730 PgnRqst_4A_19 2540;
BA_ "CI_SigName" SG_ 2565478730 PgnRqst_4A_19 "Parameter Group Number (RQST)";
BA_ "CI_SigId" SG_ 2565478730 PgnRqst_4A_19 100055;
BA_ "CI_ParId" SG_ 2565478730 PgnRqst_4A_19 "2540";
BA_ "SigType" SG_ 2565487178 PgnRqst_4A_3A 6;
BA_ "SPN" SG_ 2565487178 PgnRqst_4A_3A 2540;
BA_ "CI_SigName" SG_ 2565487178 PgnRqst_4A_3A "Parameter Group Number (RQST)";
BA_ "CI_SigId" SG_ 2565487178 PgnRqst_4A_3A 100057;
BA_ "CI_ParId" SG_ 2565487178 PgnRqst_4A_3A "2540";
BA_ "SigType" SG_ 2565505098 PgnRqst_4A_80 6;
BA_ "SPN" SG_ 2565505098 PgnRqst_4A_80 2540;
BA_ "CI_SigName" SG_ 2565505098 PgnRqst_4A_80 "Parameter Group Number (RQST)";
BA_ "CI_SigId" SG_ 2565505098 PgnRqst_4A_80 100059;
BA_ "CI_ParId" SG_ 2565505098 PgnRqst_4A_80 "2540";
BA_ "SigType" SG_ 2565489994 PgnRqst_4A_45 6;
BA_ "SPN" SG_ 2565489994 PgnRqst_4A_45 2540;
BA_ "CI_SigName" SG_ 2565489994 PgnRqst_4A_45 "Parameter Group Number (RQST)";
BA_ "CI_SigId" SG_ 2565489994 PgnRqst_4A_45 100061;
BA_ "CI_ParId" SG_ 2565489994 PgnRqst_4A_45 "2540";
BA_ "SigType" SG_ 2565501514 PgnRqst_4A_72 6;
BA_ "SPN" SG_ 2565501514 PgnRqst_4A_72 2540;
BA_ "CI_SigName" SG_ 2565501514 PgnRqst_4A_72 "Parameter Group Number (RQST)";
BA_ "CI_SigId" SG_ 2565501514 PgnRqst_4A_72 100063;
BA_ "CI_ParId" SG_ 2565501514 PgnRqst_4A_72 "2540";
BA_ "SigType" SG_ 2565476170 PgnRqst_4A_0F 6;
BA_ "SPN" SG_ 2565476170 PgnRqst_4A_0F 2540;
BA_ "CI_SigName" SG_ 2565476170 PgnRqst_4A_0F "Parameter Group Number (RQST)";
BA_ "CI_SigId" SG_ 2565476170 PgnRqst_4A_0F 100065;
BA_ "CI_ParId" SG_ 2565476170 PgnRqst_4A_0F "2540";
BA_ "SigType" SG_ 2565533514 PgnRqst_4A_EF 6;
BA_ "SPN" SG_ 2565533514 PgnRqst_4A_EF 2540;
BA_ "CI_SigName" SG_ 2565533514 PgnRqst_4A_EF "Parameter Group Number (RQST)";
BA_ "CI_SigId" SG_ 2565533514 PgnRqst_4A_EF 100067;
BA_ "CI_ParId" SG_ 2565533514 PgnRqst_4A_EF "2540";
BA_ "SigType" SG_ 2565531466 PgnRqst_4A_E7 6;
BA_ "SPN" SG_ 2565531466 PgnRqst_4A_E7 2540;
BA_ "CI_SigName" SG_ 2565531466 PgnRqst_4A_E7 "Parameter Group Number (RQST)";
BA_ "CI_SigId" SG_ 2565531466 PgnRqst_4A_E7 100069;
BA_ "CI_ParId" SG_ 2565531466 PgnRqst_4A_E7 "2540";
BA_ "SigType" SG_ 2565501258 PgnRqst_4A_71 6;
BA_ "SPN" SG_ 2565501258 PgnRqst_4A_71 2540;
BA_ "CI_SigName" SG_ 2565501258 PgnRqst_4A_71 "Parameter Group Number (RQST)";
BA_ "CI_SigId" SG_ 2565501258 PgnRqst_4A_71 100071;
BA_ "CI_ParId" SG_ 2565501258 PgnRqst_4A_71 "2540";
BA_ "SigType" SG_ 2565537610 PgnRqst_4A_FF 6;
BA_ "SPN" SG_ 2565537610 PgnRqst_4A_FF 2540;
BA_ "CI_SigName" SG_ 2565537610 PgnRqst_4A_FF "Parameter Group Number (RQST)";
BA_ "CI_SigId" SG_ 2565537610 PgnRqst_4A_FF 100073;
BA_ "CI_ParId" SG_ 2565537610 PgnRqst_4A_FF "2540";
BA_ "CI_SigName" SG_ 2566913797 PlaceHolder_05 "PlaceHolder signal";
BA_ "CI_SigId" SG_ 2566913797 PlaceHolder_05 100075;
BA_ "CI_SigName" SG_ 2566913841 PlaceHolder_31 "PlaceHolder signal";
BA_ "CI_SigId" SG_ 2566913841 PlaceHolder_31 100077;
BA_ "CI_SigName" SG_ 2566913909 PlaceHolder_75 "PlaceHolder signal";
BA_ "CI_SigId" SG_ 2566913909 PlaceHolder_75 100079;
BA_ "CI_SigName" SG_ 2566913818 PlaceHolder_1A "PlaceHolder signal";
BA_ "CI_SigId" SG_ 2566913818 PlaceHolder_1A 100081;
BA_ "CI_SigName" SG_ 2566913829 PlaceHolder_25 "PlaceHolder signal";
BA_ "CI_SigId" SG_ 2566913829 PlaceHolder_25 100083;
BA_ "CI_SigName" SG_ 2566913888 PlaceHolder_60 "PlaceHolder signal";
BA_ "CI_SigId" SG_ 2566913888 PlaceHolder_60 100085;
BA_ "CI_SigName" SG_ 2566913890 PlaceHolder_62 "PlaceHolder signal";
BA_ "CI_SigId" SG_ 2566913890 PlaceHolder_62 100087;
BA_ "CI_SigName" SG_ 2566913926 PlaceHolder_86 "PlaceHolder signal";
BA_ "CI_SigId" SG_ 2566913926 PlaceHolder_86 100089;
BA_ "CI_SigName" SG_ 2566913927 PlaceHolder_87 "PlaceHolder signal";
BA_ "CI_SigId" SG_ 2566913927 PlaceHolder_87 100091;
BA_ "CI_SigName" SG_ 2566913928 PlaceHolder_88 "PlaceHolder signal";
BA_ "CI_SigId" SG_ 2566913928 PlaceHolder_88 100093;
BA_ "CI_SigName" SG_ 2566913929 PlaceHolder_89 "PlaceHolder signal";
BA_ "CI_SigId" SG_ 2566913929 PlaceHolder_89 100095;
BA_ "CI_SigName" SG_ 2566913930 PlaceHolder_8A "PlaceHolder signal";
BA_ "CI_SigId" SG_ 2566913930 PlaceHolder_8A 100097;
BA_ "CI_SigName" SG_ 2566913931 PlaceHolder_8B "PlaceHolder signal";
BA_ "CI_SigId" SG_ 2566913931 PlaceHolder_8B 100099;
BA_ "CI_SigName" SG_ 2566913932 PlaceHolder_8C "PlaceHolder signal";
BA_ "CI_SigId" SG_ 2566913932 PlaceHolder_8C 100101;
BA_ "CI_SigName" SG_ 2566913933 PlaceHolder_8D "PlaceHolder signal";
BA_ "CI_SigId" SG_ 2566913933 PlaceHolder_8D 100103;
VAL_ 2566870597 DCDC_12V_ConvFault 0 "Off" 1 "On" ;
VAL_ 2566870597 OverheatingComprElec 0 "OFF" 1 "ON" ;
VAL_ 2566870597 AirDryerSts 0 "OFF" 1 "ON" ;
VAL_ 2566870597 Door4ActvInEmerMode 0 "Not activated" 1 "Activated" ;
VAL_ 2566870597 Door3ActvInEmerMode 0 "Not activated" 1 "Activated" ;
VAL_ 2566870597 Door2ActvInEmerMode 0 "Not activated" 1 "Activated" ;
VAL_ 2566870597 Door1ActvInEmerMode 0 "Not activated" 1 "Activated" ;
VAL_ 2566870597 Door4EmerInh 0 "Not activated" 1 "Activated" ;
VAL_ 2566870597 Door3EmerInh 0 "Not activated" 1 "Activated" ;
VAL_ 2566870597 Door2EmerInh 0 "Not activated" 1 "Activated" ;
VAL_ 2566870597 Door1EmerInh 0 "Not activated" 1 "Activated" ;
VAL_ 2566870597 EmerBtnSts 0 "Not activated" 1 "Activated" ;
VAL_ 2566870597 FipoSts 0 "OFF" 1 "ON" 2 "ERROR" ;
VAL_ 2566870597 FaeSts 0 "OFF" 1 "ON" 2 "ERROR" ;
VAL_ 2566870597 ParkBrkSwFullyApplied 0 "OFF" 1 "ON" ;
VAL_ 2566870597 HeatSysHighTempFault 0 "OFF" 1 "ON" ;
VAL_ 2566870597 HeatFuelLowLev 0 "OFF" 1 "ON" ;
VAL_ 2566870597 HeatLiquidLowLev 0 "OFF" 1 "ON" ;
VAL_ 2566870597 VehMode 0 "Standby" 1 "Drive" 2 "Overnight Charging" 3 "Opportunity Charging" 4 "Reserved" 5 "Reserved" 6 "Reserved" 7 "Not Available" ;
VAL_ 2566854469 OilMaintenanceReset 0 "NoReset" 1 "ResetPerformed" 2 "Reserved" 3 "NotAvailable" ;
VAL_ 2566854469 OilMaintenanceAlert 0 "OFF" 1 "MaintenanceNeeded" 2 "MaintenanceDelayExceeded" 3 "NotAvailable" ;
VAL_ 2566854469 PropellerShaftOverspeedAlert 0 "OFF" 1 "ON" ;
VAL_ 2566854469 _3RdAxleOvl 0 "OFF" 1 "ON" ;
VAL_ 2566854469 _3RdAxleOilLevLow 0 "OFF" 1 "ON" ;
VAL_ 2566854469 _3RdAxlePrsLow 0 "OFF" 1 "ON" ;
VAL_ 2566854469 NoBat3Recharge 0 "OFF" 1 "ON" ;
VAL_ 2566854469 NoBat2Recharge 0 "OFF" 1 "ON" ;
VAL_ 2566854469 NoBat1Recharge 0 "OFF" 1 "ON" ;
VAL_ 2566906905 ElHtrOverheatingWarn 0 "OK_AlarmNotActive" 1 "Alarm active" 2 "Not used" 3 "Not available" ;
VAL_ 2566906905 ElHtrHvRelayDamaged 0 "OK_AlarmNotActive" 1 "Alarm active" 2 "Not used" 3 "Not available" ;
VAL_ 2566906905 ElHtrOverheating 0 "OK_AlarmNotActive" 1 "Alarm active" 2 "Not used" 3 "Not available" ;
VAL_ 2566906905 StartStopInhibMildHybrid 1 "SS_Enabled" 3 "SS_Blocked" ;
VAL_ 2566906905 ElHtrSts 0 "not active" 1 "active" 2 "error" 3 "not available" ;
VAL_ 2566906905 ThermHtrSts 0 "not active" 1 "active" 2 "error" 3 "not available" ;
VAL_ 2566906905 CirculationSts 0 "not circulating" 1 "circulating" 2 "error" 3 "not available." ;
VAL_ 2566906905 AcComprInvActvReq 0 "no request" 1 "request a/c compressor on" 3 "not available." ;
VAL_ 2566846467 TransmOilTemp1 65024 "Error" 65535 "Not_Available" ;
VAL_ 2566749463 LdwSwdOff 0 "Off" 1 "Cond. Red" 2 "Cond. Yellow" 3 "Cond. Info" 7 "Not Available" ;
VAL_ 2566749463 EngCompTemp 0 "Off" 1 "Cond. Red" 2 "Cond. Yellow" 3 "Cond. Info" 7 "Not Available" ;
VAL_ 2566749463 SteerFluidLev 0 "Off" 1 "Cond. Red" 2 "Cond. Yellow" 3 "Cond. Info" 7 "Not Available" ;
VAL_ 2566749463 FrontFogLight 0 "Off" 1 "Cond. Red" 2 "Cond. Yellow" 3 "Cond. Info" 7 "Not Available" ;
VAL_ 2566749463 EscSwdOff 0 "Off" 1 "Cond. Red" 2 "Cond. Yellow" 3 "Cond. Info" 7 "Not Available" ;
VAL_ 2566749463 Kneel 0 "Off" 1 "Cond. Red" 2 "Cond. Yellow" 3 "Cond. Info" 7 "Not Available" ;
VAL_ 2566749463 EngCoolLev 0 "Off" 1 "Cond. Red" 2 "Cond. Yellow" 3 "Cond. Info" 7 "Not Available" ;
VAL_ 2566749463 PosLightSideLight 0 "Off" 1 "Cond. Red" 2 "Cond. Yellow" 3 "Cond. Info" 7 "Not Available" ;
VAL_ 2566749463 TcoInd 0 "Off" 1 "Cond. Red" 2 "Cond. Yellow" 3 "Cond. Info" 7 "Not Available" ;
VAL_ 2566749463 Low 0 "Off" 1 "Cond. Red" 2 "Cond. Yellow" 3 "Cond. Info" 7 "Not Available" ;
VAL_ 2566749463 EngOilLev_FD7D17 0 "Off" 1 "Cond. Red" 2 "Cond. Yellow" 3 "Cond. Info" 7 "Not Available" ;
VAL_ 2566749463 EngOil 0 "Off" 1 "Cond. Red" 2 "Cond. Yellow" 3 "Cond. Info" 7 "Not Available" ;
VAL_ 2566749463 EbsTrail12 0 "Off" 1 "Cond. Red" 2 "Cond. Yellow" 3 "Cond. Info" 7 "Not Available" ;
VAL_ 2566749463 Raising 0 "Off" 1 "Cond. Red" 2 "Cond. Yellow" 3 "Cond. Info" 7 "Not Available" ;
VAL_ 2566749463 EngOilTemp 0 "Off" 1 "Cond. Red" 2 "Cond. Yellow" 3 "Cond. Info" 7 "Not Available" ;
VAL_ 2566749463 BatChgCond 0 "Off" 1 "Cond. Red" 2 "Cond. Yellow" 3 "Cond. Info" 7 "Not Available" ;
VAL_ 2566749463 Airbag 0 "Off" 1 "Cond. Red" 2 "Cond. Yellow" 3 "Cond. Info" 7 "Not Available" ;
VAL_ 2566749463 AdblueLev 0 "Off" 1 "Cond. Red" 2 "Cond. Yellow" 3 "Cond. Info" 7 "Not Available" ;
VAL_ 2566749463 Malf_GenFail 0 "Off" 1 "Cond. Red" 2 "Cond. Yellow" 3 "Cond. Info" 7 "Not Available" ;
VAL_ 2566749463 EngCoolTemp_FD7D17 0 "Off" 1 "Cond. Red" 2 "Cond. Yellow" 3 "Cond. Info" 7 "Not Available" ;
VAL_ 2566749463 AbsTrail12 0 "Off" 1 "Cond. Red" 2 "Cond. Yellow" 3 "Cond. Info" 7 "Not Available" ;
VAL_ 2566749463 BusStopBrk 0 "Off" 1 "Cond. Red" 2 "Cond. Yellow" 3 "Cond. Info" 7 "Not Available" ;
VAL_ 2566749463 TireFail_Malf 0 "Off" 1 "Cond. Red" 2 "Cond. Yellow" 3 "Cond. Info" 7 "Not Available" ;
VAL_ 2566749463 FuelLev 0 "Off" 1 "Cond. Red" 2 "Cond. Yellow" 3 "Cond. Info" 7 "Not Available" ;
VAL_ 2566749463 BatPakCool 0 "Off" 1 "Cond. Red" 2 "Cond. Yellow" 3 "Cond. Info" 4 "Reserved" 5 "Reserved" 6 "Reserved" 7 "Not Available" ;
VAL_ 2566749463 TrailConn 0 "Off" 1 "Cond. Red" 2 "Cond. Yellow" 3 "Cond. Info" 7 "Not Available" ;
VAL_ 2566749463 PramReq 0 "Off" 1 "Cond. Red" 2 "Cond. Yellow" 3 "Cond. Info" 7 "Not Available" ;
VAL_ 2566749463 Windsh_WindshWasherFluid 0 "Off" 1 "Cond. Red" 2 "Cond. Yellow" 3 "Cond. Info" 7 "Not Available" ;
VAL_ 2566749463 HatchOpen 0 "Off" 1 "Cond. Red" 2 "Cond. Yellow" 3 "Cond. Info" 7 "Not Available" ;
VAL_ 2566749463 LimPerfElMot 0 "Off" 1 "Cond. Red" 2 "Cond. Yellow" 3 "Cond. Info" 4 "Reserved" 5 "Reserved" 6 "Reserved" 7 "Not Available" ;
VAL_ 2566749463 Acc 0 "Off" 1 "Cond. Red" 2 "Cond. Yellow" 3 "Cond. Info" 7 "Not Available" ;
VAL_ 2566749463 StopReq 0 "Off" 1 "Cond. Red" 2 "Cond. Yellow" 3 "Cond. Info" 7 "Not Available" ;
VAL_ 2566749463 WornBrkLin 0 "Off" 1 "Cond. Red" 2 "Cond. Yellow" 3 "Cond. Info" 7 "Not Available" ;
VAL_ 2566749463 BrkFail_BrkSysMalf 0 "Off" 1 "Cond. Red" 2 "Cond. Yellow" 3 "Cond. Info" 7 "Not Available" ;
VAL_ 2566749463 BatPakTemp 0 "Off" 1 "Cond. Red" 2 "Cond. Yellow" 3 "Cond. Info" 4 "Reserved" 5 "Reserved" 6 "Reserved" 7 "Not Available" ;
VAL_ 2566749463 Aebs 0 "Off" 1 "Cond. Red" 2 "Cond. Yellow" 3 "Cond. Info" 7 "Not Available" ;
VAL_ 2566749463 Artic 0 "Off" 1 "Cond. Red" 2 "Cond. Yellow" 3 "Cond. Info" 7 "Not Available" ;
VAL_ 2566749463 AntiLckBrkSysFail 0 "Off" 1 "Cond. Red" 2 "Cond. Yellow" 3 "Cond. Info" 7 "Not Available" ;
VAL_ 2566749463 ParkBrk 0 "Off" 1 "Cond. Red" 2 "Cond. Yellow" 3 "Cond. Info" 7 "Not Available" ;
VAL_ 2566749463 highVsysCaution 0 "Off" 1 "Cond. Red" 2 "Cond. Yellow" 3 "Cond. Info" 4 "Reserved" 5 "Reserved" 6 "Reserved" 7 "Not Available" ;
VAL_ 2566749463 LaneDepInd 0 "Off" 1 "Cond. Red" 2 "Cond. Yellow" 3 "Cond. Info" 7 "Not Available" ;
VAL_ 2566749463 BrkLight 0 "Off" 1 "Cond. Red" 2 "Cond. Yellow" 3 "Cond. Info" 7 "Not Available" ;
VAL_ 2566749463 TransmFail_Malf 0 "Off" 1 "Cond. Red" 2 "Cond. Yellow" 3 "Cond. Info" 7 "Not Available" ;
VAL_ 2566749463 ProvDisOrHandiPers 0 "Off" 1 "Cond. Red" 2 "Cond. Yellow" 3 "Cond. Info" 7 "Not Available" ;
VAL_ 2566749463 BatPak 0 "Off" 1 "Cond. Red" 2 "Cond. Yellow" 3 "Cond. Info" 4 "Reserved" 5 "Reserved" 6 "Reserved" 7 "Not Available" ;
VAL_ 2566749463 Ebs 0 "Off" 1 "Cond. Red" 2 "Cond. Yellow" 3 "Cond. Info" 7 "Not Available" ;
VAL_ 2566749463 EscInd 0 "Off" 1 "Cond. Red" 2 "Cond. Yellow" 3 "Cond. Info" 7 "Not Available" ;
VAL_ 2566749463 TransmFluidTemp 0 "Off" 1 "Cond. Red" 2 "Cond. Yellow" 3 "Cond. Info" 7 "Not Available" ;
VAL_ 2566749463 HazardWarn 0 "Off" 1 "Cond. Red" 2 "Cond. Yellow" 3 "Cond. Info" 7 "Not Available" ;
VAL_ 2566749463 MuxSys 0 "Off" 1 "Cond. Red" 2 "Cond. Yellow" 3 "Cond. Info" 7 "Not Available" ;
VAL_ 2566749463 SeatBelt 0 "Off" 1 "Cond. Red" 2 "Cond. Yellow" 3 "Cond. Info" 7 "Not Available" ;
VAL_ 2566749463 EngEmisSysFailMil 0 "Off" 1 "Cond. Red" 2 "Cond. Yellow" 3 "Cond. Info" 7 "Not Available" ;
VAL_ 2566749463 ServCallForMaint 0 "Off" 1 "Cond. Red" 2 "Cond. Yellow" 3 "Cond. Info" 7 "Not Available" ;
VAL_ 2566749463 TurnSigs 0 "Off" 1 "Cond. Red" 2 "Cond. Yellow" 3 "Cond. Info" 7 "Not Available" ;
VAL_ 2566749463 AdblueTamp 0 "Off" 1 "Cond. Red" 2 "Cond. Yellow" 3 "Cond. Info" 7 "Not Available" ;
VAL_ 2566749463 FuelFiltDiffPrs 0 "Off" 1 "Cond. Red" 2 "Cond. Yellow" 3 "Cond. Info" 7 "Not Available" ;
VAL_ 2566749463 Ret 0 "Off" 1 "Cond. Red" 2 "Cond. Yellow" 3 "Cond. Info" 7 "Not Available" ;
VAL_ 2566749463 Eng_Mil 0 "Off" 1 "Cond. Red" 2 "Cond. Yellow" 3 "Cond. Info" 7 "Not Available" ;
VAL_ 2566749463 LowBeamDipBeam 0 "Off" 1 "Cond. Red" 2 "Cond. Yellow" 3 "Cond. Info" 7 "Not Available" ;
VAL_ 2566749463 ElMotFails 0 "Off" 1 "Cond. Red" 2 "Cond. Yellow" 3 "Cond. Info" 7 "Not Available" ;
VAL_ 2566749463 AirFiltClog 0 "Off" 1 "Cond. Red" 2 "Cond. Yellow" 3 "Cond. Info" 7 "Not Available" ;
VAL_ 2566749463 HtCtrl 0 "Off" 1 "Cond. Red" 2 "Cond. Yellow" 3 "Cond. Info" 7 "Not Available" ;
VAL_ 2566749463 ParkHeat 0 "Off" 1 "Cond. Red" 2 "Cond. Yellow" 3 "Cond. Info" 7 "Not Available" ;
VAL_ 2566749463 HighBeamMainBeam 0 "Off" 1 "Cond. Red" 2 "Cond. Yellow" 3 "Cond. Info" 7 "Not Available" ;
VAL_ 2566749463 EngEmisFilt 0 "Off" 1 "Cond. Red" 2 "Cond. Yellow" 3 "Cond. Info" 7 "Not Available" ;
VAL_ 2566749463 AuxAirPrs 0 "Off" 1 "Cond. Red" 2 "Cond. Yellow" 3 "Cond. Info" 7 "Not Available" ;
VAL_ 2566749463 SteerFail 0 "Off" 1 "Cond. Red" 2 "Cond. Yellow" 3 "Cond. Info" 7 "Not Available" ;
VAL_ 2566749463 RearFogLight 0 "Off" 1 "Cond. Red" 2 "Cond. Yellow" 3 "Cond. Info" 7 "Not Available" ;
VAL_ 2566749463 CoolAc 0 "Off" 1 "Cond. Red" 2 "Cond. Yellow" 3 "Cond. Info" 7 "Not Available" ;
VAL_ 2566749463 TtBlkId 0 "Block ID0" 1 "Block ID1" 2 "Block ID2" 3 "Block ID3" 4 "Block ID4" 5 "Reserved" 6 "Reserved" 7 "Not Available" ;
VAL_ 2566884426 AllTheDataRemoval 0 "NoRequest" 1 "RequestIsActive" ;
VAL_ 2566884426 SwIdReq 0 "NoRequest" 1 "RequestIsActive" ;
VAL_ 2566884426 CompIdReq 0 "NoRequest" 1 "RequestIsActive" ;
VAL_ 2566884426 EcuIdReq 0 "NoRequest" 1 "RequestIsActive" ;
VAL_ 2566884426 DeferredDataReq 0 "NoRequest" 1 "RequestIsActive" ;
VAL_ 2566877568 FillAuthorizDueToSafetyReas 0 "Filling is allowed" 1 "FillingStrictlyForbidSafetyReas" ;
VAL_ 2566877568 NrTanksOpenH2_RdyToProvide2FC 0 "no tanks open" 1 "1 tank open" 2 "2 tanks open" 3 "3 tanks open" 4 "4 tanks open" ;
VAL_ 2566877568 FC_Mode_ReqBySupervisor 0 "Vehicle in standby (+24V)" 1 "FC Run Command Start" 2 "FC Power delivery" 3 "FC Stop Command (Shut Down)" 4 "Idle stop" 5 "Idle stop (not used)" 6 "FC Stop CommWithH2TankClosed" 7 "FC StopCommH2 leakDetSupervisor" 8 "FC StopCommHV faultDetSupervisor" ;
VAL_ 2566877568 HV_DC_Link_Sts 0 "DC link Fault" 1 "Dc Linf OK" ;
VAL_ 2566877568 LimpHomeMode 0 "OverrideModeReqByDriver_allow" ;
VAL_ 2566877568 H2_Circuit_Sts 1 "H2CircCloseSafeWOsevereFault" 2 "not used" 3 "H2 CircCloseWithCriticalFaults" 4 "H2 CircOpenWithCriticalFaults" ;
VAL_ 2566877568 FC_Sts_SupervisorSide 0 "Standby Mode" 1 "Faulty in StandBy Mode" 2 "Start up process on going" 3 "Start up failed" 4 "Start up completed" 5 "ShutDownAfterStartUpFailed" 6 "ShutDown on going" 7 "ShutDownCompleted" 8 "FCFaultSDAfterStartupCompl" 9 "EmrgSDH2LeakFromFCUinHEVmode" 10 "EmrgSDIntlckReacFromFCU_HEVmode" 11 "Idle Stop" ;
VAL_ 2566877568 H2_Sensor4LeakageSts 0 "No H2 leakage detected" 1 "H2 leakage detected" ;
VAL_ 2566877568 H2_Sensor3LeakageSts 0 "No H2 leakage detected" 1 "H2 leakage detected" ;
VAL_ 2566877568 H2_Sensor2LeakageSts 0 "No H2 leakage detected" 1 "H2 leakage detected" ;
VAL_ 2566877568 H2_Sensor1LeakageSts 0 "No H2 leakage detected" 1 "H2 leakage detected" ;
VAL_ 2566877568 H2ConctValExc4Pc_RslR134 0 "OK" 1 "H2 Leakage of more than 4%" ;
VAL_ 2566877568 H2ConctValExc3Pc_AwlR134 0 "OK" 1 "H2 Leakage of more than 3%" ;
VAL_ 2566877568 FC_Act_DeacStsDashbDisplay 0 "No activation" 1 "FC activation on going" 2 "FC activated" 3 "FC deactivation on going" ;
VAL_ 2566877568 VCU_TkClosEmrgShtDwnRq_FC1 0 "None" 1 "Immediately stop" ;
VAL_ 2566877568 VCU_HV_FtEmrgShtDwnRq_FC1 0 "None" 1 "Immediately stop" ;
VAL_ 2566877568 FCU2_7_FC_StopState 0 "None_FC Stop release completed" 1 "during FC Stop" 2 "FC Stop completed" 3 "during FC Stop released" ;
VAL_ 2566877568 FCU2_7_FC_StopImposs 0 "None" 1 "FC Stop impossible" 2 "Reserved" 3 "Reserved" ;
VAL_ 2566877568 FCU2_5_FC_Fault 0 "None" 1 "Fault" ;
VAL_ 2566877568 FCU2_5_FC_Shutdown 0 "None" 1 "during shut-down" 2 "shut-down complete" 3 "reserved" ;
VAL_ 2566877568 FCU2_5_FC_LoadPermmit 0 "Not Permissive" 1 "Permissive" ;
VAL_ 2566877568 FCU2_5_FC_Startup 0 "None" 1 "during start-up" 2 "start-up complete" 3 "start-up fail" ;
VAL_ 2566877568 VCU_FC_CoolantLevLow 0 "Normal" 1 "Abnormal" ;
VAL_ 2566877568 FuelCellSwON_OFF 0 "Off" 1 "On" ;
VAL_ 2566877568 FCU2_H2TankValveEmrgClos 0 "None" 1 "Tank Close" ;
VAL_ 2566877568 FCU2_HV_InterlockReactRq 0 "None" 1 "InterlockReactionReq" ;
VAL_ 2566877568 FCU2_5_H2FaultLamp 0 "Off" 1 "On" ;
VAL_ 2566877568 FCU2_8_H2LeakLamp 0 "No Leak" 1 "Small Leak" 2 "Large Leak" 3 "Reserved" ;
VAL_ 2566877824 FDC1_2_FDC1_CoolTemp 254 "Error" 255 "Error" ;
VAL_ 2566878080 VCU_H2PressTank4 254 "not used" 255 "not available" ;
VAL_ 2566878080 VCU_H2PressTank3 254 "not used" 255 "not available" ;
VAL_ 2566878080 VCU_H2PressTank2 254 "not used" 255 "not available" ;
VAL_ 2566878080 VCU_H2PressTank1 254 "not used" 255 "not available" ;
VAL_ 2566878080 VCU_H2MidPress 0 "0xFF Not available" ;
VAL_ 2566878080 VCU_H2LowPress 0 "0xFF Not available" ;
VAL_ 2566878080 LeakTestsStsAtShtDwn 0 "LeakageTestAtShutDownOK" 1 "LeakageTestAtShutDownNOK" 2 "LeakTestAtShutDownOnGoing" ;
VAL_ 2566878080 LeakTestsStsAtStartUp 0 "Leakage test at start up OK" 1 "Leakage test at start up NOK" ;
VAL_ 2566878080 Sts_H2_Lines 0 "Operational" 1 "Not operational" ;
VAL_ 2566878080 Sts_ShutOff_Valve 0 "Operational" 1 "Not operational" ;
VAL_ 2566878080 Sts_HP_LP_PressSensors 0 "Operational" 1 "Not operational" ;
VAL_ 2566878592 CSP_Fill_PurgPrAllowBySuperv 0 "Not allowed" 1 "Allowed" 2 "Filling pump activated" ;
VAL_ 2566878592 Concentr_H2Capteur_I 0 "capteur H2 HMC#1 (if available)" 1 "capteur H21" 2 "capteur H22" 3 "capteur H23" 4 "capteur H24" 5 "capteur H25" 6 "capteur H26" 7 "capteur H2 HMC#2 (if available)" ;
VAL_ 2566878592 RefuelingMode 0 "No Refueling" 1 "Refueling with IRD or manually" ;
VAL_ 2566878592 FCU2_FC_CoolFilterCheck 0 "Off" 1 "On" ;
VAL_ 2566878592 FCU2_FC_CoolSupplyCheck 0 "Off" 1 "On" ;
VAL_ 2566878592 IRD_2_Sts 0 "Not supplied" 1 "SuppliedIn24V_FunctForCharg" 2 "ErrorComponentFaulty" 3 "Not available" ;
VAL_ 2566878592 IRD_1_Sts 0 "Not supplied" 1 "SuppliedIn24V_FunctForCharg" 2 "ErrorComponentFaulty" 3 "Not available" ;
VAL_ 2566878592 H2_sensor_6_leakage_Sts 0 "No H2 leakage detected" 1 "H2 leakage detected" ;
VAL_ 2566878592 H2_sensor_5_leakage_Sts 0 "No H2 leakage detected" 1 "H2 leakage detected" ;
VAL_ 2566878592 H2_Refuel_plug_2 0 "closed and locked" 1 "closed and unlocked" 2 "open" 3 "ErrorOn H2Plug (sensor_lock)" ;
VAL_ 2566878592 H2_Refuel_plug_1 0 "closed and locked" 1 "closed and unlocked" 2 "open" 3 "ErrorOn H2Plug (sensor_lock)" ;
VAL_ 2566878592 H2_Temp_tank_4 254 "Error" 255 "Error" ;
VAL_ 2566878592 H2_Temp_tank_3 254 "Error" 255 "Error" ;
VAL_ 2566878592 H2_Temp_tank_2 254 "Error" 255 "Error" ;
VAL_ 2566878592 H2_Temp_tank_1 254 "Error" 255 "Error" ;
VAL_ 2566803211 VdcFullyOp 0 "Not fully operational" 1 "Fully operational" 2 "Reserved" 3 "Don’t Care / Take no action" ;
VAL_ 2566803211 VdcInfoSig 0 "Off" 1 "On" 2 "Reserved" 3 "Don’t Care / Take no action" ;
VAL_ 2566842927 Axle_Location 0 "Axle 1" 1 "Axle 2" 2 "Axle 3" 3 "Axle 4" 4 "Axle 5" ;
VAL_ 2566842944 Axle_Location_FEEA40 0 "Axle 1" 1 "Axle 2" 2 "Axle 3" 3 "Axle 4" 4 "Axle 5" ;
VAL_ 2566848256 WaterInFuelInd1 0 "No" 1 "Yes" 2 "Error" 3 "Not Available" ;
